VERSION ""

NS_ :

BS_:

BU_: FR C3B

BO_ 557 FR_22D: 64 FR
 SG_ FR_CRCCheck_22D : 503|16@0+ (1,0) [0|65535] ""  C3B
 SG_ FR_RollingCounter_22D : 491|4@0+ (1,0) [0|15] ""  C3B
 SG_ FR_FreespaceSectorKinestate204 : 477|2@0+ (1,0) [0|3] "-"  C3B
 SG_ FR_FreespaceSectorConRidence204 : 479|2@0+ (1,0) [0|3] "-"  C3B
 SG_ FR_FreespaceSectorDistance204 : 457|10@0+ (0.1,0) [0|100] "-"  C3B
 SG_ FR_FreespaceSectorKinestate203 : 459|2@0+ (1,0) [0|3] "-"  C3B
 SG_ FR_FreespaceSectorConRidence203 : 461|2@0+ (1,0) [0|3] "-"  C3B
 SG_ FR_FreespaceSectorDistance203 : 455|10@0+ (0.1,0) [0|100] "-"  C3B
 SG_ FR_FreespaceSectorKinestate202 : 441|2@0+ (1,0) [0|3] "-"  C3B
 SG_ FR_FreespaceSectorConRidence202 : 443|2@0+ (1,0) [0|3] "-"  C3B
 SG_ FR_FreespaceSectorDistance202 : 437|10@0+ (0.1,0) [0|100] "-"  C3B
 SG_ FR_FreespaceSectorKinestate201 : 439|2@0+ (1,0) [0|3] "-"  C3B
 SG_ FR_FreespaceSectorConRidence201 : 425|2@0+ (1,0) [0|3] "-"  C3B
 SG_ FR_FreespaceSectorDistance201 : 419|10@0+ (0.1,0) [0|100] "-"  C3B
 SG_ FR_FreespaceSectorKinestate200 : 421|2@0+ (1,0) [0|3] "-"  C3B
 SG_ FR_FreespaceSectorConRidence200 : 423|2@0+ (1,0) [0|3] "-"  C3B
 SG_ FR_FreespaceSectorDistance200 : 401|10@0+ (0.1,0) [0|100] "-"  C3B
 SG_ FR_FreespaceSectorKinestate199 : 403|2@0+ (1,0) [0|3] "-"  C3B
 SG_ FR_FreespaceSectorConRidence199 : 405|2@0+ (1,0) [0|3] "-"  C3B
 SG_ FR_FreespaceSectorDistance199 : 399|10@0+ (0.1,0) [0|100] "-"  C3B
 SG_ FR_FreespaceSectorKinestate198 : 385|2@0+ (1,0) [0|3] "-"  C3B
 SG_ FR_FreespaceSectorConRidence198 : 387|2@0+ (1,0) [0|3] "-"  C3B
 SG_ FR_FreespaceSectorDistance198 : 381|10@0+ (0.1,0) [0|100] "-"  C3B
 SG_ FR_FreespaceSectorKinestate197 : 383|2@0+ (1,0) [0|3] "-"  C3B
 SG_ FR_FreespaceSectorConRidence197 : 369|2@0+ (1,0) [0|3] "-"  C3B
 SG_ FR_FreespaceSectorDistance197 : 363|10@0+ (0.1,0) [0|100] "-"  C3B
 SG_ FR_FreespaceSectorKinestate196 : 365|2@0+ (1,0) [0|3] "-"  C3B
 SG_ FR_FreespaceSectorConRidence196 : 367|2@0+ (1,0) [0|3] "-"  C3B
 SG_ FR_FreespaceSectorDistance196 : 345|10@0+ (0.1,0) [0|100] "-"  C3B
 SG_ FR_FreespaceSectorKinestate195 : 347|2@0+ (1,0) [0|3] "-"  C3B
 SG_ FR_FreespaceSectorConRidence195 : 349|2@0+ (1,0) [0|3] "-"  C3B
 SG_ FR_FreespaceSectorDistance195 : 343|10@0+ (0.1,0) [0|100] "-"  C3B
 SG_ FR_FreespaceSectorKinestate194 : 329|2@0+ (1,0) [0|3] "-"  C3B
 SG_ FR_FreespaceSectorConRidence194 : 331|2@0+ (1,0) [0|3] "-"  C3B
 SG_ FR_FreespaceSectorDistance194 : 325|10@0+ (0.1,0) [0|100] "-"  C3B
 SG_ FR_FreespaceSectorKinestate193 : 327|2@0+ (1,0) [0|3] "-"  C3B
 SG_ FR_FreespaceSectorConRidence193 : 313|2@0+ (1,0) [0|3] "-"  C3B
 SG_ FR_FreespaceSectorDistance193 : 307|10@0+ (0.1,0) [0|100] "-"  C3B
 SG_ FR_FreespaceSectorKinestate192 : 309|2@0+ (1,0) [0|3] "-"  C3B
 SG_ FR_FreespaceSectorConRidence192 : 311|2@0+ (1,0) [0|3] "-"  C3B
 SG_ FR_FreespaceSectorDistance192 : 289|10@0+ (0.1,0) [0|100] "-"  C3B
 SG_ FR_FreespaceSectorKinestate191 : 291|2@0+ (1,0) [0|3] "-"  C3B
 SG_ FR_FreespaceSectorConRidence191 : 293|2@0+ (1,0) [0|3] "-"  C3B
 SG_ FR_FreespaceSectorDistance191 : 287|10@0+ (0.1,0) [0|100] "-"  C3B
 SG_ FR_FreespaceSectorKinestate190 : 273|2@0+ (1,0) [0|3] "-"  C3B
 SG_ FR_FreespaceSectorConRidence190 : 275|2@0+ (1,0) [0|3] "-"  C3B
 SG_ FR_FreespaceSectorDistance190 : 269|10@0+ (0.1,0) [0|100] "-"  C3B
 SG_ FR_FreespaceSectorKinestate189 : 271|2@0+ (1,0) [0|3] "-"  C3B
 SG_ FR_FreespaceSectorConRidence189 : 257|2@0+ (1,0) [0|3] "-"  C3B
 SG_ FR_FreespaceSectorDistance189 : 251|10@0+ (0.1,0) [0|100] "-"  C3B
 SG_ FR_FreespaceSectorKinestate188 : 253|2@0+ (1,0) [0|3] "-"  C3B
 SG_ FR_FreespaceSectorConRidence188 : 255|2@0+ (1,0) [0|3] "-"  C3B
 SG_ FR_FreespaceSectorDistance188 : 233|10@0+ (0.1,0) [0|100] "-"  C3B
 SG_ FR_FreespaceSectorKinestate187 : 235|2@0+ (1,0) [0|3] "-"  C3B
 SG_ FR_FreespaceSectorConRidence187 : 237|2@0+ (1,0) [0|3] "-"  C3B
 SG_ FR_FreespaceSectorDistance187 : 231|10@0+ (0.1,0) [0|100] "-"  C3B
 SG_ FR_FreespaceSectorKinestate186 : 217|2@0+ (1,0) [0|3] "-"  C3B
 SG_ FR_FreespaceSectorConRidence186 : 219|2@0+ (1,0) [0|3] "-"  C3B
 SG_ FR_FreespaceSectorDistance186 : 213|10@0+ (0.1,0) [0|100] "-"  C3B
 SG_ FR_FreespaceSectorKinestate185 : 215|2@0+ (1,0) [0|3] "-"  C3B
 SG_ FR_FreespaceSectorConRidence185 : 201|2@0+ (1,0) [0|3] "-"  C3B
 SG_ FR_FreespaceSectorDistance185 : 195|10@0+ (0.1,0) [0|100] "-"  C3B
 SG_ FR_FreespaceSectorKinestate184 : 197|2@0+ (1,0) [0|3] "-"  C3B
 SG_ FR_FreespaceSectorConRidence184 : 199|2@0+ (1,0) [0|3] "-"  C3B
 SG_ FR_FreespaceSectorDistance184 : 177|10@0+ (0.1,0) [0|100] "-"  C3B
 SG_ FR_FreespaceSectorKinestate183 : 179|2@0+ (1,0) [0|3] "-"  C3B
 SG_ FR_FreespaceSectorConRidence183 : 181|2@0+ (1,0) [0|3] "-"  C3B
 SG_ FR_FreespaceSectorDistance183 : 175|10@0+ (0.1,0) [0|100] "-"  C3B
 SG_ FR_FreespaceSectorKinestate182 : 161|2@0+ (1,0) [0|3] "-"  C3B
 SG_ FR_FreespaceSectorConRidence182 : 163|2@0+ (1,0) [0|3] "-"  C3B
 SG_ FR_FreespaceSectorDistance182 : 157|10@0+ (0.1,0) [0|100] "-"  C3B
 SG_ FR_FreespaceSectorKinestate181 : 159|2@0+ (1,0) [0|3] "-"  C3B
 SG_ FR_FreespaceSectorConRidence181 : 145|2@0+ (1,0) [0|3] "-"  C3B
 SG_ FR_FreespaceSectorDistance181 : 139|10@0+ (0.1,0) [0|100] "-"  C3B
 SG_ FR_FreespaceSectorKinestate180 : 141|2@0+ (1,0) [0|3] "-"  C3B
 SG_ FR_FreespaceSectorConRidence180 : 143|2@0+ (1,0) [0|3] "-"  C3B
 SG_ FR_FreespaceSectorDistance180 : 121|10@0+ (0.1,0) [0|100] "-"  C3B
 SG_ FR_FreespaceSectorKinestate179 : 123|2@0+ (1,0) [0|3] "-"  C3B
 SG_ FR_FreespaceSectorConRidence179 : 125|2@0+ (1,0) [0|3] "-"  C3B
 SG_ FR_FreespaceSectorDistance179 : 119|10@0+ (0.1,0) [0|100] "-"  C3B
 SG_ FR_FreespaceSectorKinestate178 : 105|2@0+ (1,0) [0|3] "-"  C3B
 SG_ FR_FreespaceSectorConRidence178 : 107|2@0+ (1,0) [0|3] "-"  C3B
 SG_ FR_FreespaceSectorDistance178 : 101|10@0+ (0.1,0) [0|100] "-"  C3B
 SG_ FR_FreespaceSectorKinestate177 : 103|2@0+ (1,0) [0|3] "-"  C3B
 SG_ FR_FreespaceSectorConRidence177 : 89|2@0+ (1,0) [0|3] "-"  C3B
 SG_ FR_FreespaceSectorDistance177 : 83|10@0+ (0.1,0) [0|100] "-"  C3B
 SG_ FR_FreespaceSectorKinestate176 : 85|2@0+ (1,0) [0|3] "-"  C3B
 SG_ FR_FreespaceSectorConRidence176 : 87|2@0+ (1,0) [0|3] "-"  C3B
 SG_ FR_FreespaceSectorDistance176 : 65|10@0+ (0.1,0) [0|100] "-"  C3B
 SG_ FR_FreespaceSectorKinestate175 : 67|2@0+ (1,0) [0|3] "-"  C3B
 SG_ FR_FreespaceSectorConRidence175 : 69|2@0+ (1,0) [0|3] "-"  C3B
 SG_ FR_FreespaceSectorDistance175 : 63|10@0+ (0.1,0) [0|100] "-"  C3B
 SG_ FR_FreespaceSectorKinestate174 : 49|2@0+ (1,0) [0|3] "-"  C3B
 SG_ FR_FreespaceSectorConRidence174 : 51|2@0+ (1,0) [0|3] "-"  C3B
 SG_ FR_FreespaceSectorDistance174 : 45|10@0+ (0.1,0) [0|100] "-"  C3B
 SG_ FR_FreespaceSectorKinestate173 : 47|2@0+ (1,0) [0|3] "-"  C3B
 SG_ FR_FreespaceSectorConRidence173 : 33|2@0+ (1,0) [0|3] "-"  C3B
 SG_ FR_FreespaceSectorDistance173 : 27|10@0+ (0.1,0) [0|100] "-"  C3B
 SG_ FR_FreespaceSectorKinestate172 : 29|2@0+ (1,0) [0|3] "-"  C3B
 SG_ FR_FreespaceSectorConRidence172 : 31|2@0+ (1,0) [0|3] "-"  C3B
 SG_ FR_FreespaceSectorDistance172 : 9|10@0+ (0.1,0) [0|100] "-"  C3B
 SG_ FR_FreespaceSectorKinestate171 : 11|2@0+ (1,0) [0|3] "-"  C3B
 SG_ FR_FreespaceSectorConRidence171 : 13|2@0+ (1,0) [0|3] "-"  C3B
 SG_ FR_FreespaceSectorDistance171 : 7|10@0+ (0.1,0) [0|100] "-"  C3B

BO_ 558 FR_22E: 64 FR
 SG_ FR_CRCCheck_22E : 503|16@0+ (1,0) [0|65535] ""  C3B
 SG_ FR_RollingCounter_22E : 491|4@0+ (1,0) [0|15] ""  C3B
 SG_ FR_FreespaceSectorKinestate238 : 477|2@0+ (1,0) [0|3] "-"  C3B
 SG_ FR_FreespaceSectorConRidence238 : 479|2@0+ (1,0) [0|3] "-"  C3B
 SG_ FR_FreespaceSectorDistance238 : 457|10@0+ (0.1,0) [0|100] "-"  C3B
 SG_ FR_FreespaceSectorKinestate237 : 459|2@0+ (1,0) [0|3] "-"  C3B
 SG_ FR_FreespaceSectorConRidence237 : 461|2@0+ (1,0) [0|3] "-"  C3B
 SG_ FR_FreespaceSectorDistance237 : 455|10@0+ (0.1,0) [0|100] "-"  C3B
 SG_ FR_FreespaceSectorKinestate236 : 441|2@0+ (1,0) [0|3] "-"  C3B
 SG_ FR_FreespaceSectorConRidence236 : 443|2@0+ (1,0) [0|3] "-"  C3B
 SG_ FR_FreespaceSectorDistance236 : 437|10@0+ (0.1,0) [0|100] "-"  C3B
 SG_ FR_FreespaceSectorKinestate235 : 439|2@0+ (1,0) [0|3] "-"  C3B
 SG_ FR_FreespaceSectorConRidence235 : 425|2@0+ (1,0) [0|3] "-"  C3B
 SG_ FR_FreespaceSectorDistance235 : 419|10@0+ (0.1,0) [0|100] "-"  C3B
 SG_ FR_FreespaceSectorKinestate234 : 421|2@0+ (1,0) [0|3] "-"  C3B
 SG_ FR_FreespaceSectorConRidence234 : 423|2@0+ (1,0) [0|3] "-"  C3B
 SG_ FR_FreespaceSectorDistance234 : 401|10@0+ (0.1,0) [0|100] "-"  C3B
 SG_ FR_FreespaceSectorKinestate233 : 403|2@0+ (1,0) [0|3] "-"  C3B
 SG_ FR_FreespaceSectorConRidence233 : 405|2@0+ (1,0) [0|3] "-"  C3B
 SG_ FR_FreespaceSectorDistance233 : 399|10@0+ (0.1,0) [0|100] "-"  C3B
 SG_ FR_FreespaceSectorKinestate232 : 385|2@0+ (1,0) [0|3] "-"  C3B
 SG_ FR_FreespaceSectorConRidence232 : 387|2@0+ (1,0) [0|3] "-"  C3B
 SG_ FR_FreespaceSectorDistance232 : 381|10@0+ (0.1,0) [0|100] "-"  C3B
 SG_ FR_FreespaceSectorKinestate231 : 383|2@0+ (1,0) [0|3] "-"  C3B
 SG_ FR_FreespaceSectorConRidence231 : 369|2@0+ (1,0) [0|3] "-"  C3B
 SG_ FR_FreespaceSectorDistance231 : 363|10@0+ (0.1,0) [0|100] "-"  C3B
 SG_ FR_FreespaceSectorKinestate230 : 365|2@0+ (1,0) [0|3] "-"  C3B
 SG_ FR_FreespaceSectorConRidence230 : 367|2@0+ (1,0) [0|3] "-"  C3B
 SG_ FR_FreespaceSectorDistance230 : 345|10@0+ (0.1,0) [0|100] "-"  C3B
 SG_ FR_FreespaceSectorKinestate229 : 347|2@0+ (1,0) [0|3] "-"  C3B
 SG_ FR_FreespaceSectorConRidence229 : 349|2@0+ (1,0) [0|3] "-"  C3B
 SG_ FR_FreespaceSectorDistance229 : 343|10@0+ (0.1,0) [0|100] "-"  C3B
 SG_ FR_FreespaceSectorKinestate228 : 329|2@0+ (1,0) [0|3] "-"  C3B
 SG_ FR_FreespaceSectorConRidence228 : 331|2@0+ (1,0) [0|3] "-"  C3B
 SG_ FR_FreespaceSectorDistance228 : 325|10@0+ (0.1,0) [0|100] "-"  C3B
 SG_ FR_FreespaceSectorKinestate227 : 327|2@0+ (1,0) [0|3] "-"  C3B
 SG_ FR_FreespaceSectorConRidence227 : 313|2@0+ (1,0) [0|3] "-"  C3B
 SG_ FR_FreespaceSectorDistance227 : 307|10@0+ (0.1,0) [0|100] "-"  C3B
 SG_ FR_FreespaceSectorKinestate226 : 309|2@0+ (1,0) [0|3] "-"  C3B
 SG_ FR_FreespaceSectorConRidence226 : 311|2@0+ (1,0) [0|3] "-"  C3B
 SG_ FR_FreespaceSectorDistance226 : 289|10@0+ (0.1,0) [0|100] "-"  C3B
 SG_ FR_FreespaceSectorKinestate225 : 291|2@0+ (1,0) [0|3] "-"  C3B
 SG_ FR_FreespaceSectorConRidence225 : 293|2@0+ (1,0) [0|3] "-"  C3B
 SG_ FR_FreespaceSectorDistance225 : 287|10@0+ (0.1,0) [0|100] "-"  C3B
 SG_ FR_FreespaceSectorKinestate224 : 273|2@0+ (1,0) [0|3] "-"  C3B
 SG_ FR_FreespaceSectorConRidence224 : 275|2@0+ (1,0) [0|3] "-"  C3B
 SG_ FR_FreespaceSectorDistance224 : 269|10@0+ (0.1,0) [0|100] "-"  C3B
 SG_ FR_FreespaceSectorKinestate223 : 271|2@0+ (1,0) [0|3] "-"  C3B
 SG_ FR_FreespaceSectorConRidence223 : 257|2@0+ (1,0) [0|3] "-"  C3B
 SG_ FR_FreespaceSectorDistance223 : 251|10@0+ (0.1,0) [0|100] "-"  C3B
 SG_ FR_FreespaceSectorKinestate222 : 253|2@0+ (1,0) [0|3] "-"  C3B
 SG_ FR_FreespaceSectorConRidence222 : 255|2@0+ (1,0) [0|3] "-"  C3B
 SG_ FR_FreespaceSectorDistance222 : 233|10@0+ (0.1,0) [0|100] "-"  C3B
 SG_ FR_FreespaceSectorKinestate221 : 235|2@0+ (1,0) [0|3] "-"  C3B
 SG_ FR_FreespaceSectorConRidence221 : 237|2@0+ (1,0) [0|3] "-"  C3B
 SG_ FR_FreespaceSectorDistance221 : 231|10@0+ (0.1,0) [0|100] "-"  C3B
 SG_ FR_FreespaceSectorKinestate220 : 217|2@0+ (1,0) [0|3] "-"  C3B
 SG_ FR_FreespaceSectorConRidence220 : 219|2@0+ (1,0) [0|3] "-"  C3B
 SG_ FR_FreespaceSectorDistance220 : 213|10@0+ (0.1,0) [0|100] "-"  C3B
 SG_ FR_FreespaceSectorKinestate219 : 215|2@0+ (1,0) [0|3] "-"  C3B
 SG_ FR_FreespaceSectorConRidence219 : 201|2@0+ (1,0) [0|3] "-"  C3B
 SG_ FR_FreespaceSectorDistance219 : 195|10@0+ (0.1,0) [0|100] "-"  C3B
 SG_ FR_FreespaceSectorKinestate218 : 197|2@0+ (1,0) [0|3] "-"  C3B
 SG_ FR_FreespaceSectorConRidence218 : 199|2@0+ (1,0) [0|3] "-"  C3B
 SG_ FR_FreespaceSectorDistance218 : 177|10@0+ (0.1,0) [0|100] "-"  C3B
 SG_ FR_FreespaceSectorKinestate217 : 179|2@0+ (1,0) [0|3] "-"  C3B
 SG_ FR_FreespaceSectorConRidence217 : 181|2@0+ (1,0) [0|3] "-"  C3B
 SG_ FR_FreespaceSectorDistance217 : 175|10@0+ (0.1,0) [0|100] "-"  C3B
 SG_ FR_FreespaceSectorKinestate216 : 161|2@0+ (1,0) [0|3] "-"  C3B
 SG_ FR_FreespaceSectorConRidence216 : 163|2@0+ (1,0) [0|3] "-"  C3B
 SG_ FR_FreespaceSectorDistance216 : 157|10@0+ (0.1,0) [0|100] "-"  C3B
 SG_ FR_FreespaceSectorKinestate215 : 159|2@0+ (1,0) [0|3] "-"  C3B
 SG_ FR_FreespaceSectorConRidence215 : 145|2@0+ (1,0) [0|3] "-"  C3B
 SG_ FR_FreespaceSectorDistance215 : 139|10@0+ (0.1,0) [0|100] "-"  C3B
 SG_ FR_FreespaceSectorKinestate214 : 141|2@0+ (1,0) [0|3] "-"  C3B
 SG_ FR_FreespaceSectorConRidence214 : 143|2@0+ (1,0) [0|3] "-"  C3B
 SG_ FR_FreespaceSectorDistance214 : 121|10@0+ (0.1,0) [0|100] "-"  C3B
 SG_ FR_FreespaceSectorKinestate213 : 123|2@0+ (1,0) [0|3] "-"  C3B
 SG_ FR_FreespaceSectorConRidence213 : 125|2@0+ (1,0) [0|3] "-"  C3B
 SG_ FR_FreespaceSectorDistance213 : 119|10@0+ (0.1,0) [0|100] "-"  C3B
 SG_ FR_FreespaceSectorKinestate212 : 105|2@0+ (1,0) [0|3] "-"  C3B
 SG_ FR_FreespaceSectorConRidence212 : 107|2@0+ (1,0) [0|3] "-"  C3B
 SG_ FR_FreespaceSectorDistance212 : 101|10@0+ (0.1,0) [0|100] "-"  C3B
 SG_ FR_FreespaceSectorKinestate211 : 103|2@0+ (1,0) [0|3] "-"  C3B
 SG_ FR_FreespaceSectorConRidence211 : 89|2@0+ (1,0) [0|3] "-"  C3B
 SG_ FR_FreespaceSectorDistance211 : 83|10@0+ (0.1,0) [0|100] "-"  C3B
 SG_ FR_FreespaceSectorKinestate210 : 85|2@0+ (1,0) [0|3] "-"  C3B
 SG_ FR_FreespaceSectorConRidence210 : 87|2@0+ (1,0) [0|3] "-"  C3B
 SG_ FR_FreespaceSectorDistance210 : 65|10@0+ (0.1,0) [0|100] "-"  C3B
 SG_ FR_FreespaceSectorKinestate209 : 67|2@0+ (1,0) [0|3] "-"  C3B
 SG_ FR_FreespaceSectorConRidence209 : 69|2@0+ (1,0) [0|3] "-"  C3B
 SG_ FR_FreespaceSectorDistance209 : 63|10@0+ (0.1,0) [0|100] "-"  C3B
 SG_ FR_FreespaceSectorKinestate208 : 49|2@0+ (1,0) [0|3] "-"  C3B
 SG_ FR_FreespaceSectorConRidence208 : 51|2@0+ (1,0) [0|3] "-"  C3B
 SG_ FR_FreespaceSectorDistance208 : 45|10@0+ (0.1,0) [0|100] "-"  C3B
 SG_ FR_FreespaceSectorKinestate207 : 47|2@0+ (1,0) [0|3] "-"  C3B
 SG_ FR_FreespaceSectorConRidence207 : 33|2@0+ (1,0) [0|3] "-"  C3B
 SG_ FR_FreespaceSectorDistance207 : 27|10@0+ (0.1,0) [0|100] "-"  C3B
 SG_ FR_FreespaceSectorKinestate206 : 29|2@0+ (1,0) [0|3] "-"  C3B
 SG_ FR_FreespaceSectorConRidence206 : 31|2@0+ (1,0) [0|3] "-"  C3B
 SG_ FR_FreespaceSectorDistance206 : 9|10@0+ (0.1,0) [0|100] "-"  C3B
 SG_ FR_FreespaceSectorKinestate205 : 11|2@0+ (1,0) [0|3] "-"  C3B
 SG_ FR_FreespaceSectorConRidence205 : 13|2@0+ (1,0) [0|3] "-"  C3B
 SG_ FR_FreespaceSectorDistance205 : 7|10@0+ (0.1,0) [0|100] "-"  C3B

BO_ 559 FR_22F: 64 FR
 SG_ FR_CRCCheck_22F : 503|16@0+ (1,0) [0|65535] ""  C3B
 SG_ FR_RollingCounter_22F : 491|4@0+ (1,0) [0|15] ""  C3B
 SG_ FR_FreespaceSectorKinestate272 : 477|2@0+ (1,0) [0|3] "-"  C3B
 SG_ FR_FreespaceSectorConRidence272 : 479|2@0+ (1,0) [0|3] "-"  C3B
 SG_ FR_FreespaceSectorDistance272 : 457|10@0+ (0.1,0) [0|100] "-"  C3B
 SG_ FR_FreespaceSectorKinestate271 : 459|2@0+ (1,0) [0|3] "-"  C3B
 SG_ FR_FreespaceSectorConRidence271 : 461|2@0+ (1,0) [0|3] "-"  C3B
 SG_ FR_FreespaceSectorDistance271 : 455|10@0+ (0.1,0) [0|100] "-"  C3B
 SG_ FR_FreespaceSectorKinestate270 : 441|2@0+ (1,0) [0|3] "-"  C3B
 SG_ FR_FreespaceSectorConRidence270 : 443|2@0+ (1,0) [0|3] "-"  C3B
 SG_ FR_FreespaceSectorDistance270 : 437|10@0+ (0.1,0) [0|100] "-"  C3B
 SG_ FR_FreespaceSectorKinestate269 : 439|2@0+ (1,0) [0|3] "-"  C3B
 SG_ FR_FreespaceSectorConRidence269 : 425|2@0+ (1,0) [0|3] "-"  C3B
 SG_ FR_FreespaceSectorDistance269 : 419|10@0+ (0.1,0) [0|100] "-"  C3B
 SG_ FR_FreespaceSectorKinestate268 : 421|2@0+ (1,0) [0|3] "-"  C3B
 SG_ FR_FreespaceSectorConRidence268 : 423|2@0+ (1,0) [0|3] "-"  C3B
 SG_ FR_FreespaceSectorDistance268 : 401|10@0+ (0.1,0) [0|100] "-"  C3B
 SG_ FR_FreespaceSectorKinestate267 : 403|2@0+ (1,0) [0|3] "-"  C3B
 SG_ FR_FreespaceSectorConRidence267 : 405|2@0+ (1,0) [0|3] "-"  C3B
 SG_ FR_FreespaceSectorDistance267 : 399|10@0+ (0.1,0) [0|100] "-"  C3B
 SG_ FR_FreespaceSectorKinestate266 : 385|2@0+ (1,0) [0|3] "-"  C3B
 SG_ FR_FreespaceSectorConRidence266 : 387|2@0+ (1,0) [0|3] "-"  C3B
 SG_ FR_FreespaceSectorDistance266 : 381|10@0+ (0.1,0) [0|100] "-"  C3B
 SG_ FR_FreespaceSectorKinestate265 : 383|2@0+ (1,0) [0|3] "-"  C3B
 SG_ FR_FreespaceSectorConRidence265 : 369|2@0+ (1,0) [0|3] "-"  C3B
 SG_ FR_FreespaceSectorDistance265 : 363|10@0+ (0.1,0) [0|100] "-"  C3B
 SG_ FR_FreespaceSectorKinestate264 : 365|2@0+ (1,0) [0|3] "-"  C3B
 SG_ FR_FreespaceSectorConRidence264 : 367|2@0+ (1,0) [0|3] "-"  C3B
 SG_ FR_FreespaceSectorDistance264 : 345|10@0+ (0.1,0) [0|100] "-"  C3B
 SG_ FR_FreespaceSectorKinestate263 : 347|2@0+ (1,0) [0|3] "-"  C3B
 SG_ FR_FreespaceSectorConRidence263 : 349|2@0+ (1,0) [0|3] "-"  C3B
 SG_ FR_FreespaceSectorDistance263 : 343|10@0+ (0.1,0) [0|100] "-"  C3B
 SG_ FR_FreespaceSectorKinestate262 : 329|2@0+ (1,0) [0|3] "-"  C3B
 SG_ FR_FreespaceSectorConRidence262 : 331|2@0+ (1,0) [0|3] "-"  C3B
 SG_ FR_FreespaceSectorDistance262 : 325|10@0+ (0.1,0) [0|100] "-"  C3B
 SG_ FR_FreespaceSectorKinestate261 : 327|2@0+ (1,0) [0|3] "-"  C3B
 SG_ FR_FreespaceSectorConRidence261 : 313|2@0+ (1,0) [0|3] "-"  C3B
 SG_ FR_FreespaceSectorDistance261 : 307|10@0+ (0.1,0) [0|100] "-"  C3B
 SG_ FR_FreespaceSectorKinestate260 : 309|2@0+ (1,0) [0|3] "-"  C3B
 SG_ FR_FreespaceSectorConRidence260 : 311|2@0+ (1,0) [0|3] "-"  C3B
 SG_ FR_FreespaceSectorDistance260 : 289|10@0+ (0.1,0) [0|100] "-"  C3B
 SG_ FR_FreespaceSectorKinestate259 : 291|2@0+ (1,0) [0|3] "-"  C3B
 SG_ FR_FreespaceSectorConRidence259 : 293|2@0+ (1,0) [0|3] "-"  C3B
 SG_ FR_FreespaceSectorDistance259 : 287|10@0+ (0.1,0) [0|100] "-"  C3B
 SG_ FR_FreespaceSectorKinestate258 : 273|2@0+ (1,0) [0|3] "-"  C3B
 SG_ FR_FreespaceSectorConRidence258 : 275|2@0+ (1,0) [0|3] "-"  C3B
 SG_ FR_FreespaceSectorDistance258 : 269|10@0+ (0.1,0) [0|100] "-"  C3B
 SG_ FR_FreespaceSectorKinestate257 : 271|2@0+ (1,0) [0|3] "-"  C3B
 SG_ FR_FreespaceSectorConRidence257 : 257|2@0+ (1,0) [0|3] "-"  C3B
 SG_ FR_FreespaceSectorDistance257 : 251|10@0+ (0.1,0) [0|100] "-"  C3B
 SG_ FR_FreespaceSectorKinestate256 : 253|2@0+ (1,0) [0|3] "-"  C3B
 SG_ FR_FreespaceSectorConRidence256 : 255|2@0+ (1,0) [0|3] "-"  C3B
 SG_ FR_FreespaceSectorDistance256 : 233|10@0+ (0.1,0) [0|100] "-"  C3B
 SG_ FR_FreespaceSectorKinestate255 : 235|2@0+ (1,0) [0|3] "-"  C3B
 SG_ FR_FreespaceSectorConRidence255 : 237|2@0+ (1,0) [0|3] "-"  C3B
 SG_ FR_FreespaceSectorDistance255 : 231|10@0+ (0.1,0) [0|100] "-"  C3B
 SG_ FR_FreespaceSectorKinestate254 : 217|2@0+ (1,0) [0|3] "-"  C3B
 SG_ FR_FreespaceSectorConRidence254 : 219|2@0+ (1,0) [0|3] "-"  C3B
 SG_ FR_FreespaceSectorDistance254 : 213|10@0+ (0.1,0) [0|100] "-"  C3B
 SG_ FR_FreespaceSectorKinestate253 : 215|2@0+ (1,0) [0|3] "-"  C3B
 SG_ FR_FreespaceSectorConRidence253 : 201|2@0+ (1,0) [0|3] "-"  C3B
 SG_ FR_FreespaceSectorDistance253 : 195|10@0+ (0.1,0) [0|100] "-"  C3B
 SG_ FR_FreespaceSectorKinestate252 : 197|2@0+ (1,0) [0|3] "-"  C3B
 SG_ FR_FreespaceSectorConRidence252 : 199|2@0+ (1,0) [0|3] "-"  C3B
 SG_ FR_FreespaceSectorDistance252 : 177|10@0+ (0.1,0) [0|100] "-"  C3B
 SG_ FR_FreespaceSectorKinestate251 : 179|2@0+ (1,0) [0|3] "-"  C3B
 SG_ FR_FreespaceSectorConRidence251 : 181|2@0+ (1,0) [0|3] "-"  C3B
 SG_ FR_FreespaceSectorDistance251 : 175|10@0+ (0.1,0) [0|100] "-"  C3B
 SG_ FR_FreespaceSectorKinestate250 : 161|2@0+ (1,0) [0|3] "-"  C3B
 SG_ FR_FreespaceSectorConRidence250 : 163|2@0+ (1,0) [0|3] "-"  C3B
 SG_ FR_FreespaceSectorDistance250 : 157|10@0+ (0.1,0) [0|100] "-"  C3B
 SG_ FR_FreespaceSectorKinestate249 : 159|2@0+ (1,0) [0|3] "-"  C3B
 SG_ FR_FreespaceSectorConRidence249 : 145|2@0+ (1,0) [0|3] "-"  C3B
 SG_ FR_FreespaceSectorDistance249 : 139|10@0+ (0.1,0) [0|100] "-"  C3B
 SG_ FR_FreespaceSectorKinestate248 : 141|2@0+ (1,0) [0|3] "-"  C3B
 SG_ FR_FreespaceSectorConRidence248 : 143|2@0+ (1,0) [0|3] "-"  C3B
 SG_ FR_FreespaceSectorDistance248 : 121|10@0+ (0.1,0) [0|100] "-"  C3B
 SG_ FR_FreespaceSectorKinestate247 : 123|2@0+ (1,0) [0|3] "-"  C3B
 SG_ FR_FreespaceSectorConRidence247 : 125|2@0+ (1,0) [0|3] "-"  C3B
 SG_ FR_FreespaceSectorDistance247 : 119|10@0+ (0.1,0) [0|100] "-"  C3B
 SG_ FR_FreespaceSectorKinestate246 : 105|2@0+ (1,0) [0|3] "-"  C3B
 SG_ FR_FreespaceSectorConRidence246 : 107|2@0+ (1,0) [0|3] "-"  C3B
 SG_ FR_FreespaceSectorDistance246 : 101|10@0+ (0.1,0) [0|100] "-"  C3B
 SG_ FR_FreespaceSectorKinestate245 : 103|2@0+ (1,0) [0|3] "-"  C3B
 SG_ FR_FreespaceSectorConRidence245 : 89|2@0+ (1,0) [0|3] "-"  C3B
 SG_ FR_FreespaceSectorDistance245 : 83|10@0+ (0.1,0) [0|100] "-"  C3B
 SG_ FR_FreespaceSectorKinestate244 : 85|2@0+ (1,0) [0|3] "-"  C3B
 SG_ FR_FreespaceSectorConRidence244 : 87|2@0+ (1,0) [0|3] "-"  C3B
 SG_ FR_FreespaceSectorDistance244 : 65|10@0+ (0.1,0) [0|100] "-"  C3B
 SG_ FR_FreespaceSectorKinestate243 : 67|2@0+ (1,0) [0|3] "-"  C3B
 SG_ FR_FreespaceSectorConRidence243 : 69|2@0+ (1,0) [0|3] "-"  C3B
 SG_ FR_FreespaceSectorDistance243 : 63|10@0+ (0.1,0) [0|100] "-"  C3B
 SG_ FR_FreespaceSectorKinestate242 : 49|2@0+ (1,0) [0|3] "-"  C3B
 SG_ FR_FreespaceSectorConRidence242 : 51|2@0+ (1,0) [0|3] "-"  C3B
 SG_ FR_FreespaceSectorDistance242 : 45|10@0+ (0.1,0) [0|100] "-"  C3B
 SG_ FR_FreespaceSectorKinestate241 : 47|2@0+ (1,0) [0|3] "-"  C3B
 SG_ FR_FreespaceSectorConRidence241 : 33|2@0+ (1,0) [0|3] "-"  C3B
 SG_ FR_FreespaceSectorDistance241 : 27|10@0+ (0.1,0) [0|100] "-"  C3B
 SG_ FR_FreespaceSectorKinestate240 : 29|2@0+ (1,0) [0|3] "-"  C3B
 SG_ FR_FreespaceSectorConRidence240 : 31|2@0+ (1,0) [0|3] "-"  C3B
 SG_ FR_FreespaceSectorDistance240 : 9|10@0+ (0.1,0) [0|100] "-"  C3B
 SG_ FR_FreespaceSectorKinestate239 : 11|2@0+ (1,0) [0|3] "-"  C3B
 SG_ FR_FreespaceSectorConRidence239 : 13|2@0+ (1,0) [0|3] "-"  C3B
 SG_ FR_FreespaceSectorDistance239 : 7|10@0+ (0.1,0) [0|100] "-"  C3B

BO_ 560 FR_230: 64 FR
 SG_ FR_CRCCheck_230 : 503|16@0+ (1,0) [0|65535] ""  C3B
 SG_ FR_RollingCounter_230 : 491|4@0+ (1,0) [0|15] ""  C3B
 SG_ FR_FreespaceSectorKinestate306 : 477|2@0+ (1,0) [0|3] "-"  C3B
 SG_ FR_FreespaceSectorConRidence306 : 479|2@0+ (1,0) [0|3] "-"  C3B
 SG_ FR_FreespaceSectorDistance306 : 457|10@0+ (0.1,0) [0|100] "-"  C3B
 SG_ FR_FreespaceSectorKinestate305 : 459|2@0+ (1,0) [0|3] "-"  C3B
 SG_ FR_FreespaceSectorConRidence305 : 461|2@0+ (1,0) [0|3] "-"  C3B
 SG_ FR_FreespaceSectorDistance305 : 455|10@0+ (0.1,0) [0|100] "-"  C3B
 SG_ FR_FreespaceSectorKinestate304 : 441|2@0+ (1,0) [0|3] "-"  C3B
 SG_ FR_FreespaceSectorConRidence304 : 443|2@0+ (1,0) [0|3] "-"  C3B
 SG_ FR_FreespaceSectorDistance304 : 437|10@0+ (0.1,0) [0|100] "-"  C3B
 SG_ FR_FreespaceSectorKinestate303 : 439|2@0+ (1,0) [0|3] "-"  C3B
 SG_ FR_FreespaceSectorConRidence303 : 425|2@0+ (1,0) [0|3] "-"  C3B
 SG_ FR_FreespaceSectorDistance303 : 419|10@0+ (0.1,0) [0|100] "-"  C3B
 SG_ FR_FreespaceSectorKinestate302 : 421|2@0+ (1,0) [0|3] "-"  C3B
 SG_ FR_FreespaceSectorConRidence302 : 423|2@0+ (1,0) [0|3] "-"  C3B
 SG_ FR_FreespaceSectorDistance302 : 401|10@0+ (0.1,0) [0|100] "-"  C3B
 SG_ FR_FreespaceSectorKinestate301 : 403|2@0+ (1,0) [0|3] "-"  C3B
 SG_ FR_FreespaceSectorConRidence301 : 405|2@0+ (1,0) [0|3] "-"  C3B
 SG_ FR_FreespaceSectorDistance301 : 399|10@0+ (0.1,0) [0|100] "-"  C3B
 SG_ FR_FreespaceSectorKinestate300 : 385|2@0+ (1,0) [0|3] "-"  C3B
 SG_ FR_FreespaceSectorConRidence300 : 387|2@0+ (1,0) [0|3] "-"  C3B
 SG_ FR_FreespaceSectorDistance300 : 381|10@0+ (0.1,0) [0|100] "-"  C3B
 SG_ FR_FreespaceSectorKinestate299 : 383|2@0+ (1,0) [0|3] "-"  C3B
 SG_ FR_FreespaceSectorConRidence299 : 369|2@0+ (1,0) [0|3] "-"  C3B
 SG_ FR_FreespaceSectorDistance299 : 363|10@0+ (0.1,0) [0|100] "-"  C3B
 SG_ FR_FreespaceSectorKinestate298 : 365|2@0+ (1,0) [0|3] "-"  C3B
 SG_ FR_FreespaceSectorConRidence298 : 367|2@0+ (1,0) [0|3] "-"  C3B
 SG_ FR_FreespaceSectorDistance298 : 345|10@0+ (0.1,0) [0|100] "-"  C3B
 SG_ FR_FreespaceSectorKinestate297 : 347|2@0+ (1,0) [0|3] "-"  C3B
 SG_ FR_FreespaceSectorConRidence297 : 349|2@0+ (1,0) [0|3] "-"  C3B
 SG_ FR_FreespaceSectorDistance297 : 343|10@0+ (0.1,0) [0|100] "-"  C3B
 SG_ FR_FreespaceSectorKinestate296 : 329|2@0+ (1,0) [0|3] "-"  C3B
 SG_ FR_FreespaceSectorConRidence296 : 331|2@0+ (1,0) [0|3] "-"  C3B
 SG_ FR_FreespaceSectorDistance296 : 325|10@0+ (0.1,0) [0|100] "-"  C3B
 SG_ FR_FreespaceSectorKinestate295 : 327|2@0+ (1,0) [0|3] "-"  C3B
 SG_ FR_FreespaceSectorConRidence295 : 313|2@0+ (1,0) [0|3] "-"  C3B
 SG_ FR_FreespaceSectorDistance295 : 307|10@0+ (0.1,0) [0|100] "-"  C3B
 SG_ FR_FreespaceSectorKinestate294 : 309|2@0+ (1,0) [0|3] "-"  C3B
 SG_ FR_FreespaceSectorConRidence294 : 311|2@0+ (1,0) [0|3] "-"  C3B
 SG_ FR_FreespaceSectorDistance294 : 289|10@0+ (0.1,0) [0|100] "-"  C3B
 SG_ FR_FreespaceSectorKinestate293 : 291|2@0+ (1,0) [0|3] "-"  C3B
 SG_ FR_FreespaceSectorConRidence293 : 293|2@0+ (1,0) [0|3] "-"  C3B
 SG_ FR_FreespaceSectorDistance293 : 287|10@0+ (0.1,0) [0|100] "-"  C3B
 SG_ FR_FreespaceSectorKinestate292 : 273|2@0+ (1,0) [0|3] "-"  C3B
 SG_ FR_FreespaceSectorConRidence292 : 275|2@0+ (1,0) [0|3] "-"  C3B
 SG_ FR_FreespaceSectorDistance292 : 269|10@0+ (0.1,0) [0|100] "-"  C3B
 SG_ FR_FreespaceSectorKinestate291 : 271|2@0+ (1,0) [0|3] "-"  C3B
 SG_ FR_FreespaceSectorConRidence291 : 257|2@0+ (1,0) [0|3] "-"  C3B
 SG_ FR_FreespaceSectorDistance291 : 251|10@0+ (0.1,0) [0|100] "-"  C3B
 SG_ FR_FreespaceSectorKinestate290 : 253|2@0+ (1,0) [0|3] "-"  C3B
 SG_ FR_FreespaceSectorConRidence290 : 255|2@0+ (1,0) [0|3] "-"  C3B
 SG_ FR_FreespaceSectorDistance290 : 233|10@0+ (0.1,0) [0|100] "-"  C3B
 SG_ FR_FreespaceSectorKinestate289 : 235|2@0+ (1,0) [0|3] "-"  C3B
 SG_ FR_FreespaceSectorConRidence289 : 237|2@0+ (1,0) [0|3] "-"  C3B
 SG_ FR_FreespaceSectorDistance289 : 231|10@0+ (0.1,0) [0|100] "-"  C3B
 SG_ FR_FreespaceSectorKinestate288 : 217|2@0+ (1,0) [0|3] "-"  C3B
 SG_ FR_FreespaceSectorConRidence288 : 219|2@0+ (1,0) [0|3] "-"  C3B
 SG_ FR_FreespaceSectorDistance288 : 213|10@0+ (0.1,0) [0|100] "-"  C3B
 SG_ FR_FreespaceSectorKinestate287 : 215|2@0+ (1,0) [0|3] "-"  C3B
 SG_ FR_FreespaceSectorConRidence287 : 201|2@0+ (1,0) [0|3] "-"  C3B
 SG_ FR_FreespaceSectorDistance287 : 195|10@0+ (0.1,0) [0|100] "-"  C3B
 SG_ FR_FreespaceSectorKinestate286 : 197|2@0+ (1,0) [0|3] "-"  C3B
 SG_ FR_FreespaceSectorConRidence286 : 199|2@0+ (1,0) [0|3] "-"  C3B
 SG_ FR_FreespaceSectorDistance286 : 177|10@0+ (0.1,0) [0|100] "-"  C3B
 SG_ FR_FreespaceSectorKinestate285 : 179|2@0+ (1,0) [0|3] "-"  C3B
 SG_ FR_FreespaceSectorConRidence285 : 181|2@0+ (1,0) [0|3] "-"  C3B
 SG_ FR_FreespaceSectorDistance285 : 175|10@0+ (0.1,0) [0|100] "-"  C3B
 SG_ FR_FreespaceSectorKinestate284 : 161|2@0+ (1,0) [0|3] "-"  C3B
 SG_ FR_FreespaceSectorConRidence284 : 163|2@0+ (1,0) [0|3] "-"  C3B
 SG_ FR_FreespaceSectorDistance284 : 157|10@0+ (0.1,0) [0|100] "-"  C3B
 SG_ FR_FreespaceSectorKinestate283 : 159|2@0+ (1,0) [0|3] "-"  C3B
 SG_ FR_FreespaceSectorConRidence283 : 145|2@0+ (1,0) [0|3] "-"  C3B
 SG_ FR_FreespaceSectorDistance283 : 139|10@0+ (0.1,0) [0|100] "-"  C3B
 SG_ FR_FreespaceSectorKinestate282 : 141|2@0+ (1,0) [0|3] "-"  C3B
 SG_ FR_FreespaceSectorConRidence282 : 143|2@0+ (1,0) [0|3] "-"  C3B
 SG_ FR_FreespaceSectorDistance282 : 121|10@0+ (0.1,0) [0|100] "-"  C3B
 SG_ FR_FreespaceSectorKinestate281 : 123|2@0+ (1,0) [0|3] "-"  C3B
 SG_ FR_FreespaceSectorConRidence281 : 125|2@0+ (1,0) [0|3] "-"  C3B
 SG_ FR_FreespaceSectorDistance281 : 119|10@0+ (0.1,0) [0|100] "-"  C3B
 SG_ FR_FreespaceSectorKinestate280 : 105|2@0+ (1,0) [0|3] "-"  C3B
 SG_ FR_FreespaceSectorConRidence280 : 107|2@0+ (1,0) [0|3] "-"  C3B
 SG_ FR_FreespaceSectorDistance280 : 101|10@0+ (0.1,0) [0|100] "-"  C3B
 SG_ FR_FreespaceSectorKinestate279 : 103|2@0+ (1,0) [0|3] "-"  C3B
 SG_ FR_FreespaceSectorConRidence279 : 89|2@0+ (1,0) [0|3] "-"  C3B
 SG_ FR_FreespaceSectorDistance279 : 83|10@0+ (0.1,0) [0|100] "-"  C3B
 SG_ FR_FreespaceSectorKinestate278 : 85|2@0+ (1,0) [0|3] "-"  C3B
 SG_ FR_FreespaceSectorConRidence278 : 87|2@0+ (1,0) [0|3] "-"  C3B
 SG_ FR_FreespaceSectorDistance278 : 65|10@0+ (0.1,0) [0|100] "-"  C3B
 SG_ FR_FreespaceSectorKinestate277 : 67|2@0+ (1,0) [0|3] "-"  C3B
 SG_ FR_FreespaceSectorConRidence277 : 69|2@0+ (1,0) [0|3] "-"  C3B
 SG_ FR_FreespaceSectorDistance277 : 63|10@0+ (0.1,0) [0|100] "-"  C3B
 SG_ FR_FreespaceSectorKinestate276 : 49|2@0+ (1,0) [0|3] "-"  C3B
 SG_ FR_FreespaceSectorConRidence276 : 51|2@0+ (1,0) [0|3] "-"  C3B
 SG_ FR_FreespaceSectorDistance276 : 45|10@0+ (0.1,0) [0|100] "-"  C3B
 SG_ FR_FreespaceSectorKinestate275 : 47|2@0+ (1,0) [0|3] "-"  C3B
 SG_ FR_FreespaceSectorConRidence275 : 33|2@0+ (1,0) [0|3] "-"  C3B
 SG_ FR_FreespaceSectorDistance275 : 27|10@0+ (0.1,0) [0|100] "-"  C3B
 SG_ FR_FreespaceSectorKinestate274 : 29|2@0+ (1,0) [0|3] "-"  C3B
 SG_ FR_FreespaceSectorConRidence274 : 31|2@0+ (1,0) [0|3] "-"  C3B
 SG_ FR_FreespaceSectorDistance274 : 9|10@0+ (0.1,0) [0|100] "-"  C3B
 SG_ FR_FreespaceSectorKinestate273 : 11|2@0+ (1,0) [0|3] "-"  C3B
 SG_ FR_FreespaceSectorConRidence273 : 13|2@0+ (1,0) [0|3] "-"  C3B
 SG_ FR_FreespaceSectorDistance273 : 7|10@0+ (0.1,0) [0|100] "-"  C3B

BO_ 561 FR_231: 64 FR
 SG_ FR_CRCCheck_231 : 503|16@0+ (1,0) [0|65535] ""  C3B
 SG_ FR_RollingCounter_231 : 491|4@0+ (1,0) [0|15] ""  C3B
 SG_ FR_FreespaceSectorKinestate340 : 477|2@0+ (1,0) [0|3] "-"  C3B
 SG_ FR_FreespaceSectorConRidence340 : 479|2@0+ (1,0) [0|3] "-"  C3B
 SG_ FR_FreespaceSectorDistance340 : 457|10@0+ (0.1,0) [0|100] "-"  C3B
 SG_ FR_FreespaceSectorKinestate339 : 459|2@0+ (1,0) [0|3] "-"  C3B
 SG_ FR_FreespaceSectorConRidence339 : 461|2@0+ (1,0) [0|3] "-"  C3B
 SG_ FR_FreespaceSectorDistance339 : 455|10@0+ (0.1,0) [0|100] "-"  C3B
 SG_ FR_FreespaceSectorKinestate338 : 441|2@0+ (1,0) [0|3] "-"  C3B
 SG_ FR_FreespaceSectorConRidence338 : 443|2@0+ (1,0) [0|3] "-"  C3B
 SG_ FR_FreespaceSectorDistance338 : 437|10@0+ (0.1,0) [0|100] "-"  C3B
 SG_ FR_FreespaceSectorKinestate337 : 439|2@0+ (1,0) [0|3] "-"  C3B
 SG_ FR_FreespaceSectorConRidence337 : 425|2@0+ (1,0) [0|3] "-"  C3B
 SG_ FR_FreespaceSectorDistance337 : 419|10@0+ (0.1,0) [0|100] "-"  C3B
 SG_ FR_FreespaceSectorKinestate336 : 421|2@0+ (1,0) [0|3] "-"  C3B
 SG_ FR_FreespaceSectorConRidence336 : 423|2@0+ (1,0) [0|3] "-"  C3B
 SG_ FR_FreespaceSectorDistance336 : 401|10@0+ (0.1,0) [0|100] "-"  C3B
 SG_ FR_FreespaceSectorKinestate335 : 403|2@0+ (1,0) [0|3] "-"  C3B
 SG_ FR_FreespaceSectorConRidence335 : 405|2@0+ (1,0) [0|3] "-"  C3B
 SG_ FR_FreespaceSectorDistance335 : 399|10@0+ (0.1,0) [0|100] "-"  C3B
 SG_ FR_FreespaceSectorKinestate334 : 385|2@0+ (1,0) [0|3] "-"  C3B
 SG_ FR_FreespaceSectorConRidence334 : 387|2@0+ (1,0) [0|3] "-"  C3B
 SG_ FR_FreespaceSectorDistance334 : 381|10@0+ (0.1,0) [0|100] "-"  C3B
 SG_ FR_FreespaceSectorKinestate333 : 383|2@0+ (1,0) [0|3] "-"  C3B
 SG_ FR_FreespaceSectorConRidence333 : 369|2@0+ (1,0) [0|3] "-"  C3B
 SG_ FR_FreespaceSectorDistance333 : 363|10@0+ (0.1,0) [0|100] "-"  C3B
 SG_ FR_FreespaceSectorKinestate332 : 365|2@0+ (1,0) [0|3] "-"  C3B
 SG_ FR_FreespaceSectorConRidence332 : 367|2@0+ (1,0) [0|3] "-"  C3B
 SG_ FR_FreespaceSectorDistance332 : 345|10@0+ (0.1,0) [0|100] "-"  C3B
 SG_ FR_FreespaceSectorKinestate331 : 347|2@0+ (1,0) [0|3] "-"  C3B
 SG_ FR_FreespaceSectorConRidence331 : 349|2@0+ (1,0) [0|3] "-"  C3B
 SG_ FR_FreespaceSectorDistance331 : 343|10@0+ (0.1,0) [0|100] "-"  C3B
 SG_ FR_FreespaceSectorKinestate330 : 329|2@0+ (1,0) [0|3] "-"  C3B
 SG_ FR_FreespaceSectorConRidence330 : 331|2@0+ (1,0) [0|3] "-"  C3B
 SG_ FR_FreespaceSectorDistance330 : 325|10@0+ (0.1,0) [0|100] "-"  C3B
 SG_ FR_FreespaceSectorKinestate329 : 327|2@0+ (1,0) [0|3] "-"  C3B
 SG_ FR_FreespaceSectorConRidence329 : 313|2@0+ (1,0) [0|3] "-"  C3B
 SG_ FR_FreespaceSectorDistance329 : 307|10@0+ (0.1,0) [0|100] "-"  C3B
 SG_ FR_FreespaceSectorKinestate328 : 309|2@0+ (1,0) [0|3] "-"  C3B
 SG_ FR_FreespaceSectorConRidence328 : 311|2@0+ (1,0) [0|3] "-"  C3B
 SG_ FR_FreespaceSectorDistance328 : 289|10@0+ (0.1,0) [0|100] "-"  C3B
 SG_ FR_FreespaceSectorKinestate327 : 291|2@0+ (1,0) [0|3] "-"  C3B
 SG_ FR_FreespaceSectorConRidence327 : 293|2@0+ (1,0) [0|3] "-"  C3B
 SG_ FR_FreespaceSectorDistance327 : 287|10@0+ (0.1,0) [0|100] "-"  C3B
 SG_ FR_FreespaceSectorKinestate326 : 273|2@0+ (1,0) [0|3] "-"  C3B
 SG_ FR_FreespaceSectorConRidence326 : 275|2@0+ (1,0) [0|3] "-"  C3B
 SG_ FR_FreespaceSectorDistance326 : 269|10@0+ (0.1,0) [0|100] "-"  C3B
 SG_ FR_FreespaceSectorKinestate325 : 271|2@0+ (1,0) [0|3] "-"  C3B
 SG_ FR_FreespaceSectorConRidence325 : 257|2@0+ (1,0) [0|3] "-"  C3B
 SG_ FR_FreespaceSectorDistance325 : 251|10@0+ (0.1,0) [0|100] "-"  C3B
 SG_ FR_FreespaceSectorKinestate324 : 253|2@0+ (1,0) [0|3] "-"  C3B
 SG_ FR_FreespaceSectorConRidence324 : 255|2@0+ (1,0) [0|3] "-"  C3B
 SG_ FR_FreespaceSectorDistance324 : 233|10@0+ (0.1,0) [0|100] "-"  C3B
 SG_ FR_FreespaceSectorKinestate323 : 235|2@0+ (1,0) [0|3] "-"  C3B
 SG_ FR_FreespaceSectorConRidence323 : 237|2@0+ (1,0) [0|3] "-"  C3B
 SG_ FR_FreespaceSectorDistance323 : 231|10@0+ (0.1,0) [0|100] "-"  C3B
 SG_ FR_FreespaceSectorKinestate322 : 217|2@0+ (1,0) [0|3] "-"  C3B
 SG_ FR_FreespaceSectorConRidence322 : 219|2@0+ (1,0) [0|3] "-"  C3B
 SG_ FR_FreespaceSectorDistance322 : 213|10@0+ (0.1,0) [0|100] "-"  C3B
 SG_ FR_FreespaceSectorKinestate321 : 215|2@0+ (1,0) [0|3] "-"  C3B
 SG_ FR_FreespaceSectorConRidence321 : 201|2@0+ (1,0) [0|3] "-"  C3B
 SG_ FR_FreespaceSectorDistance321 : 195|10@0+ (0.1,0) [0|100] "-"  C3B
 SG_ FR_FreespaceSectorKinestate320 : 197|2@0+ (1,0) [0|3] "-"  C3B
 SG_ FR_FreespaceSectorConRidence320 : 199|2@0+ (1,0) [0|3] "-"  C3B
 SG_ FR_FreespaceSectorDistance320 : 177|10@0+ (0.1,0) [0|100] "-"  C3B
 SG_ FR_FreespaceSectorKinestate319 : 179|2@0+ (1,0) [0|3] "-"  C3B
 SG_ FR_FreespaceSectorConRidence319 : 181|2@0+ (1,0) [0|3] "-"  C3B
 SG_ FR_FreespaceSectorDistance319 : 175|10@0+ (0.1,0) [0|100] "-"  C3B
 SG_ FR_FreespaceSectorKinestate318 : 161|2@0+ (1,0) [0|3] "-"  C3B
 SG_ FR_FreespaceSectorConRidence318 : 163|2@0+ (1,0) [0|3] "-"  C3B
 SG_ FR_FreespaceSectorDistance318 : 157|10@0+ (0.1,0) [0|100] "-"  C3B
 SG_ FR_FreespaceSectorKinestate317 : 159|2@0+ (1,0) [0|3] "-"  C3B
 SG_ FR_FreespaceSectorConRidence317 : 145|2@0+ (1,0) [0|3] "-"  C3B
 SG_ FR_FreespaceSectorDistance317 : 139|10@0+ (0.1,0) [0|100] "-"  C3B
 SG_ FR_FreespaceSectorKinestate316 : 141|2@0+ (1,0) [0|3] "-"  C3B
 SG_ FR_FreespaceSectorConRidence316 : 143|2@0+ (1,0) [0|3] "-"  C3B
 SG_ FR_FreespaceSectorDistance316 : 121|10@0+ (0.1,0) [0|100] "-"  C3B
 SG_ FR_FreespaceSectorKinestate315 : 123|2@0+ (1,0) [0|3] "-"  C3B
 SG_ FR_FreespaceSectorConRidence315 : 125|2@0+ (1,0) [0|3] "-"  C3B
 SG_ FR_FreespaceSectorDistance315 : 119|10@0+ (0.1,0) [0|100] "-"  C3B
 SG_ FR_FreespaceSectorKinestate314 : 105|2@0+ (1,0) [0|3] "-"  C3B
 SG_ FR_FreespaceSectorConRidence314 : 107|2@0+ (1,0) [0|3] "-"  C3B
 SG_ FR_FreespaceSectorDistance314 : 101|10@0+ (0.1,0) [0|100] "-"  C3B
 SG_ FR_FreespaceSectorKinestate313 : 103|2@0+ (1,0) [0|3] "-"  C3B
 SG_ FR_FreespaceSectorConRidence313 : 89|2@0+ (1,0) [0|3] "-"  C3B
 SG_ FR_FreespaceSectorDistance313 : 83|10@0+ (0.1,0) [0|100] "-"  C3B
 SG_ FR_FreespaceSectorKinestate312 : 85|2@0+ (1,0) [0|3] "-"  C3B
 SG_ FR_FreespaceSectorConRidence312 : 87|2@0+ (1,0) [0|3] "-"  C3B
 SG_ FR_FreespaceSectorDistance312 : 65|10@0+ (0.1,0) [0|100] "-"  C3B
 SG_ FR_FreespaceSectorKinestate311 : 67|2@0+ (1,0) [0|3] "-"  C3B
 SG_ FR_FreespaceSectorConRidence311 : 69|2@0+ (1,0) [0|3] "-"  C3B
 SG_ FR_FreespaceSectorDistance311 : 63|10@0+ (0.1,0) [0|100] "-"  C3B
 SG_ FR_FreespaceSectorKinestate310 : 49|2@0+ (1,0) [0|3] "-"  C3B
 SG_ FR_FreespaceSectorConRidence310 : 51|2@0+ (1,0) [0|3] "-"  C3B
 SG_ FR_FreespaceSectorDistance310 : 45|10@0+ (0.1,0) [0|100] "-"  C3B
 SG_ FR_FreespaceSectorKinestate309 : 47|2@0+ (1,0) [0|3] "-"  C3B
 SG_ FR_FreespaceSectorConRidence309 : 33|2@0+ (1,0) [0|3] "-"  C3B
 SG_ FR_FreespaceSectorDistance309 : 27|10@0+ (0.1,0) [0|100] "-"  C3B
 SG_ FR_FreespaceSectorKinestate308 : 29|2@0+ (1,0) [0|3] "-"  C3B
 SG_ FR_FreespaceSectorConRidence308 : 31|2@0+ (1,0) [0|3] "-"  C3B
 SG_ FR_FreespaceSectorDistance308 : 9|10@0+ (0.1,0) [0|100] "-"  C3B
 SG_ FR_FreespaceSectorKinestate307 : 11|2@0+ (1,0) [0|3] "-"  C3B
 SG_ FR_FreespaceSectorConRidence307 : 13|2@0+ (1,0) [0|3] "-"  C3B
 SG_ FR_FreespaceSectorDistance307 : 7|10@0+ (0.1,0) [0|100] "-"  C3B

BO_ 562 FR_232: 64 FR
 SG_ FR_CRCCheck_232 : 503|16@0+ (1,0) [0|65535] ""  C3B
 SG_ FR_RollingCounter_232 : 491|4@0+ (1,0) [0|15] ""  C3B
 SG_ FR_FreespaceSectorKinestate360 : 273|2@0+ (1,0) [0|3] "-"  C3B
 SG_ FR_FreespaceSectorConRidence360 : 275|2@0+ (1,0) [0|3] "-"  C3B
 SG_ FR_FreespaceSectorDistance360 : 269|10@0+ (0.1,0) [0|100] "-"  C3B
 SG_ FR_FreespaceSectorKinestate359 : 271|2@0+ (1,0) [0|3] "-"  C3B
 SG_ FR_FreespaceSectorConRidence359 : 257|2@0+ (1,0) [0|3] "-"  C3B
 SG_ FR_FreespaceSectorDistance359 : 251|10@0+ (0.1,0) [0|100] "-"  C3B
 SG_ FR_FreespaceSectorKinestate358 : 253|2@0+ (1,0) [0|3] "-"  C3B
 SG_ FR_FreespaceSectorConRidence358 : 255|2@0+ (1,0) [0|3] "-"  C3B
 SG_ FR_FreespaceSectorDistance358 : 233|10@0+ (0.1,0) [0|100] "-"  C3B
 SG_ FR_FreespaceSectorKinestate357 : 235|2@0+ (1,0) [0|3] "-"  C3B
 SG_ FR_FreespaceSectorConRidence357 : 237|2@0+ (1,0) [0|3] "-"  C3B
 SG_ FR_FreespaceSectorDistance357 : 231|10@0+ (0.1,0) [0|100] "-"  C3B
 SG_ FR_FreespaceSectorKinestate356 : 217|2@0+ (1,0) [0|3] "-"  C3B
 SG_ FR_FreespaceSectorConRidence356 : 219|2@0+ (1,0) [0|3] "-"  C3B
 SG_ FR_FreespaceSectorDistance356 : 213|10@0+ (0.1,0) [0|100] "-"  C3B
 SG_ FR_FreespaceSectorKinestate355 : 215|2@0+ (1,0) [0|3] "-"  C3B
 SG_ FR_FreespaceSectorConRidence355 : 201|2@0+ (1,0) [0|3] "-"  C3B
 SG_ FR_FreespaceSectorDistance355 : 195|10@0+ (0.1,0) [0|100] "-"  C3B
 SG_ FR_FreespaceSectorKinestate354 : 197|2@0+ (1,0) [0|3] "-"  C3B
 SG_ FR_FreespaceSectorConRidence354 : 199|2@0+ (1,0) [0|3] "-"  C3B
 SG_ FR_FreespaceSectorDistance354 : 177|10@0+ (0.1,0) [0|100] "-"  C3B
 SG_ FR_FreespaceSectorKinestate353 : 179|2@0+ (1,0) [0|3] "-"  C3B
 SG_ FR_FreespaceSectorConRidence353 : 181|2@0+ (1,0) [0|3] "-"  C3B
 SG_ FR_FreespaceSectorDistance353 : 175|10@0+ (0.1,0) [0|100] "-"  C3B
 SG_ FR_FreespaceSectorKinestate352 : 161|2@0+ (1,0) [0|3] "-"  C3B
 SG_ FR_FreespaceSectorConRidence352 : 163|2@0+ (1,0) [0|3] "-"  C3B
 SG_ FR_FreespaceSectorDistance352 : 157|10@0+ (0.1,0) [0|100] "-"  C3B
 SG_ FR_FreespaceSectorKinestate351 : 159|2@0+ (1,0) [0|3] "-"  C3B
 SG_ FR_FreespaceSectorConRidence351 : 145|2@0+ (1,0) [0|3] "-"  C3B
 SG_ FR_FreespaceSectorDistance351 : 139|10@0+ (0.1,0) [0|100] "-"  C3B
 SG_ FR_FreespaceSectorKinestate350 : 141|2@0+ (1,0) [0|3] "-"  C3B
 SG_ FR_FreespaceSectorConRidence350 : 143|2@0+ (1,0) [0|3] "-"  C3B
 SG_ FR_FreespaceSectorDistance350 : 121|10@0+ (0.1,0) [0|100] "-"  C3B
 SG_ FR_FreespaceSectorKinestate349 : 123|2@0+ (1,0) [0|3] "-"  C3B
 SG_ FR_FreespaceSectorConRidence349 : 125|2@0+ (1,0) [0|3] "-"  C3B
 SG_ FR_FreespaceSectorDistance349 : 119|10@0+ (0.1,0) [0|100] "-"  C3B
 SG_ FR_FreespaceSectorKinestate348 : 105|2@0+ (1,0) [0|3] "-"  C3B
 SG_ FR_FreespaceSectorConRidence348 : 107|2@0+ (1,0) [0|3] "-"  C3B
 SG_ FR_FreespaceSectorDistance348 : 101|10@0+ (0.1,0) [0|100] "-"  C3B
 SG_ FR_FreespaceSectorKinestate347 : 103|2@0+ (1,0) [0|3] "-"  C3B
 SG_ FR_FreespaceSectorConRidence347 : 89|2@0+ (1,0) [0|3] "-"  C3B
 SG_ FR_FreespaceSectorDistance347 : 83|10@0+ (0.1,0) [0|100] "-"  C3B
 SG_ FR_FreespaceSectorKinestate346 : 85|2@0+ (1,0) [0|3] "-"  C3B
 SG_ FR_FreespaceSectorConRidence346 : 87|2@0+ (1,0) [0|3] "-"  C3B
 SG_ FR_FreespaceSectorDistance346 : 65|10@0+ (0.1,0) [0|100] "-"  C3B
 SG_ FR_FreespaceSectorKinestate345 : 67|2@0+ (1,0) [0|3] "-"  C3B
 SG_ FR_FreespaceSectorConRidence345 : 69|2@0+ (1,0) [0|3] "-"  C3B
 SG_ FR_FreespaceSectorDistance345 : 63|10@0+ (0.1,0) [0|100] "-"  C3B
 SG_ FR_FreespaceSectorKinestate344 : 49|2@0+ (1,0) [0|3] "-"  C3B
 SG_ FR_FreespaceSectorConRidence344 : 51|2@0+ (1,0) [0|3] "-"  C3B
 SG_ FR_FreespaceSectorDistance344 : 45|10@0+ (0.1,0) [0|100] "-"  C3B
 SG_ FR_FreespaceSectorKinestate343 : 47|2@0+ (1,0) [0|3] "-"  C3B
 SG_ FR_FreespaceSectorConRidence343 : 33|2@0+ (1,0) [0|3] "-"  C3B
 SG_ FR_FreespaceSectorDistance343 : 27|10@0+ (0.1,0) [0|100] "-"  C3B
 SG_ FR_FreespaceSectorKinestate342 : 29|2@0+ (1,0) [0|3] "-"  C3B
 SG_ FR_FreespaceSectorConRidence342 : 31|2@0+ (1,0) [0|3] "-"  C3B
 SG_ FR_FreespaceSectorDistance342 : 9|10@0+ (0.1,0) [0|100] "-"  C3B
 SG_ FR_FreespaceSectorKinestate341 : 11|2@0+ (1,0) [0|3] "-"  C3B
 SG_ FR_FreespaceSectorConRidence341 : 13|2@0+ (1,0) [0|3] "-"  C3B
 SG_ FR_FreespaceSectorDistance341 : 7|10@0+ (0.1,0) [0|100] "-"  C3B

BO_ 570 FR_23A: 64 FR
 SG_ FR_CRCCheck_23A : 503|16@0+ (1,0) [0|65535] ""  C3B
 SG_ FR_RollingCounter_23A : 491|4@0+ (1,0) [0|15] ""  C3B
 SG_ FR__FronRightGuardrail_Dy : 156|7@0+ (0.05,-5) [-5|1] "m"  C3B
 SG_ FR_FrontRightGuardrailConfidenc : 158|2@0+ (1,0) [0|3] "-"  C3B
 SG_ FR__FronRightGuardrail_End : 138|12@0+ (0.025,-20) [-20|82.375] "m"  C3B
 SG_ FR__FronRightGuardrail_Start : 134|12@0+ (0.025,-20) [-20|82.375] "m"  C3B
 SG_ FR_FrontRightGuardrailC3 : 114|12@0+ (4.8E-007,-0.001) [-0.001|0.000976086] "-"  C3B
 SG_ FR_FrontRightGuardrailC2 : 110|12@0+ (1.5E-005,-0.0312) [-0.0312|0.031234741] "-"  C3B
 SG_ FR_FrontRightGuardrailC1 : 90|12@0+ (0.00049,-1) [-1|0.999023438] "-"  C3B
 SG_ FR_FrontRightGuardrailC0 : 86|12@0+ (0.01563,-32) [-32|31.984375] "m"  C3B
 SG_ FR_FrontLeftGuardrailConfidence : 72|2@0+ (1,0) [0|3] "-"  C3B
 SG_ FR__FrontLeftGuardrail_Dy : 79|7@0+ (0.05,-1) [-1|5] "m"  C3B
 SG_ FR__FrontLeftGuardrail_End : 59|12@0+ (0.025,-20) [-20|82.375] "m"  C3B
 SG_ FR__FrontLeftGuardrail_Start : 55|12@0+ (0.025,-20) [-20|82.375] "m"  C3B
 SG_ FR_FrontLeftGuardrailC3 : 35|12@0+ (4.8E-007,-0.001) [-0.001|0.000976086] "-"  C3B
 SG_ FR_FrontLeftGuardrailC2 : 31|12@0+ (1.5E-005,-0.0312) [-0.0312|0.031234741] "-"  C3B
 SG_ FR_FrontLeftGuardrailC1 : 11|12@0+ (0.00049,-1) [-1|0.999023438] "-"  C3B
 SG_ FR_FrontLeftGuardrailC0 : 7|12@0+ (0.01563,-32) [-32|31.984375] "m"  C3B

BO_ 571 FR_23B: 64 FR
 SG_ FR_H_FR_Hametime : 31|16@0+ (0.01,0) [0|655.35] "ms"  C3B
 SG_ FR_H_ObjCount : 23|8@0+ (1,0) [0|32] ""  C3B
 SG_ FR_H_FR_HameCount : 71|32@0+ (1,0) [0|4294967295] ""  C3B
 SG_ FR_WorkSenceMode : 11|2@0+ (1,0) [0|3] ""  C3B
 SG_ FR_CRCCheck_23B : 503|16@0+ (1,0) [0|65535] ""  C3B
 SG_ FR_RollingCounter_23B : 491|4@0+ (1,0) [0|15] ""  C3B
 SG_ FR_SenceMode : 13|2@0+ (1,0) [0|3] ""  C3B
 SG_ FR_MisAlignment : 0|3@0+ (1,0) [0|7] ""  C3B
 SG_ FR_WorkMode : 2|2@0+ (1,0) [0|3] ""  C3B
 SG_ FR_RadarFailureStatus : 5|3@0+ (1,0) [0|7] ""  C3B
 SG_ FR_FRadarCalibrationStatus : 7|2@0+ (1,0) [0|3] ""  C3B

BO_ 572 FR_23C: 64 FR
 SG_ FR_Offset_invalid_reason : 109|2@0+ (1,0) [0|3] ""  C3B
 SG_ FR_MCUTiStamp : 71|16@0+ (1,0) [0|65535] "um"  C3B
 SG_ FR_SyncTiStamp : 135|64@0+ (0.0001,0) [0|1.84467440737095E+015] "s"  C3B
 SG_ FR_H_CRCCheck_23C : 503|16@0+ (1,0) [0|65535] ""  C3B
 SG_ FR_H_RollingCounter_23C : 491|4@0+ (1,0) [0|15] ""  C3B
 SG_ FR_Obj_TFLTiOut : 101|1@0+ (1,0) [0|1] "-"  C3B
 SG_ FR_Obj_TFLTiLeap : 102|1@0+ (1,0) [0|1] "-"  C3B
 SG_ FR_Obj_TFLTiBas : 103|1@0+ (1,0) [0|1] "-"  C3B
 SG_ FR_Obj_TFLTiStamp : 7|64@0+ (0.0001,0) [0|1.84467440737095E+015] "s"  C3B

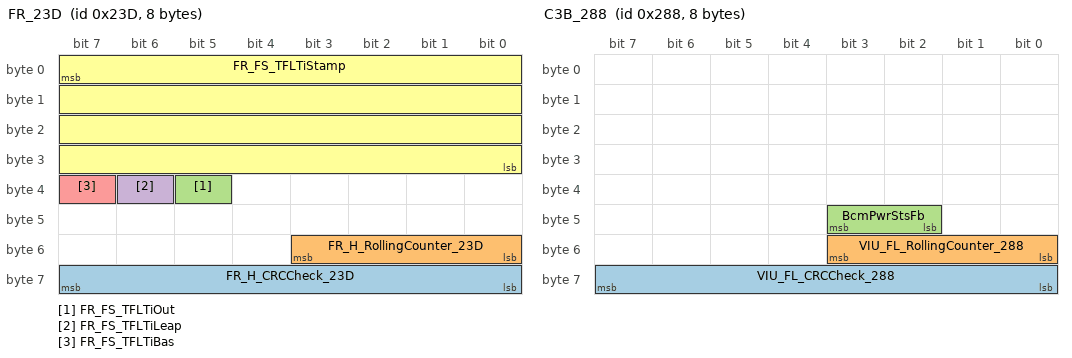
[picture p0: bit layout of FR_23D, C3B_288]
BO_ 573 FR_23D: 8 FR
 SG_ FR_H_CRCCheck_23D : 63|8@0+ (1,0) [0|255] ""  C3B
 SG_ FR_H_RollingCounter_23D : 51|4@0+ (1,0) [0|15] ""  C3B
 SG_ FR_FS_TFLTiOut : 37|1@0+ (1,0) [0|1] "-"  C3B
 SG_ FR_FS_TFLTiLeap : 38|1@0+ (1,0) [0|1] "-"  C3B
 SG_ FR_FS_TFLTiBas : 39|1@0+ (1,0) [0|1] "-"  C3B
 SG_ FR_FS_TFLTiStamp : 7|32@0+ (0.0001,0) [0|429496.7295] "s"  C3B

BO_ 574 FR_23E: 64 FR
 SG_ FR_TimeMonit_64 : 511|8@0+ (1,0) [0|255] "ms"  C3B
 SG_ FR_TimeMonit_63 : 503|8@0+ (1,0) [0|255] "ms"  C3B
 SG_ FR_TimeMonit_62 : 495|8@0+ (1,0) [0|255] "ms"  C3B
 SG_ FR_TimeMonit_61 : 487|8@0+ (1,0) [0|255] "ms"  C3B
 SG_ FR_TimeMonit_60 : 479|8@0+ (1,0) [0|255] "ms"  C3B
 SG_ FR_TimeMonit_59 : 471|8@0+ (1,0) [0|255] "ms"  C3B
 SG_ FR_TimeMonit_58 : 463|8@0+ (1,0) [0|255] "ms"  C3B
 SG_ FR_TimeMonit_57 : 455|8@0+ (1,0) [0|255] "ms"  C3B
 SG_ FR_TimeMonit_56 : 447|8@0+ (1,0) [0|255] "ms"  C3B
 SG_ FR_TimeMonit_55 : 439|8@0+ (1,0) [0|255] "ms"  C3B
 SG_ FR_TimeMonit_54 : 431|8@0+ (1,0) [0|255] "ms"  C3B
 SG_ FR_TimeMonit_53 : 423|8@0+ (1,0) [0|255] "ms"  C3B
 SG_ FR_TimeMonit_52 : 415|8@0+ (1,0) [0|255] "ms"  C3B
 SG_ FR_TimeMonit_51 : 407|8@0+ (1,0) [0|255] "ms"  C3B
 SG_ FR_TimeMonit_50 : 399|8@0+ (1,0) [0|255] "ms"  C3B
 SG_ FR_TimeMonit_49 : 391|8@0+ (1,0) [0|255] "ms"  C3B
 SG_ FR_TimeMonit_48 : 383|8@0+ (1,0) [0|255] "ms"  C3B
 SG_ FR_TimeMonit_47 : 375|8@0+ (1,0) [0|255] "ms"  C3B
 SG_ FR_TimeMonit_46 : 367|8@0+ (1,0) [0|255] "ms"  C3B
 SG_ FR_TimeMonit_45 : 359|8@0+ (1,0) [0|255] "ms"  C3B
 SG_ FR_TimeMonit_44 : 351|8@0+ (1,0) [0|255] "ms"  C3B
 SG_ FR_TimeMonit_43 : 343|8@0+ (1,0) [0|255] "ms"  C3B
 SG_ FR_TimeMonit_42 : 335|8@0+ (1,0) [0|255] "ms"  C3B
 SG_ FR_TimeMonit_41 : 327|8@0+ (1,0) [0|255] "ms"  C3B
 SG_ FR_TimeMonit_40 : 319|8@0+ (1,0) [0|255] "ms"  C3B
 SG_ FR_TimeMonit_39 : 311|8@0+ (1,0) [0|255] "ms"  C3B
 SG_ FR_TimeMonit_38 : 303|8@0+ (1,0) [0|255] "ms"  C3B
 SG_ FR_TimeMonit_37 : 295|8@0+ (1,0) [0|255] "ms"  C3B
 SG_ FR_TimeMonit_36 : 287|8@0+ (1,0) [0|255] "ms"  C3B
 SG_ FR_TimeMonit_35 : 279|8@0+ (1,0) [0|255] "ms"  C3B
 SG_ FR_TimeMonit_34 : 271|8@0+ (1,0) [0|255] "ms"  C3B
 SG_ FR_TimeMonit_33 : 263|8@0+ (1,0) [0|255] "ms"  C3B
 SG_ FR_TimeMonit_32 : 255|8@0+ (1,0) [0|255] "ms"  C3B
 SG_ FR_TimeMonit_31 : 247|8@0+ (1,0) [0|255] "ms"  C3B
 SG_ FR_TimeMonit_30 : 239|8@0+ (1,0) [0|255] "ms"  C3B
 SG_ FR_TimeMonit_29 : 231|8@0+ (1,0) [0|255] "ms"  C3B
 SG_ FR_TimeMonit_28 : 223|8@0+ (1,0) [0|255] "ms"  C3B
 SG_ FR_TimeMonit_27 : 215|8@0+ (1,0) [0|255] "ms"  C3B
 SG_ FR_TimeMonit_26 : 207|8@0+ (1,0) [0|255] "ms"  C3B
 SG_ FR_TimeMonit_25 : 199|8@0+ (1,0) [0|255] "ms"  C3B
 SG_ FR_TimeMonit_24 : 191|8@0+ (1,0) [0|255] "ms"  C3B
 SG_ FR_TimeMonit_23 : 183|8@0+ (1,0) [0|255] "ms"  C3B
 SG_ FR_TimeMonit_22 : 175|8@0+ (1,0) [0|255] "ms"  C3B
 SG_ FR_TimeMonit_21 : 167|8@0+ (1,0) [0|255] "ms"  C3B
 SG_ FR_TimeMonit_20 : 159|8@0+ (1,0) [0|255] "ms"  C3B
 SG_ FR_TimeMonit_19 : 151|8@0+ (1,0) [0|255] "ms"  C3B
 SG_ FR_TimeMonit_18 : 143|8@0+ (1,0) [0|255] "ms"  C3B
 SG_ FR_TimeMonit_17 : 135|8@0+ (1,0) [0|255] "ms"  C3B
 SG_ FR_TimeMonit_16 : 127|8@0+ (1,0) [0|255] "ms"  C3B
 SG_ FR_TimeMonit_15 : 119|8@0+ (1,0) [0|255] "ms"  C3B
 SG_ FR_TimeMonit_14 : 111|8@0+ (1,0) [0|255] "ms"  C3B
 SG_ FR_TimeMonit_13 : 103|8@0+ (1,0) [0|255] "ms"  C3B
 SG_ FR_TimeMonit_12 : 95|8@0+ (1,0) [0|255] "ms"  C3B
 SG_ FR_TimeMonit_11 : 87|8@0+ (1,0) [0|255] "ms"  C3B
 SG_ FR_TimeMonit_10 : 79|8@0+ (1,0) [0|255] "ms"  C3B
 SG_ FR_TimeMonit_9 : 71|8@0+ (1,0) [0|255] "ms"  C3B
 SG_ FR_TimeMonit_8 : 63|8@0+ (1,0) [0|255] "ms"  C3B
 SG_ FR_TimeMonit_7 : 55|8@0+ (1,0) [0|255] "ms"  C3B
 SG_ FR_TimeMonit_6 : 47|8@0+ (1,0) [0|255] "ms"  C3B
 SG_ FR_TimeMonit_5 : 39|8@0+ (1,0) [0|255] "ms"  C3B
 SG_ FR_TimeMonit_4 : 31|8@0+ (1,0) [0|255] "ms"  C3B
 SG_ FR_TimeMonit_3 : 23|8@0+ (1,0) [0|255] "ms"  C3B
 SG_ FR_TimeMonit_2 : 15|8@0+ (1,0) [0|255] "ms"  C3B
 SG_ FR_TimeMonit_1 : 7|8@0+ (1,0) [0|255] "ms"  C3B

BO_ 575 FR_23F: 64 FR
 SG_ FR_InterState : 303|8@0+ (1,0) [0|255] ""  C3B
 SG_ FR_Temperature4 : 295|8@0+ (1,0) [0|255] "℃"  C3B
 SG_ FR_Temperature3 : 287|8@0+ (1,0) [0|255] "℃"  C3B
 SG_ FR_Temperature2 : 279|8@0+ (1,0) [0|255] "℃"  C3B
 SG_ FR_Temperature1 : 271|8@0+ (1,0) [0|255] "℃"  C3B
 SG_ FR_targetNum3 : 261|6@0+ (1,0) [0|63] ""  C3B
 SG_ FR_targetNum2 : 253|6@0+ (1,0) [0|63] ""  C3B
 SG_ FR_targetNum1 : 233|10@0+ (1,0) [0|1023] ""  C3B
 SG_ FR_FR_voltage : 231|14@0+ (0.01,0) [0|163.83] "V"  C3B
 SG_ FR_PowerUpTime : 194|27@0+ (1,0) [0|134217727] ""  C3B
 SG_ FR_InterVersion : 327|64@0+ (1,0) [0|1.84467440737095E+019] ""  C3B
 SG_ FR_Block_Frame : 152|9@0+ (1,0) [0|511] ""  C3B
 SG_ FR_Block_State3 : 151|12@0+ (0.1,0) [0|409.5] ""  C3B
 SG_ FR_Block_State2 : 132|13@0+ (0.1,0) [0|819.1] ""  C3B
 SG_ FR_Block_State1 : 119|8@0+ (1,0) [0|255] ""  C3B
 SG_ FR_Azi_State : 23|2@0+ (1,0) [0|3] ""  C3B
 SG_ FR_Pitch_State : 21|2@0+ (1,0) [0|3] ""  C3B
 SG_ FR_Pitch_Angle_Comp2 : 99|12@0+ (0.01,-20.48) [-20.48|20.47] "deg"  C3B
 SG_ FR_Pitch_Angle_Comp1 : 95|12@0+ (0.01,-20.48) [-20.48|20.47] "deg"  C3B
 SG_ FR_Pitch_Angle_Accu : 47|8@0+ (1,0) [0|255] ""  C3B
 SG_ FR_Azi_Angle_Comp2 : 70|15@0+ (0.01,-163.84) [-163.84|-163.83] "deg"  C3B
 SG_ FR_Azi_Angle_Comp1 : 54|15@0+ (0.01,-163.84) [-163.84|-163.83] "deg"  C3B
 SG_ FR_Azi_Angle_Accu : 84|5@0+ (1,0) [0|31] ""  C3B
 SG_ FR_Calibration_State : 39|8@0+ (1,0) [0|255] ""  C3B
 SG_ FR_Pitch_Angle_Store : 19|12@0+ (0.01,-20.48) [-20.48|20.47] "deg"  C3B
 SG_ FR_Azi_Angle_Store : 6|15@0+ (0.01,-163.84) [-163.84|-163.83] "deg"  C3B

BO_ 648 C3B_288: 8 C3B
 SG_ VIU_FL_CRCCheck_288 : 63|8@0+ (1,0) [0|255] ""  FR
 SG_ VIU_FL_RollingCounter_288 : 51|4@0+ (1,0) [0|15] ""  FR
 SG_ BcmPwrStsFb : 43|2@0+ (1,0) [0|3] ""  FR

BO_ 722 C3B_2D2: 64 C3B
 SG_ CdcTotMilg : 399|24@0+ (0.1,0) [0|1677721.5] "Km"  FR

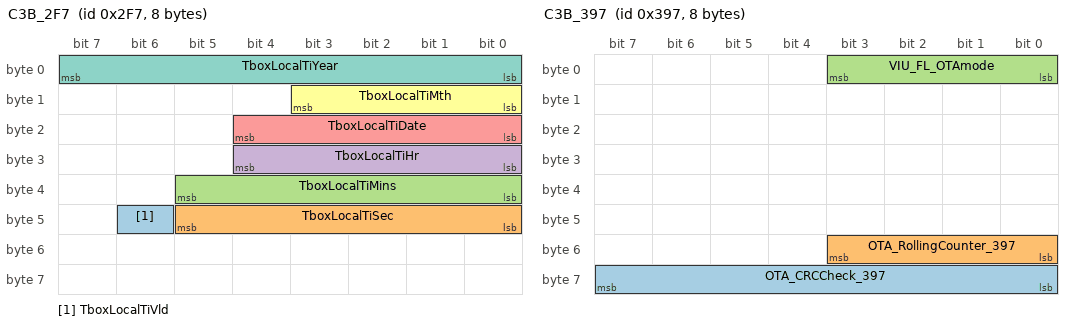
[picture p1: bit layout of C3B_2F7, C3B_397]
BO_ 759 C3B_2F7: 8 C3B
 SG_ TboxLocalTiVld : 46|1@0+ (1,0) [0|1] ""  FR
 SG_ TboxLocalTiSec : 45|6@0+ (1,0) [0|63] "second"  FR
 SG_ TboxLocalTiMins : 37|6@0+ (1,0) [0|63] "minute"  FR
 SG_ TboxLocalTiHr : 28|5@0+ (1,0) [0|31] "hour"  FR
 SG_ TboxLocalTiDate : 20|5@0+ (1,0) [0|31] "day"  FR
 SG_ TboxLocalTiMth : 11|4@0+ (1,0) [0|15] "month"  FR
 SG_ TboxLocalTiYear : 7|8@0+ (1,2000) [2000|2255] "year"  FR

BO_ 802 C3B_322: 64 C3B
 SG_ ECAStarLvl : 23|8@0+ (1,-128) [-128|127] "MM"  FR
 SG_ ECASActLvlRR : 31|16@0- (0.01,0) [-327.67|327.68] "MM"  FR
 SG_ ECASActLvlRL : 47|16@0- (0.01,0) [-327.67|327.68] "MM"  FR
 SG_ ECASActLvlFR : 87|16@0- (0.01,0) [-327.67|327.68] "MM"  FR
 SG_ ECASActLvlFL : 71|16@0- (0.01,0) [-327.67|327.68] "MM"  FR
 SG_ EcasModeFB : 7|5@0+ (1,0) [0|19] ""  FR
 SG_ EcasModeCHASts : 2|3@0+ (1,0) [0|7] ""  FR
 SG_ ECASAdjBySpd : 8|1@0+ (1,0) [0|1] ""  FR

BO_ 821 C3B_335: 64 C3B
 SG_ VCUGearShiftPositon : 315|4@0+ (1,0) [0|15] ""  FR
 SG_ VCU_CRCCheck_335 : 503|16@0+ (1,0) [0|65535] ""  FR
 SG_ VCU_RollingCounter_335 : 491|4@0+ (1,0) [0|15] ""  FR
 SG_ VCUShiftPostionValid : 311|1@0+ (1,0) [0|1] ""  FR

BO_ 919 C3B_397: 8 C3B
 SG_ OTA_CRCCheck_397 : 63|8@0+ (1,0) [0|255] ""  FR
 SG_ OTA_RollingCounter_397 : 51|4@0+ (1,0) [0|15] ""  FR
 SG_ VIU_FL_OTAmode : 3|4@0+ (1,0) [0|15] ""  FR

BO_ 1002 C3B_3EA: 32 C3B
 SG_ IR_Brightness : 23|8@0+ (400,0) [0|101200] "lux"  FR
 SG_ FW_Brightness : 31|10@0+ (6,0) [0|6126] "lux"  FR
 SG_ AMB_Brightness : 37|10@0+ (30,0) [0|30630] "lux"  FR
 SG_ BCM_RainfallLevel : 43|4@0+ (1,0) [0|15] ""  FR
 SG_ BCM_FrontWiperStatus : 7|4@0+ (1,0) [0|3] ""  FR

BO_ 1104 C3B_450: 8 C3B

BO_ 1107 FR_453: 8 FR

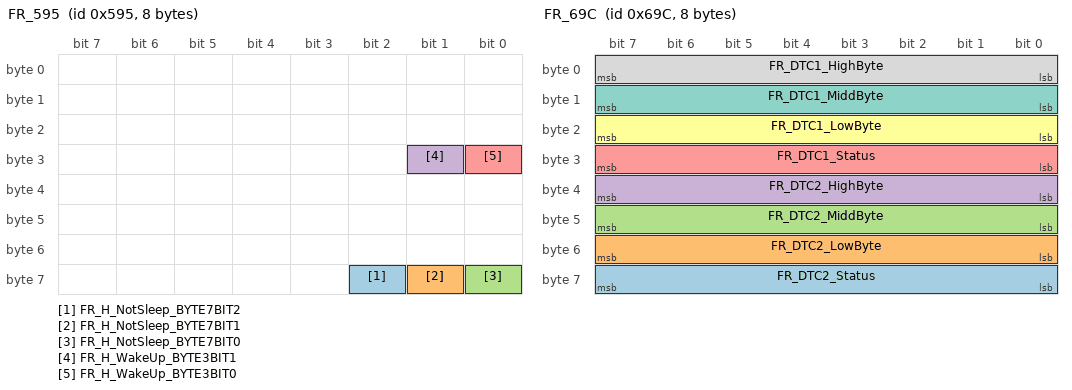
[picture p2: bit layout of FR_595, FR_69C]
BO_ 1429 FR_595: 8 FR
 SG_ FR_H_NotSleep_BYTE7BIT2 : 58|1@0+ (1,0) [0|1] ""  C3B
 SG_ FR_H_NotSleep_BYTE7BIT1 : 57|1@0+ (1,0) [0|1] ""  C3B
 SG_ FR_H_NotSleep_BYTE7BIT0 : 56|1@0+ (1,0) [0|1] ""  C3B
 SG_ FR_H_WakeUp_BYTE3BIT1 : 25|1@0+ (1,0) [0|1] ""  C3B
 SG_ FR_H_WakeUp_BYTE3BIT0 : 24|1@0+ (1,0) [0|1] ""  C3B

BO_ 1692 FR_69C: 8 FR
 SG_ FR_DTC2_Status : 63|8@0+ (1,0) [0|255] ""  C3B
 SG_ FR_DTC2_LowByte : 55|8@0+ (1,0) [0|255] ""  C3B
 SG_ FR_DTC2_MiddByte : 47|8@0+ (1,0) [0|255] ""  C3B
 SG_ FR_DTC2_HighByte : 39|8@0+ (1,0) [0|255] ""  C3B
 SG_ FR_DTC1_Status : 31|8@0+ (1,0) [0|255] ""  C3B
 SG_ FR_DTC1_LowByte : 23|8@0+ (1,0) [0|255] ""  C3B
 SG_ FR_DTC1_MiddByte : 15|8@0+ (1,0) [0|255] ""  C3B
 SG_ FR_DTC1_HighByte : 7|8@0+ (1,0) [0|255] ""  C3B

BO_ 1893 C3B_765: 64 C3B
 SG_ Diagnose_message_765 : 0|1@0+ (1,0) [0|1] ""  FR

BO_ 1901 FR_76D: 8 FR
 SG_ Diagnose_message_76D : 0|1@0+ (1,0) [0|1] ""  C3B

BO_ 2015 C3B_7DF: 64 C3B
 SG_ Diagnose_message_7DF : 0|1@0+ (1,0) [0|1] ""  FR

CM_ BO_ 557 " ";
CM_ SG_ 557 FR_CRCCheck_22D " ";
CM_ SG_ 557 FR_RollingCounter_22D " ";
CM_ SG_ 557 FR_FreespaceSectorKinestate204 " ";
CM_ SG_ 557 FR_FreespaceSectorConRidence204 " ";
CM_ SG_ 557 FR_FreespaceSectorDistance204 " ";
CM_ SG_ 557 FR_FreespaceSectorKinestate203 " ";
CM_ SG_ 557 FR_FreespaceSectorConRidence203 " ";
CM_ SG_ 557 FR_FreespaceSectorDistance203 " ";
CM_ SG_ 557 FR_FreespaceSectorKinestate202 " ";
CM_ SG_ 557 FR_FreespaceSectorConRidence202 " ";
CM_ SG_ 557 FR_FreespaceSectorDistance202 " ";
CM_ SG_ 557 FR_FreespaceSectorKinestate201 " ";
CM_ SG_ 557 FR_FreespaceSectorConRidence201 " ";
CM_ SG_ 557 FR_FreespaceSectorDistance201 " ";
CM_ SG_ 557 FR_FreespaceSectorKinestate200 " ";
CM_ SG_ 557 FR_FreespaceSectorConRidence200 " ";
CM_ SG_ 557 FR_FreespaceSectorDistance200 " ";
CM_ SG_ 557 FR_FreespaceSectorKinestate199 " ";
CM_ SG_ 557 FR_FreespaceSectorConRidence199 " ";
CM_ SG_ 557 FR_FreespaceSectorDistance199 " ";
CM_ SG_ 557 FR_FreespaceSectorKinestate198 " ";
CM_ SG_ 557 FR_FreespaceSectorConRidence198 " ";
CM_ SG_ 557 FR_FreespaceSectorDistance198 " ";
CM_ SG_ 557 FR_FreespaceSectorKinestate197 " ";
CM_ SG_ 557 FR_FreespaceSectorConRidence197 " ";
CM_ SG_ 557 FR_FreespaceSectorDistance197 " ";
CM_ SG_ 557 FR_FreespaceSectorKinestate196 " ";
CM_ SG_ 557 FR_FreespaceSectorConRidence196 " ";
CM_ SG_ 557 FR_FreespaceSectorDistance196 " ";
CM_ SG_ 557 FR_FreespaceSectorKinestate195 " ";
CM_ SG_ 557 FR_FreespaceSectorConRidence195 " ";
CM_ SG_ 557 FR_FreespaceSectorDistance195 " ";
CM_ SG_ 557 FR_FreespaceSectorKinestate194 " ";
CM_ SG_ 557 FR_FreespaceSectorConRidence194 " ";
CM_ SG_ 557 FR_FreespaceSectorDistance194 " ";
CM_ SG_ 557 FR_FreespaceSectorKinestate193 " ";
CM_ SG_ 557 FR_FreespaceSectorConRidence193 " ";
CM_ SG_ 557 FR_FreespaceSectorDistance193 " ";
CM_ SG_ 557 FR_FreespaceSectorKinestate192 " ";
CM_ SG_ 557 FR_FreespaceSectorConRidence192 " ";
CM_ SG_ 557 FR_FreespaceSectorDistance192 " ";
CM_ SG_ 557 FR_FreespaceSectorKinestate191 " ";
CM_ SG_ 557 FR_FreespaceSectorConRidence191 " ";
CM_ SG_ 557 FR_FreespaceSectorDistance191 " ";
CM_ SG_ 557 FR_FreespaceSectorKinestate190 " ";
CM_ SG_ 557 FR_FreespaceSectorConRidence190 " ";
CM_ SG_ 557 FR_FreespaceSectorDistance190 " ";
CM_ SG_ 557 FR_FreespaceSectorKinestate189 " ";
CM_ SG_ 557 FR_FreespaceSectorConRidence189 " ";
CM_ SG_ 557 FR_FreespaceSectorDistance189 " ";
CM_ SG_ 557 FR_FreespaceSectorKinestate188 " ";
CM_ SG_ 557 FR_FreespaceSectorConRidence188 " ";
CM_ SG_ 557 FR_FreespaceSectorDistance188 " ";
CM_ SG_ 557 FR_FreespaceSectorKinestate187 " ";
CM_ SG_ 557 FR_FreespaceSectorConRidence187 " ";
CM_ SG_ 557 FR_FreespaceSectorDistance187 " ";
CM_ SG_ 557 FR_FreespaceSectorKinestate186 " ";
CM_ SG_ 557 FR_FreespaceSectorConRidence186 " ";
CM_ SG_ 557 FR_FreespaceSectorDistance186 " ";
CM_ SG_ 557 FR_FreespaceSectorKinestate185 " ";
CM_ SG_ 557 FR_FreespaceSectorConRidence185 " ";
CM_ SG_ 557 FR_FreespaceSectorDistance185 " ";
CM_ SG_ 557 FR_FreespaceSectorKinestate184 " ";
CM_ SG_ 557 FR_FreespaceSectorConRidence184 " ";
CM_ SG_ 557 FR_FreespaceSectorDistance184 " ";
CM_ SG_ 557 FR_FreespaceSectorKinestate183 " ";
CM_ SG_ 557 FR_FreespaceSectorConRidence183 " ";
CM_ SG_ 557 FR_FreespaceSectorDistance183 " ";
CM_ SG_ 557 FR_FreespaceSectorKinestate182 " ";
CM_ SG_ 557 FR_FreespaceSectorConRidence182 " ";
CM_ SG_ 557 FR_FreespaceSectorDistance182 " ";
CM_ SG_ 557 FR_FreespaceSectorKinestate181 " ";
CM_ SG_ 557 FR_FreespaceSectorConRidence181 " ";
CM_ SG_ 557 FR_FreespaceSectorDistance181 " ";
CM_ SG_ 557 FR_FreespaceSectorKinestate180 " ";
CM_ SG_ 557 FR_FreespaceSectorConRidence180 " ";
CM_ SG_ 557 FR_FreespaceSectorDistance180 " ";
CM_ SG_ 557 FR_FreespaceSectorKinestate179 " ";
CM_ SG_ 557 FR_FreespaceSectorConRidence179 " ";
CM_ SG_ 557 FR_FreespaceSectorDistance179 " ";
CM_ SG_ 557 FR_FreespaceSectorKinestate178 " ";
CM_ SG_ 557 FR_FreespaceSectorConRidence178 " ";
CM_ SG_ 557 FR_FreespaceSectorDistance178 " ";
CM_ SG_ 557 FR_FreespaceSectorKinestate177 " ";
CM_ SG_ 557 FR_FreespaceSectorConRidence177 " ";
CM_ SG_ 557 FR_FreespaceSectorDistance177 " ";
CM_ SG_ 557 FR_FreespaceSectorKinestate176 " ";
CM_ SG_ 557 FR_FreespaceSectorConRidence176 " ";
CM_ SG_ 557 FR_FreespaceSectorDistance176 " ";
CM_ SG_ 557 FR_FreespaceSectorKinestate175 " ";
CM_ SG_ 557 FR_FreespaceSectorConRidence175 " ";
CM_ SG_ 557 FR_FreespaceSectorDistance175 " ";
CM_ SG_ 557 FR_FreespaceSectorKinestate174 " ";
CM_ SG_ 557 FR_FreespaceSectorConRidence174 " ";
CM_ SG_ 557 FR_FreespaceSectorDistance174 " ";
CM_ SG_ 557 FR_FreespaceSectorKinestate173 " ";
CM_ SG_ 557 FR_FreespaceSectorConRidence173 " ";
CM_ SG_ 557 FR_FreespaceSectorDistance173 " ";
CM_ SG_ 557 FR_FreespaceSectorKinestate172 " ";
CM_ SG_ 557 FR_FreespaceSectorConRidence172 " ";
CM_ SG_ 557 FR_FreespaceSectorDistance172 " ";
CM_ SG_ 557 FR_FreespaceSectorKinestate171 " ";
CM_ SG_ 557 FR_FreespaceSectorConRidence171 " ";
CM_ SG_ 557 FR_FreespaceSectorDistance171 " ";
CM_ BO_ 558 " ";
CM_ SG_ 558 FR_CRCCheck_22E " ";
CM_ SG_ 558 FR_RollingCounter_22E " ";
CM_ SG_ 558 FR_FreespaceSectorKinestate238 " ";
CM_ SG_ 558 FR_FreespaceSectorConRidence238 " ";
CM_ SG_ 558 FR_FreespaceSectorDistance238 " ";
CM_ SG_ 558 FR_FreespaceSectorKinestate237 " ";
CM_ SG_ 558 FR_FreespaceSectorConRidence237 " ";
CM_ SG_ 558 FR_FreespaceSectorDistance237 " ";
CM_ SG_ 558 FR_FreespaceSectorKinestate236 " ";
CM_ SG_ 558 FR_FreespaceSectorConRidence236 " ";
CM_ SG_ 558 FR_FreespaceSectorDistance236 " ";
CM_ SG_ 558 FR_FreespaceSectorKinestate235 " ";
CM_ SG_ 558 FR_FreespaceSectorConRidence235 " ";
CM_ SG_ 558 FR_FreespaceSectorDistance235 " ";
CM_ SG_ 558 FR_FreespaceSectorKinestate234 " ";
CM_ SG_ 558 FR_FreespaceSectorConRidence234 " ";
CM_ SG_ 558 FR_FreespaceSectorDistance234 " ";
CM_ SG_ 558 FR_FreespaceSectorKinestate233 " ";
CM_ SG_ 558 FR_FreespaceSectorConRidence233 " ";
CM_ SG_ 558 FR_FreespaceSectorDistance233 " ";
CM_ SG_ 558 FR_FreespaceSectorKinestate232 " ";
CM_ SG_ 558 FR_FreespaceSectorConRidence232 " ";
CM_ SG_ 558 FR_FreespaceSectorDistance232 " ";
CM_ SG_ 558 FR_FreespaceSectorKinestate231 " ";
CM_ SG_ 558 FR_FreespaceSectorConRidence231 " ";
CM_ SG_ 558 FR_FreespaceSectorDistance231 " ";
CM_ SG_ 558 FR_FreespaceSectorKinestate230 " ";
CM_ SG_ 558 FR_FreespaceSectorConRidence230 " ";
CM_ SG_ 558 FR_FreespaceSectorDistance230 " ";
CM_ SG_ 558 FR_FreespaceSectorKinestate229 " ";
CM_ SG_ 558 FR_FreespaceSectorConRidence229 " ";
CM_ SG_ 558 FR_FreespaceSectorDistance229 " ";
CM_ SG_ 558 FR_FreespaceSectorKinestate228 " ";
CM_ SG_ 558 FR_FreespaceSectorConRidence228 " ";
CM_ SG_ 558 FR_FreespaceSectorDistance228 " ";
CM_ SG_ 558 FR_FreespaceSectorKinestate227 " ";
CM_ SG_ 558 FR_FreespaceSectorConRidence227 " ";
CM_ SG_ 558 FR_FreespaceSectorDistance227 " ";
CM_ SG_ 558 FR_FreespaceSectorKinestate226 " ";
CM_ SG_ 558 FR_FreespaceSectorConRidence226 " ";
CM_ SG_ 558 FR_FreespaceSectorDistance226 " ";
CM_ SG_ 558 FR_FreespaceSectorKinestate225 " ";
CM_ SG_ 558 FR_FreespaceSectorConRidence225 " ";
CM_ SG_ 558 FR_FreespaceSectorDistance225 " ";
CM_ SG_ 558 FR_FreespaceSectorKinestate224 " ";
CM_ SG_ 558 FR_FreespaceSectorConRidence224 " ";
CM_ SG_ 558 FR_FreespaceSectorDistance224 " ";
CM_ SG_ 558 FR_FreespaceSectorKinestate223 " ";
CM_ SG_ 558 FR_FreespaceSectorConRidence223 " ";
CM_ SG_ 558 FR_FreespaceSectorDistance223 " ";
CM_ SG_ 558 FR_FreespaceSectorKinestate222 " ";
CM_ SG_ 558 FR_FreespaceSectorConRidence222 " ";
CM_ SG_ 558 FR_FreespaceSectorDistance222 " ";
CM_ SG_ 558 FR_FreespaceSectorKinestate221 " ";
CM_ SG_ 558 FR_FreespaceSectorConRidence221 " ";
CM_ SG_ 558 FR_FreespaceSectorDistance221 " ";
CM_ SG_ 558 FR_FreespaceSectorKinestate220 " ";
CM_ SG_ 558 FR_FreespaceSectorConRidence220 " ";
CM_ SG_ 558 FR_FreespaceSectorDistance220 " ";
CM_ SG_ 558 FR_FreespaceSectorKinestate219 " ";
CM_ SG_ 558 FR_FreespaceSectorConRidence219 " ";
CM_ SG_ 558 FR_FreespaceSectorDistance219 " ";
CM_ SG_ 558 FR_FreespaceSectorKinestate218 " ";
CM_ SG_ 558 FR_FreespaceSectorConRidence218 " ";
CM_ SG_ 558 FR_FreespaceSectorDistance218 " ";
CM_ SG_ 558 FR_FreespaceSectorKinestate217 " ";
CM_ SG_ 558 FR_FreespaceSectorConRidence217 " ";
CM_ SG_ 558 FR_FreespaceSectorDistance217 " ";
CM_ SG_ 558 FR_FreespaceSectorKinestate216 " ";
CM_ SG_ 558 FR_FreespaceSectorConRidence216 " ";
CM_ SG_ 558 FR_FreespaceSectorDistance216 " ";
CM_ SG_ 558 FR_FreespaceSectorKinestate215 " ";
CM_ SG_ 558 FR_FreespaceSectorConRidence215 " ";
CM_ SG_ 558 FR_FreespaceSectorDistance215 " ";
CM_ SG_ 558 FR_FreespaceSectorKinestate214 " ";
CM_ SG_ 558 FR_FreespaceSectorConRidence214 " ";
CM_ SG_ 558 FR_FreespaceSectorDistance214 " ";
CM_ SG_ 558 FR_FreespaceSectorKinestate213 " ";
CM_ SG_ 558 FR_FreespaceSectorConRidence213 " ";
CM_ SG_ 558 FR_FreespaceSectorDistance213 " ";
CM_ SG_ 558 FR_FreespaceSectorKinestate212 " ";
CM_ SG_ 558 FR_FreespaceSectorConRidence212 " ";
CM_ SG_ 558 FR_FreespaceSectorDistance212 " ";
CM_ SG_ 558 FR_FreespaceSectorKinestate211 " ";
CM_ SG_ 558 FR_FreespaceSectorConRidence211 " ";
CM_ SG_ 558 FR_FreespaceSectorDistance211 " ";
CM_ SG_ 558 FR_FreespaceSectorKinestate210 " ";
CM_ SG_ 558 FR_FreespaceSectorConRidence210 " ";
CM_ SG_ 558 FR_FreespaceSectorDistance210 " ";
CM_ SG_ 558 FR_FreespaceSectorKinestate209 " ";
CM_ SG_ 558 FR_FreespaceSectorConRidence209 " ";
CM_ SG_ 558 FR_FreespaceSectorDistance209 " ";
CM_ SG_ 558 FR_FreespaceSectorKinestate208 " ";
CM_ SG_ 558 FR_FreespaceSectorConRidence208 " ";
CM_ SG_ 558 FR_FreespaceSectorDistance208 " ";
CM_ SG_ 558 FR_FreespaceSectorKinestate207 " ";
CM_ SG_ 558 FR_FreespaceSectorConRidence207 " ";
CM_ SG_ 558 FR_FreespaceSectorDistance207 " ";
CM_ SG_ 558 FR_FreespaceSectorKinestate206 " ";
CM_ SG_ 558 FR_FreespaceSectorConRidence206 " ";
CM_ SG_ 558 FR_FreespaceSectorDistance206 " ";
CM_ SG_ 558 FR_FreespaceSectorKinestate205 " ";
CM_ SG_ 558 FR_FreespaceSectorConRidence205 " ";
CM_ SG_ 558 FR_FreespaceSectorDistance205 " ";
CM_ BO_ 559 " ";
CM_ SG_ 559 FR_CRCCheck_22F " ";
CM_ SG_ 559 FR_RollingCounter_22F " ";
CM_ SG_ 559 FR_FreespaceSectorKinestate272 " ";
CM_ SG_ 559 FR_FreespaceSectorConRidence272 " ";
CM_ SG_ 559 FR_FreespaceSectorDistance272 " ";
CM_ SG_ 559 FR_FreespaceSectorKinestate271 " ";
CM_ SG_ 559 FR_FreespaceSectorConRidence271 " ";
CM_ SG_ 559 FR_FreespaceSectorDistance271 " ";
CM_ SG_ 559 FR_FreespaceSectorKinestate270 " ";
CM_ SG_ 559 FR_FreespaceSectorConRidence270 " ";
CM_ SG_ 559 FR_FreespaceSectorDistance270 " ";
CM_ SG_ 559 FR_FreespaceSectorKinestate269 " ";
CM_ SG_ 559 FR_FreespaceSectorConRidence269 " ";
CM_ SG_ 559 FR_FreespaceSectorDistance269 " ";
CM_ SG_ 559 FR_FreespaceSectorKinestate268 " ";
CM_ SG_ 559 FR_FreespaceSectorConRidence268 " ";
CM_ SG_ 559 FR_FreespaceSectorDistance268 " ";
CM_ SG_ 559 FR_FreespaceSectorKinestate267 " ";
CM_ SG_ 559 FR_FreespaceSectorConRidence267 " ";
CM_ SG_ 559 FR_FreespaceSectorDistance267 " ";
CM_ SG_ 559 FR_FreespaceSectorKinestate266 " ";
CM_ SG_ 559 FR_FreespaceSectorConRidence266 " ";
CM_ SG_ 559 FR_FreespaceSectorDistance266 " ";
CM_ SG_ 559 FR_FreespaceSectorKinestate265 " ";
CM_ SG_ 559 FR_FreespaceSectorConRidence265 " ";
CM_ SG_ 559 FR_FreespaceSectorDistance265 " ";
CM_ SG_ 559 FR_FreespaceSectorKinestate264 " ";
CM_ SG_ 559 FR_FreespaceSectorConRidence264 " ";
CM_ SG_ 559 FR_FreespaceSectorDistance264 " ";
CM_ SG_ 559 FR_FreespaceSectorKinestate263 " ";
CM_ SG_ 559 FR_FreespaceSectorConRidence263 " ";
CM_ SG_ 559 FR_FreespaceSectorDistance263 " ";
CM_ SG_ 559 FR_FreespaceSectorKinestate262 " ";
CM_ SG_ 559 FR_FreespaceSectorConRidence262 " ";
CM_ SG_ 559 FR_FreespaceSectorDistance262 " ";
CM_ SG_ 559 FR_FreespaceSectorKinestate261 " ";
CM_ SG_ 559 FR_FreespaceSectorConRidence261 " ";
CM_ SG_ 559 FR_FreespaceSectorDistance261 " ";
CM_ SG_ 559 FR_FreespaceSectorKinestate260 " ";
CM_ SG_ 559 FR_FreespaceSectorConRidence260 " ";
CM_ SG_ 559 FR_FreespaceSectorDistance260 " ";
CM_ SG_ 559 FR_FreespaceSectorKinestate259 " ";
CM_ SG_ 559 FR_FreespaceSectorConRidence259 " ";
CM_ SG_ 559 FR_FreespaceSectorDistance259 " ";
CM_ SG_ 559 FR_FreespaceSectorKinestate258 " ";
CM_ SG_ 559 FR_FreespaceSectorConRidence258 " ";
CM_ SG_ 559 FR_FreespaceSectorDistance258 " ";
CM_ SG_ 559 FR_FreespaceSectorKinestate257 " ";
CM_ SG_ 559 FR_FreespaceSectorConRidence257 " ";
CM_ SG_ 559 FR_FreespaceSectorDistance257 " ";
CM_ SG_ 559 FR_FreespaceSectorKinestate256 " ";
CM_ SG_ 559 FR_FreespaceSectorConRidence256 " ";
CM_ SG_ 559 FR_FreespaceSectorDistance256 " ";
CM_ SG_ 559 FR_FreespaceSectorKinestate255 " ";
CM_ SG_ 559 FR_FreespaceSectorConRidence255 " ";
CM_ SG_ 559 FR_FreespaceSectorDistance255 " ";
CM_ SG_ 559 FR_FreespaceSectorKinestate254 " ";
CM_ SG_ 559 FR_FreespaceSectorConRidence254 " ";
CM_ SG_ 559 FR_FreespaceSectorDistance254 " ";
CM_ SG_ 559 FR_FreespaceSectorKinestate253 " ";
CM_ SG_ 559 FR_FreespaceSectorConRidence253 " ";
CM_ SG_ 559 FR_FreespaceSectorDistance253 " ";
CM_ SG_ 559 FR_FreespaceSectorKinestate252 " ";
CM_ SG_ 559 FR_FreespaceSectorConRidence252 " ";
CM_ SG_ 559 FR_FreespaceSectorDistance252 " ";
CM_ SG_ 559 FR_FreespaceSectorKinestate251 " ";
CM_ SG_ 559 FR_FreespaceSectorConRidence251 " ";
CM_ SG_ 559 FR_FreespaceSectorDistance251 " ";
CM_ SG_ 559 FR_FreespaceSectorKinestate250 " ";
CM_ SG_ 559 FR_FreespaceSectorConRidence250 " ";
CM_ SG_ 559 FR_FreespaceSectorDistance250 " ";
CM_ SG_ 559 FR_FreespaceSectorKinestate249 " ";
CM_ SG_ 559 FR_FreespaceSectorConRidence249 " ";
CM_ SG_ 559 FR_FreespaceSectorDistance249 " ";
CM_ SG_ 559 FR_FreespaceSectorKinestate248 " ";
CM_ SG_ 559 FR_FreespaceSectorConRidence248 " ";
CM_ SG_ 559 FR_FreespaceSectorDistance248 " ";
CM_ SG_ 559 FR_FreespaceSectorKinestate247 " ";
CM_ SG_ 559 FR_FreespaceSectorConRidence247 " ";
CM_ SG_ 559 FR_FreespaceSectorDistance247 " ";
CM_ SG_ 559 FR_FreespaceSectorKinestate246 " ";
CM_ SG_ 559 FR_FreespaceSectorConRidence246 " ";
CM_ SG_ 559 FR_FreespaceSectorDistance246 " ";
CM_ SG_ 559 FR_FreespaceSectorKinestate245 " ";
CM_ SG_ 559 FR_FreespaceSectorConRidence245 " ";
CM_ SG_ 559 FR_FreespaceSectorDistance245 " ";
CM_ SG_ 559 FR_FreespaceSectorKinestate244 " ";
CM_ SG_ 559 FR_FreespaceSectorConRidence244 " ";
CM_ SG_ 559 FR_FreespaceSectorDistance244 " ";
CM_ SG_ 559 FR_FreespaceSectorKinestate243 " ";
CM_ SG_ 559 FR_FreespaceSectorConRidence243 " ";
CM_ SG_ 559 FR_FreespaceSectorDistance243 " ";
CM_ SG_ 559 FR_FreespaceSectorKinestate242 " ";
CM_ SG_ 559 FR_FreespaceSectorConRidence242 " ";
CM_ SG_ 559 FR_FreespaceSectorDistance242 " ";
CM_ SG_ 559 FR_FreespaceSectorKinestate241 " ";
CM_ SG_ 559 FR_FreespaceSectorConRidence241 " ";
CM_ SG_ 559 FR_FreespaceSectorDistance241 " ";
CM_ SG_ 559 FR_FreespaceSectorKinestate240 " ";
CM_ SG_ 559 FR_FreespaceSectorConRidence240 " ";
CM_ SG_ 559 FR_FreespaceSectorDistance240 " ";
CM_ SG_ 559 FR_FreespaceSectorKinestate239 " ";
CM_ SG_ 559 FR_FreespaceSectorConRidence239 " ";
CM_ SG_ 559 FR_FreespaceSectorDistance239 " ";
CM_ BO_ 560 " ";
CM_ SG_ 560 FR_CRCCheck_230 " ";
CM_ SG_ 560 FR_RollingCounter_230 " ";
CM_ SG_ 560 FR_FreespaceSectorKinestate306 " ";
CM_ SG_ 560 FR_FreespaceSectorConRidence306 " ";
CM_ SG_ 560 FR_FreespaceSectorDistance306 " ";
CM_ SG_ 560 FR_FreespaceSectorKinestate305 " ";
CM_ SG_ 560 FR_FreespaceSectorConRidence305 " ";
CM_ SG_ 560 FR_FreespaceSectorDistance305 " ";
CM_ SG_ 560 FR_FreespaceSectorKinestate304 " ";
CM_ SG_ 560 FR_FreespaceSectorConRidence304 " ";
CM_ SG_ 560 FR_FreespaceSectorDistance304 " ";
CM_ SG_ 560 FR_FreespaceSectorKinestate303 " ";
CM_ SG_ 560 FR_FreespaceSectorConRidence303 " ";
CM_ SG_ 560 FR_FreespaceSectorDistance303 " ";
CM_ SG_ 560 FR_FreespaceSectorKinestate302 " ";
CM_ SG_ 560 FR_FreespaceSectorConRidence302 " ";
CM_ SG_ 560 FR_FreespaceSectorDistance302 " ";
CM_ SG_ 560 FR_FreespaceSectorKinestate301 " ";
CM_ SG_ 560 FR_FreespaceSectorConRidence301 " ";
CM_ SG_ 560 FR_FreespaceSectorDistance301 " ";
CM_ SG_ 560 FR_FreespaceSectorKinestate300 " ";
CM_ SG_ 560 FR_FreespaceSectorConRidence300 " ";
CM_ SG_ 560 FR_FreespaceSectorDistance300 " ";
CM_ SG_ 560 FR_FreespaceSectorKinestate299 " ";
CM_ SG_ 560 FR_FreespaceSectorConRidence299 " ";
CM_ SG_ 560 FR_FreespaceSectorDistance299 " ";
CM_ SG_ 560 FR_FreespaceSectorKinestate298 " ";
CM_ SG_ 560 FR_FreespaceSectorConRidence298 " ";
CM_ SG_ 560 FR_FreespaceSectorDistance298 " ";
CM_ SG_ 560 FR_FreespaceSectorKinestate297 " ";
CM_ SG_ 560 FR_FreespaceSectorConRidence297 " ";
CM_ SG_ 560 FR_FreespaceSectorDistance297 " ";
CM_ SG_ 560 FR_FreespaceSectorKinestate296 " ";
CM_ SG_ 560 FR_FreespaceSectorConRidence296 " ";
CM_ SG_ 560 FR_FreespaceSectorDistance296 " ";
CM_ SG_ 560 FR_FreespaceSectorKinestate295 " ";
CM_ SG_ 560 FR_FreespaceSectorConRidence295 " ";
CM_ SG_ 560 FR_FreespaceSectorDistance295 " ";
CM_ SG_ 560 FR_FreespaceSectorKinestate294 " ";
CM_ SG_ 560 FR_FreespaceSectorConRidence294 " ";
CM_ SG_ 560 FR_FreespaceSectorDistance294 " ";
CM_ SG_ 560 FR_FreespaceSectorKinestate293 " ";
CM_ SG_ 560 FR_FreespaceSectorConRidence293 " ";
CM_ SG_ 560 FR_FreespaceSectorDistance293 " ";
CM_ SG_ 560 FR_FreespaceSectorKinestate292 " ";
CM_ SG_ 560 FR_FreespaceSectorConRidence292 " ";
CM_ SG_ 560 FR_FreespaceSectorDistance292 " ";
CM_ SG_ 560 FR_FreespaceSectorKinestate291 " ";
CM_ SG_ 560 FR_FreespaceSectorConRidence291 " ";
CM_ SG_ 560 FR_FreespaceSectorDistance291 " ";
CM_ SG_ 560 FR_FreespaceSectorKinestate290 " ";
CM_ SG_ 560 FR_FreespaceSectorConRidence290 " ";
CM_ SG_ 560 FR_FreespaceSectorDistance290 " ";
CM_ SG_ 560 FR_FreespaceSectorKinestate289 " ";
CM_ SG_ 560 FR_FreespaceSectorConRidence289 " ";
CM_ SG_ 560 FR_FreespaceSectorDistance289 " ";
CM_ SG_ 560 FR_FreespaceSectorKinestate288 " ";
CM_ SG_ 560 FR_FreespaceSectorConRidence288 " ";
CM_ SG_ 560 FR_FreespaceSectorDistance288 " ";
CM_ SG_ 560 FR_FreespaceSectorKinestate287 " ";
CM_ SG_ 560 FR_FreespaceSectorConRidence287 " ";
CM_ SG_ 560 FR_FreespaceSectorDistance287 " ";
CM_ SG_ 560 FR_FreespaceSectorKinestate286 " ";
CM_ SG_ 560 FR_FreespaceSectorConRidence286 " ";
CM_ SG_ 560 FR_FreespaceSectorDistance286 " ";
CM_ SG_ 560 FR_FreespaceSectorKinestate285 " ";
CM_ SG_ 560 FR_FreespaceSectorConRidence285 " ";
CM_ SG_ 560 FR_FreespaceSectorDistance285 " ";
CM_ SG_ 560 FR_FreespaceSectorKinestate284 " ";
CM_ SG_ 560 FR_FreespaceSectorConRidence284 " ";
CM_ SG_ 560 FR_FreespaceSectorDistance284 " ";
CM_ SG_ 560 FR_FreespaceSectorKinestate283 " ";
CM_ SG_ 560 FR_FreespaceSectorConRidence283 " ";
CM_ SG_ 560 FR_FreespaceSectorDistance283 " ";
CM_ SG_ 560 FR_FreespaceSectorKinestate282 " ";
CM_ SG_ 560 FR_FreespaceSectorConRidence282 " ";
CM_ SG_ 560 FR_FreespaceSectorDistance282 " ";
CM_ SG_ 560 FR_FreespaceSectorKinestate281 " ";
CM_ SG_ 560 FR_FreespaceSectorConRidence281 " ";
CM_ SG_ 560 FR_FreespaceSectorDistance281 " ";
CM_ SG_ 560 FR_FreespaceSectorKinestate280 " ";
CM_ SG_ 560 FR_FreespaceSectorConRidence280 " ";
CM_ SG_ 560 FR_FreespaceSectorDistance280 " ";
CM_ SG_ 560 FR_FreespaceSectorKinestate279 " ";
CM_ SG_ 560 FR_FreespaceSectorConRidence279 " ";
CM_ SG_ 560 FR_FreespaceSectorDistance279 " ";
CM_ SG_ 560 FR_FreespaceSectorKinestate278 " ";
CM_ SG_ 560 FR_FreespaceSectorConRidence278 " ";
CM_ SG_ 560 FR_FreespaceSectorDistance278 " ";
CM_ SG_ 560 FR_FreespaceSectorKinestate277 " ";
CM_ SG_ 560 FR_FreespaceSectorConRidence277 " ";
CM_ SG_ 560 FR_FreespaceSectorDistance277 " ";
CM_ SG_ 560 FR_FreespaceSectorKinestate276 " ";
CM_ SG_ 560 FR_FreespaceSectorConRidence276 " ";
CM_ SG_ 560 FR_FreespaceSectorDistance276 " ";
CM_ SG_ 560 FR_FreespaceSectorKinestate275 " ";
CM_ SG_ 560 FR_FreespaceSectorConRidence275 " ";
CM_ SG_ 560 FR_FreespaceSectorDistance275 " ";
CM_ SG_ 560 FR_FreespaceSectorKinestate274 " ";
CM_ SG_ 560 FR_FreespaceSectorConRidence274 " ";
CM_ SG_ 560 FR_FreespaceSectorDistance274 " ";
CM_ SG_ 560 FR_FreespaceSectorKinestate273 " ";
CM_ SG_ 560 FR_FreespaceSectorConRidence273 " ";
CM_ SG_ 560 FR_FreespaceSectorDistance273 " ";
CM_ BO_ 561 " ";
CM_ SG_ 561 FR_CRCCheck_231 " ";
CM_ SG_ 561 FR_RollingCounter_231 " ";
CM_ SG_ 561 FR_FreespaceSectorKinestate340 " ";
CM_ SG_ 561 FR_FreespaceSectorConRidence340 " ";
CM_ SG_ 561 FR_FreespaceSectorDistance340 " ";
CM_ SG_ 561 FR_FreespaceSectorKinestate339 " ";
CM_ SG_ 561 FR_FreespaceSectorConRidence339 " ";
CM_ SG_ 561 FR_FreespaceSectorDistance339 " ";
CM_ SG_ 561 FR_FreespaceSectorKinestate338 " ";
CM_ SG_ 561 FR_FreespaceSectorConRidence338 " ";
CM_ SG_ 561 FR_FreespaceSectorDistance338 " ";
CM_ SG_ 561 FR_FreespaceSectorKinestate337 " ";
CM_ SG_ 561 FR_FreespaceSectorConRidence337 " ";
CM_ SG_ 561 FR_FreespaceSectorDistance337 " ";
CM_ SG_ 561 FR_FreespaceSectorKinestate336 " ";
CM_ SG_ 561 FR_FreespaceSectorConRidence336 " ";
CM_ SG_ 561 FR_FreespaceSectorDistance336 " ";
CM_ SG_ 561 FR_FreespaceSectorKinestate335 " ";
CM_ SG_ 561 FR_FreespaceSectorConRidence335 " ";
CM_ SG_ 561 FR_FreespaceSectorDistance335 " ";
CM_ SG_ 561 FR_FreespaceSectorKinestate334 " ";
CM_ SG_ 561 FR_FreespaceSectorConRidence334 " ";
CM_ SG_ 561 FR_FreespaceSectorDistance334 " ";
CM_ SG_ 561 FR_FreespaceSectorKinestate333 " ";
CM_ SG_ 561 FR_FreespaceSectorConRidence333 " ";
CM_ SG_ 561 FR_FreespaceSectorDistance333 " ";
CM_ SG_ 561 FR_FreespaceSectorKinestate332 " ";
CM_ SG_ 561 FR_FreespaceSectorConRidence332 " ";
CM_ SG_ 561 FR_FreespaceSectorDistance332 " ";
CM_ SG_ 561 FR_FreespaceSectorKinestate331 " ";
CM_ SG_ 561 FR_FreespaceSectorConRidence331 " ";
CM_ SG_ 561 FR_FreespaceSectorDistance331 " ";
CM_ SG_ 561 FR_FreespaceSectorKinestate330 " ";
CM_ SG_ 561 FR_FreespaceSectorConRidence330 " ";
CM_ SG_ 561 FR_FreespaceSectorDistance330 " ";
CM_ SG_ 561 FR_FreespaceSectorKinestate329 " ";
CM_ SG_ 561 FR_FreespaceSectorConRidence329 " ";
CM_ SG_ 561 FR_FreespaceSectorDistance329 " ";
CM_ SG_ 561 FR_FreespaceSectorKinestate328 " ";
CM_ SG_ 561 FR_FreespaceSectorConRidence328 " ";
CM_ SG_ 561 FR_FreespaceSectorDistance328 " ";
CM_ SG_ 561 FR_FreespaceSectorKinestate327 " ";
CM_ SG_ 561 FR_FreespaceSectorConRidence327 " ";
CM_ SG_ 561 FR_FreespaceSectorDistance327 " ";
CM_ SG_ 561 FR_FreespaceSectorKinestate326 " ";
CM_ SG_ 561 FR_FreespaceSectorConRidence326 " ";
CM_ SG_ 561 FR_FreespaceSectorDistance326 " ";
CM_ SG_ 561 FR_FreespaceSectorKinestate325 " ";
CM_ SG_ 561 FR_FreespaceSectorConRidence325 " ";
CM_ SG_ 561 FR_FreespaceSectorDistance325 " ";
CM_ SG_ 561 FR_FreespaceSectorKinestate324 " ";
CM_ SG_ 561 FR_FreespaceSectorConRidence324 " ";
CM_ SG_ 561 FR_FreespaceSectorDistance324 " ";
CM_ SG_ 561 FR_FreespaceSectorKinestate323 " ";
CM_ SG_ 561 FR_FreespaceSectorConRidence323 " ";
CM_ SG_ 561 FR_FreespaceSectorDistance323 " ";
CM_ SG_ 561 FR_FreespaceSectorKinestate322 " ";
CM_ SG_ 561 FR_FreespaceSectorConRidence322 " ";
CM_ SG_ 561 FR_FreespaceSectorDistance322 " ";
CM_ SG_ 561 FR_FreespaceSectorKinestate321 " ";
CM_ SG_ 561 FR_FreespaceSectorConRidence321 " ";
CM_ SG_ 561 FR_FreespaceSectorDistance321 " ";
CM_ SG_ 561 FR_FreespaceSectorKinestate320 " ";
CM_ SG_ 561 FR_FreespaceSectorConRidence320 " ";
CM_ SG_ 561 FR_FreespaceSectorDistance320 " ";
CM_ SG_ 561 FR_FreespaceSectorKinestate319 " ";
CM_ SG_ 561 FR_FreespaceSectorConRidence319 " ";
CM_ SG_ 561 FR_FreespaceSectorDistance319 " ";
CM_ SG_ 561 FR_FreespaceSectorKinestate318 " ";
CM_ SG_ 561 FR_FreespaceSectorConRidence318 " ";
CM_ SG_ 561 FR_FreespaceSectorDistance318 " ";
CM_ SG_ 561 FR_FreespaceSectorKinestate317 " ";
CM_ SG_ 561 FR_FreespaceSectorConRidence317 " ";
CM_ SG_ 561 FR_FreespaceSectorDistance317 " ";
CM_ SG_ 561 FR_FreespaceSectorKinestate316 " ";
CM_ SG_ 561 FR_FreespaceSectorConRidence316 " ";
CM_ SG_ 561 FR_FreespaceSectorDistance316 " ";
CM_ SG_ 561 FR_FreespaceSectorKinestate315 " ";
CM_ SG_ 561 FR_FreespaceSectorConRidence315 " ";
CM_ SG_ 561 FR_FreespaceSectorDistance315 " ";
CM_ SG_ 561 FR_FreespaceSectorKinestate314 " ";
CM_ SG_ 561 FR_FreespaceSectorConRidence314 " ";
CM_ SG_ 561 FR_FreespaceSectorDistance314 " ";
CM_ SG_ 561 FR_FreespaceSectorKinestate313 " ";
CM_ SG_ 561 FR_FreespaceSectorConRidence313 " ";
CM_ SG_ 561 FR_FreespaceSectorDistance313 " ";
CM_ SG_ 561 FR_FreespaceSectorKinestate312 " ";
CM_ SG_ 561 FR_FreespaceSectorConRidence312 " ";
CM_ SG_ 561 FR_FreespaceSectorDistance312 " ";
CM_ SG_ 561 FR_FreespaceSectorKinestate311 " ";
CM_ SG_ 561 FR_FreespaceSectorConRidence311 " ";
CM_ SG_ 561 FR_FreespaceSectorDistance311 " ";
CM_ SG_ 561 FR_FreespaceSectorKinestate310 " ";
CM_ SG_ 561 FR_FreespaceSectorConRidence310 " ";
CM_ SG_ 561 FR_FreespaceSectorDistance310 " ";
CM_ SG_ 561 FR_FreespaceSectorKinestate309 " ";
CM_ SG_ 561 FR_FreespaceSectorConRidence309 " ";
CM_ SG_ 561 FR_FreespaceSectorDistance309 " ";
CM_ SG_ 561 FR_FreespaceSectorKinestate308 " ";
CM_ SG_ 561 FR_FreespaceSectorConRidence308 " ";
CM_ SG_ 561 FR_FreespaceSectorDistance308 " ";
CM_ SG_ 561 FR_FreespaceSectorKinestate307 " ";
CM_ SG_ 561 FR_FreespaceSectorConRidence307 " ";
CM_ SG_ 561 FR_FreespaceSectorDistance307 " ";
CM_ BO_ 562 " ";
CM_ SG_ 562 FR_CRCCheck_232 " ";
CM_ SG_ 562 FR_RollingCounter_232 " ";
CM_ SG_ 562 FR_FreespaceSectorKinestate360 " ";
CM_ SG_ 562 FR_FreespaceSectorConRidence360 " ";
CM_ SG_ 562 FR_FreespaceSectorDistance360 " ";
CM_ SG_ 562 FR_FreespaceSectorKinestate359 " ";
CM_ SG_ 562 FR_FreespaceSectorConRidence359 " ";
CM_ SG_ 562 FR_FreespaceSectorDistance359 " ";
CM_ SG_ 562 FR_FreespaceSectorKinestate358 " ";
CM_ SG_ 562 FR_FreespaceSectorConRidence358 " ";
CM_ SG_ 562 FR_FreespaceSectorDistance358 " ";
CM_ SG_ 562 FR_FreespaceSectorKinestate357 " ";
CM_ SG_ 562 FR_FreespaceSectorConRidence357 " ";
CM_ SG_ 562 FR_FreespaceSectorDistance357 " ";
CM_ SG_ 562 FR_FreespaceSectorKinestate356 " ";
CM_ SG_ 562 FR_FreespaceSectorConRidence356 " ";
CM_ SG_ 562 FR_FreespaceSectorDistance356 " ";
CM_ SG_ 562 FR_FreespaceSectorKinestate355 " ";
CM_ SG_ 562 FR_FreespaceSectorConRidence355 " ";
CM_ SG_ 562 FR_FreespaceSectorDistance355 " ";
CM_ SG_ 562 FR_FreespaceSectorKinestate354 " ";
CM_ SG_ 562 FR_FreespaceSectorConRidence354 " ";
CM_ SG_ 562 FR_FreespaceSectorDistance354 " ";
CM_ SG_ 562 FR_FreespaceSectorKinestate353 " ";
CM_ SG_ 562 FR_FreespaceSectorConRidence353 " ";
CM_ SG_ 562 FR_FreespaceSectorDistance353 " ";
CM_ SG_ 562 FR_FreespaceSectorKinestate352 " ";
CM_ SG_ 562 FR_FreespaceSectorConRidence352 " ";
CM_ SG_ 562 FR_FreespaceSectorDistance352 " ";
CM_ SG_ 562 FR_FreespaceSectorKinestate351 " ";
CM_ SG_ 562 FR_FreespaceSectorConRidence351 " ";
CM_ SG_ 562 FR_FreespaceSectorDistance351 " ";
CM_ SG_ 562 FR_FreespaceSectorKinestate350 " ";
CM_ SG_ 562 FR_FreespaceSectorConRidence350 " ";
CM_ SG_ 562 FR_FreespaceSectorDistance350 " ";
CM_ SG_ 562 FR_FreespaceSectorKinestate349 " ";
CM_ SG_ 562 FR_FreespaceSectorConRidence349 " ";
CM_ SG_ 562 FR_FreespaceSectorDistance349 " ";
CM_ SG_ 562 FR_FreespaceSectorKinestate348 " ";
CM_ SG_ 562 FR_FreespaceSectorConRidence348 " ";
CM_ SG_ 562 FR_FreespaceSectorDistance348 " ";
CM_ SG_ 562 FR_FreespaceSectorKinestate347 " ";
CM_ SG_ 562 FR_FreespaceSectorConRidence347 " ";
CM_ SG_ 562 FR_FreespaceSectorDistance347 " ";
CM_ SG_ 562 FR_FreespaceSectorKinestate346 " ";
CM_ SG_ 562 FR_FreespaceSectorConRidence346 " ";
CM_ SG_ 562 FR_FreespaceSectorDistance346 " ";
CM_ SG_ 562 FR_FreespaceSectorKinestate345 " ";
CM_ SG_ 562 FR_FreespaceSectorConRidence345 " ";
CM_ SG_ 562 FR_FreespaceSectorDistance345 " ";
CM_ SG_ 562 FR_FreespaceSectorKinestate344 " ";
CM_ SG_ 562 FR_FreespaceSectorConRidence344 " ";
CM_ SG_ 562 FR_FreespaceSectorDistance344 " ";
CM_ SG_ 562 FR_FreespaceSectorKinestate343 " ";
CM_ SG_ 562 FR_FreespaceSectorConRidence343 " ";
CM_ SG_ 562 FR_FreespaceSectorDistance343 " ";
CM_ SG_ 562 FR_FreespaceSectorKinestate342 " ";
CM_ SG_ 562 FR_FreespaceSectorConRidence342 " ";
CM_ SG_ 562 FR_FreespaceSectorDistance342 " ";
CM_ SG_ 562 FR_FreespaceSectorKinestate341 " ";
CM_ SG_ 562 FR_FreespaceSectorConRidence341 " ";
CM_ SG_ 562 FR_FreespaceSectorDistance341 " ";
CM_ BO_ 570 " ";
CM_ SG_ 570 FR_CRCCheck_23A " ";
CM_ SG_ 570 FR_RollingCounter_23A " ";
CM_ SG_ 570 FR__FronRightGuardrail_Dy " ";
CM_ SG_ 570 FR_FrontRightGuardrailConfidenc " ";
CM_ SG_ 570 FR__FronRightGuardrail_End " ";
CM_ SG_ 570 FR__FronRightGuardrail_Start " ";
CM_ SG_ 570 FR_FrontRightGuardrailC3 " ";
CM_ SG_ 570 FR_FrontRightGuardrailC2 " ";
CM_ SG_ 570 FR_FrontRightGuardrailC1 " ";
CM_ SG_ 570 FR_FrontRightGuardrailC0 " ";
CM_ SG_ 570 FR_FrontLeftGuardrailConfidence " ";
CM_ SG_ 570 FR__FrontLeftGuardrail_Dy " ";
CM_ SG_ 570 FR__FrontLeftGuardrail_End " ";
CM_ SG_ 570 FR__FrontLeftGuardrail_Start " ";
CM_ SG_ 570 FR_FrontLeftGuardrailC3 " ";
CM_ SG_ 570 FR_FrontLeftGuardrailC2 " ";
CM_ SG_ 570 FR_FrontLeftGuardrailC1 " ";
CM_ SG_ 570 FR_FrontLeftGuardrailC0 " ";
CM_ BO_ 571 " ";
CM_ SG_ 571 FR_H_FR_Hametime " ";
CM_ SG_ 571 FR_H_ObjCount " ";
CM_ SG_ 571 FR_H_FR_HameCount " ";
CM_ SG_ 571 FR_WorkSenceMode " ";
CM_ SG_ 571 FR_CRCCheck_23B " ";
CM_ SG_ 571 FR_RollingCounter_23B " ";
CM_ SG_ 571 FR_SenceMode " ";
CM_ SG_ 571 FR_MisAlignment " ";
CM_ SG_ 571 FR_WorkMode " ";
CM_ SG_ 571 FR_RadarFailureStatus " ";
CM_ SG_ 571 FR_FRadarCalibrationStatus " ";
CM_ BO_ 572 " ";
CM_ SG_ 572 FR_Offset_invalid_reason " ";
CM_ SG_ 572 FR_MCUTiStamp " ";
CM_ SG_ 572 FR_SyncTiStamp " ";
CM_ SG_ 572 FR_H_CRCCheck_23C " ";
CM_ SG_ 572 FR_H_RollingCounter_23C " ";
CM_ SG_ 572 FR_Obj_TFLTiOut " ";
CM_ SG_ 572 FR_Obj_TFLTiLeap " ";
CM_ SG_ 572 FR_Obj_TFLTiBas " ";
CM_ SG_ 572 FR_Obj_TFLTiStamp " ";
CM_ BO_ 573 " ";
CM_ SG_ 573 FR_H_CRCCheck_23D " ";
CM_ SG_ 573 FR_H_RollingCounter_23D " ";
CM_ SG_ 573 FR_FS_TFLTiOut " ";
CM_ SG_ 573 FR_FS_TFLTiLeap " ";
CM_ SG_ 573 FR_FS_TFLTiBas " ";
CM_ SG_ 573 FR_FS_TFLTiStamp " ";
CM_ BO_ 574 " ";
CM_ SG_ 574 FR_TimeMonit_64 " ";
CM_ SG_ 574 FR_TimeMonit_63 " ";
CM_ SG_ 574 FR_TimeMonit_62 " ";
CM_ SG_ 574 FR_TimeMonit_61 " ";
CM_ SG_ 574 FR_TimeMonit_60 " ";
CM_ SG_ 574 FR_TimeMonit_59 " ";
CM_ SG_ 574 FR_TimeMonit_58 " ";
CM_ SG_ 574 FR_TimeMonit_57 " ";
CM_ SG_ 574 FR_TimeMonit_56 " ";
CM_ SG_ 574 FR_TimeMonit_55 " ";
CM_ SG_ 574 FR_TimeMonit_54 " ";
CM_ SG_ 574 FR_TimeMonit_53 " ";
CM_ SG_ 574 FR_TimeMonit_52 " ";
CM_ SG_ 574 FR_TimeMonit_51 " ";
CM_ SG_ 574 FR_TimeMonit_50 " ";
CM_ SG_ 574 FR_TimeMonit_49 " ";
CM_ SG_ 574 FR_TimeMonit_48 " ";
CM_ SG_ 574 FR_TimeMonit_47 " ";
CM_ SG_ 574 FR_TimeMonit_46 " ";
CM_ SG_ 574 FR_TimeMonit_45 " ";
CM_ SG_ 574 FR_TimeMonit_44 " ";
CM_ SG_ 574 FR_TimeMonit_43 " ";
CM_ SG_ 574 FR_TimeMonit_42 " ";
CM_ SG_ 574 FR_TimeMonit_41 " ";
CM_ SG_ 574 FR_TimeMonit_40 " ";
CM_ SG_ 574 FR_TimeMonit_39 " ";
CM_ SG_ 574 FR_TimeMonit_38 " ";
CM_ SG_ 574 FR_TimeMonit_37 " ";
CM_ SG_ 574 FR_TimeMonit_36 " ";
CM_ SG_ 574 FR_TimeMonit_35 " ";
CM_ SG_ 574 FR_TimeMonit_34 " ";
CM_ SG_ 574 FR_TimeMonit_33 " ";
CM_ SG_ 574 FR_TimeMonit_32 " ";
CM_ SG_ 574 FR_TimeMonit_31 " ";
CM_ SG_ 574 FR_TimeMonit_30 " ";
CM_ SG_ 574 FR_TimeMonit_29 " ";
CM_ SG_ 574 FR_TimeMonit_28 " ";
CM_ SG_ 574 FR_TimeMonit_27 " ";
CM_ SG_ 574 FR_TimeMonit_26 " ";
CM_ SG_ 574 FR_TimeMonit_25 " ";
CM_ SG_ 574 FR_TimeMonit_24 " ";
CM_ SG_ 574 FR_TimeMonit_23 " ";
CM_ SG_ 574 FR_TimeMonit_22 " ";
CM_ SG_ 574 FR_TimeMonit_21 " ";
CM_ SG_ 574 FR_TimeMonit_20 " ";
CM_ SG_ 574 FR_TimeMonit_19 " ";
CM_ SG_ 574 FR_TimeMonit_18 " ";
CM_ SG_ 574 FR_TimeMonit_17 " ";
CM_ SG_ 574 FR_TimeMonit_16 " ";
CM_ SG_ 574 FR_TimeMonit_15 " ";
CM_ SG_ 574 FR_TimeMonit_14 " ";
CM_ SG_ 574 FR_TimeMonit_13 " ";
CM_ SG_ 574 FR_TimeMonit_12 " ";
CM_ SG_ 574 FR_TimeMonit_11 " ";
CM_ SG_ 574 FR_TimeMonit_10 " ";
CM_ SG_ 574 FR_TimeMonit_9 " ";
CM_ SG_ 574 FR_TimeMonit_8 " ";
CM_ SG_ 574 FR_TimeMonit_7 " ";
CM_ SG_ 574 FR_TimeMonit_6 " ";
CM_ SG_ 574 FR_TimeMonit_5 " ";
CM_ SG_ 574 FR_TimeMonit_4 " ";
CM_ SG_ 574 FR_TimeMonit_3 " ";
CM_ SG_ 574 FR_TimeMonit_2 " ";
CM_ SG_ 574 FR_TimeMonit_1 " ";
CM_ BO_ 575 " ";
CM_ SG_ 575 FR_InterState " ";
CM_ SG_ 575 FR_Temperature4 " ";
CM_ SG_ 575 FR_Temperature3 " ";
CM_ SG_ 575 FR_Temperature2 " ";
CM_ SG_ 575 FR_Temperature1 " ";
CM_ SG_ 575 FR_targetNum3 " ";
CM_ SG_ 575 FR_targetNum2 " ";
CM_ SG_ 575 FR_targetNum1 " ";
CM_ SG_ 575 FR_FR_voltage " ";
CM_ SG_ 575 FR_PowerUpTime " ";
CM_ SG_ 575 FR_InterVersion " ";
CM_ SG_ 575 FR_Block_Frame " ";
CM_ SG_ 575 FR_Block_State3 " ";
CM_ SG_ 575 FR_Block_State2 " ";
CM_ SG_ 575 FR_Block_State1 " ";
CM_ SG_ 575 FR_Azi_State " ";
CM_ SG_ 575 FR_Pitch_State " ";
CM_ SG_ 575 FR_Pitch_Angle_Comp2 " ";
CM_ SG_ 575 FR_Pitch_Angle_Comp1 " ";
CM_ SG_ 575 FR_Pitch_Angle_Accu " ";
CM_ SG_ 575 FR_Azi_Angle_Comp2 " ";
CM_ SG_ 575 FR_Azi_Angle_Comp1 " ";
CM_ SG_ 575 FR_Azi_Angle_Accu " ";
CM_ SG_ 575 FR_Calibration_State " ";
CM_ SG_ 575 FR_Pitch_Angle_Store " ";
CM_ SG_ 575 FR_Azi_Angle_Store " ";
CM_ BO_ 648 " ";
CM_ SG_ 648 VIU_FL_CRCCheck_288 " ";
CM_ SG_ 648 VIU_FL_RollingCounter_288 " ";
CM_ SG_ 648 BcmPwrStsFb " ";
CM_ BO_ 722 " ";
CM_ SG_ 722 CdcTotMilg " ";
CM_ BO_ 759 " ";
CM_ SG_ 759 TboxLocalTiVld "mADC转发 ";
CM_ SG_ 759 TboxLocalTiSec "mADC转发 ";
CM_ SG_ 759 TboxLocalTiMins "mADC转发 ";
CM_ SG_ 759 TboxLocalTiHr "mADC转发 ";
CM_ SG_ 759 TboxLocalTiDate "mADC转发 ";
CM_ SG_ 759 TboxLocalTiMth "mADC转发 ";
CM_ SG_ 759 TboxLocalTiYear "mADC转发 ";
CM_ BO_ 802 " ";
CM_ SG_ 802 ECAStarLvl "目标高度为-50、-30、-25、-23、-16、、15、-9、-2、0、5、12、、19、20、26、33、40 ";
CM_ SG_ 802 ECASActLvlRR " ";
CM_ SG_ 802 ECASActLvlRL " ";
CM_ SG_ 802 ECASActLvlFR " ";
CM_ SG_ 802 ECASActLvlFL " ";
CM_ SG_ 802 EcasModeFB " ";
CM_ SG_ 802 EcasModeCHASts " ";
CM_ SG_ 802 ECASAdjBySpd " ";
CM_ BO_ 821 " ";
CM_ SG_ 821 VCUGearShiftPositon " ";
CM_ SG_ 821 VCU_CRCCheck_335 " ";
CM_ SG_ 821 VCU_RollingCounter_335 " ";
CM_ SG_ 821 VCUShiftPostionValid " ";
CM_ BO_ 919 " ";
CM_ SG_ 919 OTA_CRCCheck_397 " ";
CM_ SG_ 919 OTA_RollingCounter_397 " ";
CM_ SG_ 919 VIU_FL_OTAmode " ";
CM_ BO_ 1002 " ";
CM_ SG_ 1002 IR_Brightness " ";
CM_ SG_ 1002 FW_Brightness " ";
CM_ SG_ 1002 AMB_Brightness " ";
CM_ SG_ 1002 BCM_RainfallLevel "mADC转发 ";
CM_ SG_ 1002 BCM_FrontWiperStatus "mADC转发 ";
CM_ BO_ 1104 " ";
CM_ BO_ 1107 " ";
CM_ BO_ 1429 " ";
CM_ SG_ 1429 FR_H_NotSleep_BYTE7BIT2 " ";
CM_ SG_ 1429 FR_H_NotSleep_BYTE7BIT1 " ";
CM_ SG_ 1429 FR_H_NotSleep_BYTE7BIT0 " ";
CM_ SG_ 1429 FR_H_WakeUp_BYTE3BIT1 " ";
CM_ SG_ 1429 FR_H_WakeUp_BYTE3BIT0 " ";
CM_ BO_ 1692 " ";
CM_ SG_ 1692 FR_DTC2_Status "DTC上传 ";
CM_ SG_ 1692 FR_DTC2_LowByte "DTC上传 ";
CM_ SG_ 1692 FR_DTC2_MiddByte "DTC上传 ";
CM_ SG_ 1692 FR_DTC2_HighByte "DTC上传 ";
CM_ SG_ 1692 FR_DTC1_Status "DTC上传 ";
CM_ SG_ 1692 FR_DTC1_LowByte "DTC上传 ";
CM_ SG_ 1692 FR_DTC1_MiddByte "DTC上传 ";
CM_ SG_ 1692 FR_DTC1_HighByte "DTC上传 ";
CM_ BO_ 1893 "ADASA_CAN,C2,0x765,FR ";
CM_ SG_ 1893 Diagnose_message_765 " ";
CM_ BO_ 1901 "ADASA_CAN,FR,0x76D,FR ";
CM_ SG_ 1901 Diagnose_message_76D " ";
CM_ BO_ 2015 "ADASA_CAN,C2,0x7DF,功能寻址 ";
CM_ SG_ 2015 Diagnose_message_7DF " ";
BA_DEF_ SG_  "GenSigStartValue" INT 0 0;
BA_DEF_ SG_  "GenSigInvalidValue" STRING ;
BA_DEF_ SG_  "GenSigCycleTime" INT 0 0;
BA_DEF_ SG_  "GenSigSendType" ENUM  "Cyclic","OnWrite","OnWriteWithRepetition","OnChange","OnChangeWithRepetition","IfActive","IfActiveWithRepetition","NoSigSendType","NotUsed","NotUsed","NotUsed","NotUsed","NotUsed";
BA_DEF_ BO_  "GenMsgSendType" ENUM  "Cyclic","Event","Direct","NotUsed","NotUsed","Cyclic","NotUsed","IfActive","NoMsgSendType","NotUsed";
BA_DEF_ BO_  "GenMsgILSupport" ENUM  "No","Yes";
BA_DEF_ BO_  "GenMsgCycleTime" INT 0 65535;
BA_DEF_ BO_  "CANFD_BRS" ENUM  "0","1";
BA_DEF_ BO_  "VFrameFormat" ENUM  "StandardCAN","ExtendedCAN","reserved","reserved","reserved","reserved","reserved","reserved","reserved","reserved","reserved","reserved","reserved","reserved","StandardCAN_FD","ExtendedCAN_FD";
BA_DEF_DEF_  "GenSigStartValue" 0;
BA_DEF_DEF_  "GenSigInvalidValue" "/";
BA_DEF_DEF_  "GenSigCycleTime" 0;
BA_DEF_DEF_  "GenSigSendType" "Cyclic";
BA_DEF_DEF_  "GenMsgSendType" "NoMsgSendType";
BA_DEF_DEF_  "GenMsgILSupport" "Yes";
BA_DEF_DEF_  "GenMsgCycleTime" 0;
BA_DEF_DEF_  "CANFD_BRS" "1";
BA_DEF_DEF_  "VFrameFormat" "StandardCAN";
BA_ "GenMsgSendType" BO_ 557 0;
BA_ "GenMsgCycleTime" BO_ 557 60;
BA_ "VFrameFormat" BO_ 557 14;
BA_ "GenMsgSendType" BO_ 558 0;
BA_ "GenMsgCycleTime" BO_ 558 60;
BA_ "VFrameFormat" BO_ 558 14;
BA_ "GenMsgSendType" BO_ 559 0;
BA_ "GenMsgCycleTime" BO_ 559 60;
BA_ "VFrameFormat" BO_ 559 14;
BA_ "GenMsgSendType" BO_ 560 0;
BA_ "GenMsgCycleTime" BO_ 560 60;
BA_ "VFrameFormat" BO_ 560 14;
BA_ "GenMsgSendType" BO_ 561 0;
BA_ "GenMsgCycleTime" BO_ 561 60;
BA_ "VFrameFormat" BO_ 561 14;
BA_ "GenMsgSendType" BO_ 562 0;
BA_ "GenMsgCycleTime" BO_ 562 60;
BA_ "VFrameFormat" BO_ 562 14;
BA_ "GenMsgSendType" BO_ 570 0;
BA_ "GenMsgCycleTime" BO_ 570 60;
BA_ "VFrameFormat" BO_ 570 14;
BA_ "GenMsgSendType" BO_ 571 0;
BA_ "GenMsgCycleTime" BO_ 571 60;
BA_ "VFrameFormat" BO_ 571 14;
BA_ "GenMsgSendType" BO_ 572 0;
BA_ "GenMsgCycleTime" BO_ 572 60;
BA_ "VFrameFormat" BO_ 572 14;
BA_ "GenMsgSendType" BO_ 573 0;
BA_ "GenMsgCycleTime" BO_ 573 60;
BA_ "VFrameFormat" BO_ 573 14;
BA_ "GenMsgSendType" BO_ 574 0;
BA_ "GenMsgCycleTime" BO_ 574 60;
BA_ "VFrameFormat" BO_ 574 14;
BA_ "GenMsgSendType" BO_ 575 0;
BA_ "GenMsgCycleTime" BO_ 575 60;
BA_ "VFrameFormat" BO_ 575 14;
BA_ "GenMsgSendType" BO_ 648 0;
BA_ "GenMsgCycleTime" BO_ 648 40;
BA_ "VFrameFormat" BO_ 648 14;
BA_ "GenMsgSendType" BO_ 722 0;
BA_ "GenMsgCycleTime" BO_ 722 100;
BA_ "VFrameFormat" BO_ 722 14;
BA_ "GenMsgSendType" BO_ 759 0;
BA_ "GenMsgCycleTime" BO_ 759 1000;
BA_ "VFrameFormat" BO_ 759 14;
BA_ "GenMsgSendType" BO_ 802 0;
BA_ "GenMsgCycleTime" BO_ 802 100;
BA_ "VFrameFormat" BO_ 802 14;
BA_ "GenMsgSendType" BO_ 821 0;
BA_ "GenMsgCycleTime" BO_ 821 100;
BA_ "VFrameFormat" BO_ 821 14;
BA_ "GenMsgSendType" BO_ 919 0;
BA_ "GenMsgCycleTime" BO_ 919 500;
BA_ "VFrameFormat" BO_ 919 14;
BA_ "GenMsgSendType" BO_ 1002 0;
BA_ "GenMsgCycleTime" BO_ 1002 100;
BA_ "VFrameFormat" BO_ 1002 14;
BA_ "GenMsgSendType" BO_ 1104 1;
BA_ "GenMsgSendType" BO_ 1107 1;
BA_ "GenMsgSendType" BO_ 1429 0;
BA_ "GenMsgCycleTime" BO_ 1429 1000;
BA_ "VFrameFormat" BO_ 1429 14;
BA_ "GenMsgSendType" BO_ 1692 0;
BA_ "GenMsgCycleTime" BO_ 1692 500;
BA_ "VFrameFormat" BO_ 1692 14;
BA_ "GenMsgSendType" BO_ 1893 1;
BA_ "VFrameFormat" BO_ 1893 14;
BA_ "GenMsgSendType" BO_ 1901 1;
BA_ "VFrameFormat" BO_ 1901 14;
BA_ "GenMsgSendType" BO_ 2015 1;
BA_ "VFrameFormat" BO_ 2015 14;
BA_ "GenSigCycleTime" SG_ 557 FR_CRCCheck_22D 60;
BA_ "GenSigCycleTime" SG_ 557 FR_RollingCounter_22D 60;
BA_ "GenSigCycleTime" SG_ 557 FR_FreespaceSectorKinestate204 60;
BA_ "GenSigCycleTime" SG_ 557 FR_FreespaceSectorConRidence204 60;
BA_ "GenSigCycleTime" SG_ 557 FR_FreespaceSectorDistance204 60;
BA_ "GenSigCycleTime" SG_ 557 FR_FreespaceSectorKinestate203 60;
BA_ "GenSigCycleTime" SG_ 557 FR_FreespaceSectorConRidence203 60;
BA_ "GenSigCycleTime" SG_ 557 FR_FreespaceSectorDistance203 60;
BA_ "GenSigCycleTime" SG_ 557 FR_FreespaceSectorKinestate202 60;
BA_ "GenSigCycleTime" SG_ 557 FR_FreespaceSectorConRidence202 60;
BA_ "GenSigCycleTime" SG_ 557 FR_FreespaceSectorDistance202 60;
BA_ "GenSigCycleTime" SG_ 557 FR_FreespaceSectorKinestate201 60;
BA_ "GenSigCycleTime" SG_ 557 FR_FreespaceSectorConRidence201 60;
BA_ "GenSigCycleTime" SG_ 557 FR_FreespaceSectorDistance201 60;
BA_ "GenSigCycleTime" SG_ 557 FR_FreespaceSectorKinestate200 60;
BA_ "GenSigCycleTime" SG_ 557 FR_FreespaceSectorConRidence200 60;
BA_ "GenSigCycleTime" SG_ 557 FR_FreespaceSectorDistance200 60;
BA_ "GenSigCycleTime" SG_ 557 FR_FreespaceSectorKinestate199 60;
BA_ "GenSigCycleTime" SG_ 557 FR_FreespaceSectorConRidence199 60;
BA_ "GenSigCycleTime" SG_ 557 FR_FreespaceSectorDistance199 60;
BA_ "GenSigCycleTime" SG_ 557 FR_FreespaceSectorKinestate198 60;
BA_ "GenSigCycleTime" SG_ 557 FR_FreespaceSectorConRidence198 60;
BA_ "GenSigCycleTime" SG_ 557 FR_FreespaceSectorDistance198 60;
BA_ "GenSigCycleTime" SG_ 557 FR_FreespaceSectorKinestate197 60;
BA_ "GenSigCycleTime" SG_ 557 FR_FreespaceSectorConRidence197 60;
BA_ "GenSigCycleTime" SG_ 557 FR_FreespaceSectorDistance197 60;
BA_ "GenSigCycleTime" SG_ 557 FR_FreespaceSectorKinestate196 60;
BA_ "GenSigCycleTime" SG_ 557 FR_FreespaceSectorConRidence196 60;
BA_ "GenSigCycleTime" SG_ 557 FR_FreespaceSectorDistance196 60;
BA_ "GenSigCycleTime" SG_ 557 FR_FreespaceSectorKinestate195 60;
BA_ "GenSigCycleTime" SG_ 557 FR_FreespaceSectorConRidence195 60;
BA_ "GenSigCycleTime" SG_ 557 FR_FreespaceSectorDistance195 60;
BA_ "GenSigCycleTime" SG_ 557 FR_FreespaceSectorKinestate194 60;
BA_ "GenSigCycleTime" SG_ 557 FR_FreespaceSectorConRidence194 60;
BA_ "GenSigCycleTime" SG_ 557 FR_FreespaceSectorDistance194 60;
BA_ "GenSigCycleTime" SG_ 557 FR_FreespaceSectorKinestate193 60;
BA_ "GenSigCycleTime" SG_ 557 FR_FreespaceSectorConRidence193 60;
BA_ "GenSigCycleTime" SG_ 557 FR_FreespaceSectorDistance193 60;
BA_ "GenSigCycleTime" SG_ 557 FR_FreespaceSectorKinestate192 60;
BA_ "GenSigCycleTime" SG_ 557 FR_FreespaceSectorConRidence192 60;
BA_ "GenSigCycleTime" SG_ 557 FR_FreespaceSectorDistance192 60;
BA_ "GenSigCycleTime" SG_ 557 FR_FreespaceSectorKinestate191 60;
BA_ "GenSigCycleTime" SG_ 557 FR_FreespaceSectorConRidence191 60;
BA_ "GenSigCycleTime" SG_ 557 FR_FreespaceSectorDistance191 60;
BA_ "GenSigCycleTime" SG_ 557 FR_FreespaceSectorKinestate190 60;
BA_ "GenSigCycleTime" SG_ 557 FR_FreespaceSectorConRidence190 60;
BA_ "GenSigCycleTime" SG_ 557 FR_FreespaceSectorDistance190 60;
BA_ "GenSigCycleTime" SG_ 557 FR_FreespaceSectorKinestate189 60;
BA_ "GenSigCycleTime" SG_ 557 FR_FreespaceSectorConRidence189 60;
BA_ "GenSigCycleTime" SG_ 557 FR_FreespaceSectorDistance189 60;
BA_ "GenSigCycleTime" SG_ 557 FR_FreespaceSectorKinestate188 60;
BA_ "GenSigCycleTime" SG_ 557 FR_FreespaceSectorConRidence188 60;
BA_ "GenSigCycleTime" SG_ 557 FR_FreespaceSectorDistance188 60;
BA_ "GenSigCycleTime" SG_ 557 FR_FreespaceSectorKinestate187 60;
BA_ "GenSigCycleTime" SG_ 557 FR_FreespaceSectorConRidence187 60;
BA_ "GenSigCycleTime" SG_ 557 FR_FreespaceSectorDistance187 60;
BA_ "GenSigCycleTime" SG_ 557 FR_FreespaceSectorKinestate186 60;
BA_ "GenSigCycleTime" SG_ 557 FR_FreespaceSectorConRidence186 60;
BA_ "GenSigCycleTime" SG_ 557 FR_FreespaceSectorDistance186 60;
BA_ "GenSigCycleTime" SG_ 557 FR_FreespaceSectorKinestate185 60;
BA_ "GenSigCycleTime" SG_ 557 FR_FreespaceSectorConRidence185 60;
BA_ "GenSigCycleTime" SG_ 557 FR_FreespaceSectorDistance185 60;
BA_ "GenSigCycleTime" SG_ 557 FR_FreespaceSectorKinestate184 60;
BA_ "GenSigCycleTime" SG_ 557 FR_FreespaceSectorConRidence184 60;
BA_ "GenSigCycleTime" SG_ 557 FR_FreespaceSectorDistance184 60;
BA_ "GenSigCycleTime" SG_ 557 FR_FreespaceSectorKinestate183 60;
BA_ "GenSigCycleTime" SG_ 557 FR_FreespaceSectorConRidence183 60;
BA_ "GenSigCycleTime" SG_ 557 FR_FreespaceSectorDistance183 60;
BA_ "GenSigCycleTime" SG_ 557 FR_FreespaceSectorKinestate182 60;
BA_ "GenSigCycleTime" SG_ 557 FR_FreespaceSectorConRidence182 60;
BA_ "GenSigCycleTime" SG_ 557 FR_FreespaceSectorDistance182 60;
BA_ "GenSigCycleTime" SG_ 557 FR_FreespaceSectorKinestate181 60;
BA_ "GenSigCycleTime" SG_ 557 FR_FreespaceSectorConRidence181 60;
BA_ "GenSigCycleTime" SG_ 557 FR_FreespaceSectorDistance181 60;
BA_ "GenSigCycleTime" SG_ 557 FR_FreespaceSectorKinestate180 60;
BA_ "GenSigCycleTime" SG_ 557 FR_FreespaceSectorConRidence180 60;
BA_ "GenSigCycleTime" SG_ 557 FR_FreespaceSectorDistance180 60;
BA_ "GenSigCycleTime" SG_ 557 FR_FreespaceSectorKinestate179 60;
BA_ "GenSigCycleTime" SG_ 557 FR_FreespaceSectorConRidence179 60;
BA_ "GenSigCycleTime" SG_ 557 FR_FreespaceSectorDistance179 60;
BA_ "GenSigCycleTime" SG_ 557 FR_FreespaceSectorKinestate178 60;
BA_ "GenSigCycleTime" SG_ 557 FR_FreespaceSectorConRidence178 60;
BA_ "GenSigCycleTime" SG_ 557 FR_FreespaceSectorDistance178 60;
BA_ "GenSigCycleTime" SG_ 557 FR_FreespaceSectorKinestate177 60;
BA_ "GenSigCycleTime" SG_ 557 FR_FreespaceSectorConRidence177 60;
BA_ "GenSigCycleTime" SG_ 557 FR_FreespaceSectorDistance177 60;
BA_ "GenSigCycleTime" SG_ 557 FR_FreespaceSectorKinestate176 60;
BA_ "GenSigCycleTime" SG_ 557 FR_FreespaceSectorConRidence176 60;
BA_ "GenSigCycleTime" SG_ 557 FR_FreespaceSectorDistance176 60;
BA_ "GenSigCycleTime" SG_ 557 FR_FreespaceSectorKinestate175 60;
BA_ "GenSigCycleTime" SG_ 557 FR_FreespaceSectorConRidence175 60;
BA_ "GenSigCycleTime" SG_ 557 FR_FreespaceSectorDistance175 60;
BA_ "GenSigCycleTime" SG_ 557 FR_FreespaceSectorKinestate174 60;
BA_ "GenSigCycleTime" SG_ 557 FR_FreespaceSectorConRidence174 60;
BA_ "GenSigCycleTime" SG_ 557 FR_FreespaceSectorDistance174 60;
BA_ "GenSigCycleTime" SG_ 557 FR_FreespaceSectorKinestate173 60;
BA_ "GenSigCycleTime" SG_ 557 FR_FreespaceSectorConRidence173 60;
BA_ "GenSigCycleTime" SG_ 557 FR_FreespaceSectorDistance173 60;
BA_ "GenSigCycleTime" SG_ 557 FR_FreespaceSectorKinestate172 60;
BA_ "GenSigCycleTime" SG_ 557 FR_FreespaceSectorConRidence172 60;
BA_ "GenSigCycleTime" SG_ 557 FR_FreespaceSectorDistance172 60;
BA_ "GenSigCycleTime" SG_ 557 FR_FreespaceSectorKinestate171 60;
BA_ "GenSigCycleTime" SG_ 557 FR_FreespaceSectorConRidence171 60;
BA_ "GenSigCycleTime" SG_ 557 FR_FreespaceSectorDistance171 60;
BA_ "GenSigCycleTime" SG_ 558 FR_CRCCheck_22E 60;
BA_ "GenSigCycleTime" SG_ 558 FR_RollingCounter_22E 60;
BA_ "GenSigCycleTime" SG_ 558 FR_FreespaceSectorKinestate238 60;
BA_ "GenSigCycleTime" SG_ 558 FR_FreespaceSectorConRidence238 60;
BA_ "GenSigCycleTime" SG_ 558 FR_FreespaceSectorDistance238 60;
BA_ "GenSigCycleTime" SG_ 558 FR_FreespaceSectorKinestate237 60;
BA_ "GenSigCycleTime" SG_ 558 FR_FreespaceSectorConRidence237 60;
BA_ "GenSigCycleTime" SG_ 558 FR_FreespaceSectorDistance237 60;
BA_ "GenSigCycleTime" SG_ 558 FR_FreespaceSectorKinestate236 60;
BA_ "GenSigCycleTime" SG_ 558 FR_FreespaceSectorConRidence236 60;
BA_ "GenSigCycleTime" SG_ 558 FR_FreespaceSectorDistance236 60;
BA_ "GenSigCycleTime" SG_ 558 FR_FreespaceSectorKinestate235 60;
BA_ "GenSigCycleTime" SG_ 558 FR_FreespaceSectorConRidence235 60;
BA_ "GenSigCycleTime" SG_ 558 FR_FreespaceSectorDistance235 60;
BA_ "GenSigCycleTime" SG_ 558 FR_FreespaceSectorKinestate234 60;
BA_ "GenSigCycleTime" SG_ 558 FR_FreespaceSectorConRidence234 60;
BA_ "GenSigCycleTime" SG_ 558 FR_FreespaceSectorDistance234 60;
BA_ "GenSigCycleTime" SG_ 558 FR_FreespaceSectorKinestate233 60;
BA_ "GenSigCycleTime" SG_ 558 FR_FreespaceSectorConRidence233 60;
BA_ "GenSigCycleTime" SG_ 558 FR_FreespaceSectorDistance233 60;
BA_ "GenSigCycleTime" SG_ 558 FR_FreespaceSectorKinestate232 60;
BA_ "GenSigCycleTime" SG_ 558 FR_FreespaceSectorConRidence232 60;
BA_ "GenSigCycleTime" SG_ 558 FR_FreespaceSectorDistance232 60;
BA_ "GenSigCycleTime" SG_ 558 FR_FreespaceSectorKinestate231 60;
BA_ "GenSigCycleTime" SG_ 558 FR_FreespaceSectorConRidence231 60;
BA_ "GenSigCycleTime" SG_ 558 FR_FreespaceSectorDistance231 60;
BA_ "GenSigCycleTime" SG_ 558 FR_FreespaceSectorKinestate230 60;
BA_ "GenSigCycleTime" SG_ 558 FR_FreespaceSectorConRidence230 60;
BA_ "GenSigCycleTime" SG_ 558 FR_FreespaceSectorDistance230 60;
BA_ "GenSigCycleTime" SG_ 558 FR_FreespaceSectorKinestate229 60;
BA_ "GenSigCycleTime" SG_ 558 FR_FreespaceSectorConRidence229 60;
BA_ "GenSigCycleTime" SG_ 558 FR_FreespaceSectorDistance229 60;
BA_ "GenSigCycleTime" SG_ 558 FR_FreespaceSectorKinestate228 60;
BA_ "GenSigCycleTime" SG_ 558 FR_FreespaceSectorConRidence228 60;
BA_ "GenSigCycleTime" SG_ 558 FR_FreespaceSectorDistance228 60;
BA_ "GenSigCycleTime" SG_ 558 FR_FreespaceSectorKinestate227 60;
BA_ "GenSigCycleTime" SG_ 558 FR_FreespaceSectorConRidence227 60;
BA_ "GenSigCycleTime" SG_ 558 FR_FreespaceSectorDistance227 60;
BA_ "GenSigCycleTime" SG_ 558 FR_FreespaceSectorKinestate226 60;
BA_ "GenSigCycleTime" SG_ 558 FR_FreespaceSectorConRidence226 60;
BA_ "GenSigCycleTime" SG_ 558 FR_FreespaceSectorDistance226 60;
BA_ "GenSigCycleTime" SG_ 558 FR_FreespaceSectorKinestate225 60;
BA_ "GenSigCycleTime" SG_ 558 FR_FreespaceSectorConRidence225 60;
BA_ "GenSigCycleTime" SG_ 558 FR_FreespaceSectorDistance225 60;
BA_ "GenSigCycleTime" SG_ 558 FR_FreespaceSectorKinestate224 60;
BA_ "GenSigCycleTime" SG_ 558 FR_FreespaceSectorConRidence224 60;
BA_ "GenSigCycleTime" SG_ 558 FR_FreespaceSectorDistance224 60;
BA_ "GenSigCycleTime" SG_ 558 FR_FreespaceSectorKinestate223 60;
BA_ "GenSigCycleTime" SG_ 558 FR_FreespaceSectorConRidence223 60;
BA_ "GenSigCycleTime" SG_ 558 FR_FreespaceSectorDistance223 60;
BA_ "GenSigCycleTime" SG_ 558 FR_FreespaceSectorKinestate222 60;
BA_ "GenSigCycleTime" SG_ 558 FR_FreespaceSectorConRidence222 60;
BA_ "GenSigCycleTime" SG_ 558 FR_FreespaceSectorDistance222 60;
BA_ "GenSigCycleTime" SG_ 558 FR_FreespaceSectorKinestate221 60;
BA_ "GenSigCycleTime" SG_ 558 FR_FreespaceSectorConRidence221 60;
BA_ "GenSigCycleTime" SG_ 558 FR_FreespaceSectorDistance221 60;
BA_ "GenSigCycleTime" SG_ 558 FR_FreespaceSectorKinestate220 60;
BA_ "GenSigCycleTime" SG_ 558 FR_FreespaceSectorConRidence220 60;
BA_ "GenSigCycleTime" SG_ 558 FR_FreespaceSectorDistance220 60;
BA_ "GenSigCycleTime" SG_ 558 FR_FreespaceSectorKinestate219 60;
BA_ "GenSigCycleTime" SG_ 558 FR_FreespaceSectorConRidence219 60;
BA_ "GenSigCycleTime" SG_ 558 FR_FreespaceSectorDistance219 60;
BA_ "GenSigCycleTime" SG_ 558 FR_FreespaceSectorKinestate218 60;
BA_ "GenSigCycleTime" SG_ 558 FR_FreespaceSectorConRidence218 60;
BA_ "GenSigCycleTime" SG_ 558 FR_FreespaceSectorDistance218 60;
BA_ "GenSigCycleTime" SG_ 558 FR_FreespaceSectorKinestate217 60;
BA_ "GenSigCycleTime" SG_ 558 FR_FreespaceSectorConRidence217 60;
BA_ "GenSigCycleTime" SG_ 558 FR_FreespaceSectorDistance217 60;
BA_ "GenSigCycleTime" SG_ 558 FR_FreespaceSectorKinestate216 60;
BA_ "GenSigCycleTime" SG_ 558 FR_FreespaceSectorConRidence216 60;
BA_ "GenSigCycleTime" SG_ 558 FR_FreespaceSectorDistance216 60;
BA_ "GenSigCycleTime" SG_ 558 FR_FreespaceSectorKinestate215 60;
BA_ "GenSigCycleTime" SG_ 558 FR_FreespaceSectorConRidence215 60;
BA_ "GenSigCycleTime" SG_ 558 FR_FreespaceSectorDistance215 60;
BA_ "GenSigCycleTime" SG_ 558 FR_FreespaceSectorKinestate214 60;
BA_ "GenSigCycleTime" SG_ 558 FR_FreespaceSectorConRidence214 60;
BA_ "GenSigCycleTime" SG_ 558 FR_FreespaceSectorDistance214 60;
BA_ "GenSigCycleTime" SG_ 558 FR_FreespaceSectorKinestate213 60;
BA_ "GenSigCycleTime" SG_ 558 FR_FreespaceSectorConRidence213 60;
BA_ "GenSigCycleTime" SG_ 558 FR_FreespaceSectorDistance213 60;
BA_ "GenSigCycleTime" SG_ 558 FR_FreespaceSectorKinestate212 60;
BA_ "GenSigCycleTime" SG_ 558 FR_FreespaceSectorConRidence212 60;
BA_ "GenSigCycleTime" SG_ 558 FR_FreespaceSectorDistance212 60;
BA_ "GenSigCycleTime" SG_ 558 FR_FreespaceSectorKinestate211 60;
BA_ "GenSigCycleTime" SG_ 558 FR_FreespaceSectorConRidence211 60;
BA_ "GenSigCycleTime" SG_ 558 FR_FreespaceSectorDistance211 60;
BA_ "GenSigCycleTime" SG_ 558 FR_FreespaceSectorKinestate210 60;
BA_ "GenSigCycleTime" SG_ 558 FR_FreespaceSectorConRidence210 60;
BA_ "GenSigCycleTime" SG_ 558 FR_FreespaceSectorDistance210 60;
BA_ "GenSigCycleTime" SG_ 558 FR_FreespaceSectorKinestate209 60;
BA_ "GenSigCycleTime" SG_ 558 FR_FreespaceSectorConRidence209 60;
BA_ "GenSigCycleTime" SG_ 558 FR_FreespaceSectorDistance209 60;
BA_ "GenSigCycleTime" SG_ 558 FR_FreespaceSectorKinestate208 60;
BA_ "GenSigCycleTime" SG_ 558 FR_FreespaceSectorConRidence208 60;
BA_ "GenSigCycleTime" SG_ 558 FR_FreespaceSectorDistance208 60;
BA_ "GenSigCycleTime" SG_ 558 FR_FreespaceSectorKinestate207 60;
BA_ "GenSigCycleTime" SG_ 558 FR_FreespaceSectorConRidence207 60;
BA_ "GenSigCycleTime" SG_ 558 FR_FreespaceSectorDistance207 60;
BA_ "GenSigCycleTime" SG_ 558 FR_FreespaceSectorKinestate206 60;
BA_ "GenSigCycleTime" SG_ 558 FR_FreespaceSectorConRidence206 60;
BA_ "GenSigCycleTime" SG_ 558 FR_FreespaceSectorDistance206 60;
BA_ "GenSigCycleTime" SG_ 558 FR_FreespaceSectorKinestate205 60;
BA_ "GenSigCycleTime" SG_ 558 FR_FreespaceSectorConRidence205 60;
BA_ "GenSigCycleTime" SG_ 558 FR_FreespaceSectorDistance205 60;
BA_ "GenSigCycleTime" SG_ 559 FR_CRCCheck_22F 60;
BA_ "GenSigCycleTime" SG_ 559 FR_RollingCounter_22F 60;
BA_ "GenSigCycleTime" SG_ 559 FR_FreespaceSectorKinestate272 60;
BA_ "GenSigCycleTime" SG_ 559 FR_FreespaceSectorConRidence272 60;
BA_ "GenSigCycleTime" SG_ 559 FR_FreespaceSectorDistance272 60;
BA_ "GenSigCycleTime" SG_ 559 FR_FreespaceSectorKinestate271 60;
BA_ "GenSigCycleTime" SG_ 559 FR_FreespaceSectorConRidence271 60;
BA_ "GenSigCycleTime" SG_ 559 FR_FreespaceSectorDistance271 60;
BA_ "GenSigCycleTime" SG_ 559 FR_FreespaceSectorKinestate270 60;
BA_ "GenSigCycleTime" SG_ 559 FR_FreespaceSectorConRidence270 60;
BA_ "GenSigCycleTime" SG_ 559 FR_FreespaceSectorDistance270 60;
BA_ "GenSigCycleTime" SG_ 559 FR_FreespaceSectorKinestate269 60;
BA_ "GenSigCycleTime" SG_ 559 FR_FreespaceSectorConRidence269 60;
BA_ "GenSigCycleTime" SG_ 559 FR_FreespaceSectorDistance269 60;
BA_ "GenSigCycleTime" SG_ 559 FR_FreespaceSectorKinestate268 60;
BA_ "GenSigCycleTime" SG_ 559 FR_FreespaceSectorConRidence268 60;
BA_ "GenSigCycleTime" SG_ 559 FR_FreespaceSectorDistance268 60;
BA_ "GenSigCycleTime" SG_ 559 FR_FreespaceSectorKinestate267 60;
BA_ "GenSigCycleTime" SG_ 559 FR_FreespaceSectorConRidence267 60;
BA_ "GenSigCycleTime" SG_ 559 FR_FreespaceSectorDistance267 60;
BA_ "GenSigCycleTime" SG_ 559 FR_FreespaceSectorKinestate266 60;
BA_ "GenSigCycleTime" SG_ 559 FR_FreespaceSectorConRidence266 60;
BA_ "GenSigCycleTime" SG_ 559 FR_FreespaceSectorDistance266 60;
BA_ "GenSigCycleTime" SG_ 559 FR_FreespaceSectorKinestate265 60;
BA_ "GenSigCycleTime" SG_ 559 FR_FreespaceSectorConRidence265 60;
BA_ "GenSigCycleTime" SG_ 559 FR_FreespaceSectorDistance265 60;
BA_ "GenSigCycleTime" SG_ 559 FR_FreespaceSectorKinestate264 60;
BA_ "GenSigCycleTime" SG_ 559 FR_FreespaceSectorConRidence264 60;
BA_ "GenSigCycleTime" SG_ 559 FR_FreespaceSectorDistance264 60;
BA_ "GenSigCycleTime" SG_ 559 FR_FreespaceSectorKinestate263 60;
BA_ "GenSigCycleTime" SG_ 559 FR_FreespaceSectorConRidence263 60;
BA_ "GenSigCycleTime" SG_ 559 FR_FreespaceSectorDistance263 60;
BA_ "GenSigCycleTime" SG_ 559 FR_FreespaceSectorKinestate262 60;
BA_ "GenSigCycleTime" SG_ 559 FR_FreespaceSectorConRidence262 60;
BA_ "GenSigCycleTime" SG_ 559 FR_FreespaceSectorDistance262 60;
BA_ "GenSigCycleTime" SG_ 559 FR_FreespaceSectorKinestate261 60;
BA_ "GenSigCycleTime" SG_ 559 FR_FreespaceSectorConRidence261 60;
BA_ "GenSigCycleTime" SG_ 559 FR_FreespaceSectorDistance261 60;
BA_ "GenSigCycleTime" SG_ 559 FR_FreespaceSectorKinestate260 60;
BA_ "GenSigCycleTime" SG_ 559 FR_FreespaceSectorConRidence260 60;
BA_ "GenSigCycleTime" SG_ 559 FR_FreespaceSectorDistance260 60;
BA_ "GenSigCycleTime" SG_ 559 FR_FreespaceSectorKinestate259 60;
BA_ "GenSigCycleTime" SG_ 559 FR_FreespaceSectorConRidence259 60;
BA_ "GenSigCycleTime" SG_ 559 FR_FreespaceSectorDistance259 60;
BA_ "GenSigCycleTime" SG_ 559 FR_FreespaceSectorKinestate258 60;
BA_ "GenSigCycleTime" SG_ 559 FR_FreespaceSectorConRidence258 60;
BA_ "GenSigCycleTime" SG_ 559 FR_FreespaceSectorDistance258 60;
BA_ "GenSigCycleTime" SG_ 559 FR_FreespaceSectorKinestate257 60;
BA_ "GenSigCycleTime" SG_ 559 FR_FreespaceSectorConRidence257 60;
BA_ "GenSigCycleTime" SG_ 559 FR_FreespaceSectorDistance257 60;
BA_ "GenSigCycleTime" SG_ 559 FR_FreespaceSectorKinestate256 60;
BA_ "GenSigCycleTime" SG_ 559 FR_FreespaceSectorConRidence256 60;
BA_ "GenSigCycleTime" SG_ 559 FR_FreespaceSectorDistance256 60;
BA_ "GenSigCycleTime" SG_ 559 FR_FreespaceSectorKinestate255 60;
BA_ "GenSigCycleTime" SG_ 559 FR_FreespaceSectorConRidence255 60;
BA_ "GenSigCycleTime" SG_ 559 FR_FreespaceSectorDistance255 60;
BA_ "GenSigCycleTime" SG_ 559 FR_FreespaceSectorKinestate254 60;
BA_ "GenSigCycleTime" SG_ 559 FR_FreespaceSectorConRidence254 60;
BA_ "GenSigCycleTime" SG_ 559 FR_FreespaceSectorDistance254 60;
BA_ "GenSigCycleTime" SG_ 559 FR_FreespaceSectorKinestate253 60;
BA_ "GenSigCycleTime" SG_ 559 FR_FreespaceSectorConRidence253 60;
BA_ "GenSigCycleTime" SG_ 559 FR_FreespaceSectorDistance253 60;
BA_ "GenSigCycleTime" SG_ 559 FR_FreespaceSectorKinestate252 60;
BA_ "GenSigCycleTime" SG_ 559 FR_FreespaceSectorConRidence252 60;
BA_ "GenSigCycleTime" SG_ 559 FR_FreespaceSectorDistance252 60;
BA_ "GenSigCycleTime" SG_ 559 FR_FreespaceSectorKinestate251 60;
BA_ "GenSigCycleTime" SG_ 559 FR_FreespaceSectorConRidence251 60;
BA_ "GenSigCycleTime" SG_ 559 FR_FreespaceSectorDistance251 60;
BA_ "GenSigCycleTime" SG_ 559 FR_FreespaceSectorKinestate250 60;
BA_ "GenSigCycleTime" SG_ 559 FR_FreespaceSectorConRidence250 60;
BA_ "GenSigCycleTime" SG_ 559 FR_FreespaceSectorDistance250 60;
BA_ "GenSigCycleTime" SG_ 559 FR_FreespaceSectorKinestate249 60;
BA_ "GenSigCycleTime" SG_ 559 FR_FreespaceSectorConRidence249 60;
BA_ "GenSigCycleTime" SG_ 559 FR_FreespaceSectorDistance249 60;
BA_ "GenSigCycleTime" SG_ 559 FR_FreespaceSectorKinestate248 60;
BA_ "GenSigCycleTime" SG_ 559 FR_FreespaceSectorConRidence248 60;
BA_ "GenSigCycleTime" SG_ 559 FR_FreespaceSectorDistance248 60;
BA_ "GenSigCycleTime" SG_ 559 FR_FreespaceSectorKinestate247 60;
BA_ "GenSigCycleTime" SG_ 559 FR_FreespaceSectorConRidence247 60;
BA_ "GenSigCycleTime" SG_ 559 FR_FreespaceSectorDistance247 60;
BA_ "GenSigCycleTime" SG_ 559 FR_FreespaceSectorKinestate246 60;
BA_ "GenSigCycleTime" SG_ 559 FR_FreespaceSectorConRidence246 60;
BA_ "GenSigCycleTime" SG_ 559 FR_FreespaceSectorDistance246 60;
BA_ "GenSigCycleTime" SG_ 559 FR_FreespaceSectorKinestate245 60;
BA_ "GenSigCycleTime" SG_ 559 FR_FreespaceSectorConRidence245 60;
BA_ "GenSigCycleTime" SG_ 559 FR_FreespaceSectorDistance245 60;
BA_ "GenSigCycleTime" SG_ 559 FR_FreespaceSectorKinestate244 60;
BA_ "GenSigCycleTime" SG_ 559 FR_FreespaceSectorConRidence244 60;
BA_ "GenSigCycleTime" SG_ 559 FR_FreespaceSectorDistance244 60;
BA_ "GenSigCycleTime" SG_ 559 FR_FreespaceSectorKinestate243 60;
BA_ "GenSigCycleTime" SG_ 559 FR_FreespaceSectorConRidence243 60;
BA_ "GenSigCycleTime" SG_ 559 FR_FreespaceSectorDistance243 60;
BA_ "GenSigCycleTime" SG_ 559 FR_FreespaceSectorKinestate242 60;
BA_ "GenSigCycleTime" SG_ 559 FR_FreespaceSectorConRidence242 60;
BA_ "GenSigCycleTime" SG_ 559 FR_FreespaceSectorDistance242 60;
BA_ "GenSigCycleTime" SG_ 559 FR_FreespaceSectorKinestate241 60;
BA_ "GenSigCycleTime" SG_ 559 FR_FreespaceSectorConRidence241 60;
BA_ "GenSigCycleTime" SG_ 559 FR_FreespaceSectorDistance241 60;
BA_ "GenSigCycleTime" SG_ 559 FR_FreespaceSectorKinestate240 60;
BA_ "GenSigCycleTime" SG_ 559 FR_FreespaceSectorConRidence240 60;
BA_ "GenSigCycleTime" SG_ 559 FR_FreespaceSectorDistance240 60;
BA_ "GenSigCycleTime" SG_ 559 FR_FreespaceSectorKinestate239 60;
BA_ "GenSigCycleTime" SG_ 559 FR_FreespaceSectorConRidence239 60;
BA_ "GenSigCycleTime" SG_ 559 FR_FreespaceSectorDistance239 60;
BA_ "GenSigCycleTime" SG_ 560 FR_CRCCheck_230 60;
BA_ "GenSigCycleTime" SG_ 560 FR_RollingCounter_230 60;
BA_ "GenSigCycleTime" SG_ 560 FR_FreespaceSectorKinestate306 60;
BA_ "GenSigCycleTime" SG_ 560 FR_FreespaceSectorConRidence306 60;
BA_ "GenSigCycleTime" SG_ 560 FR_FreespaceSectorDistance306 60;
BA_ "GenSigCycleTime" SG_ 560 FR_FreespaceSectorKinestate305 60;
BA_ "GenSigCycleTime" SG_ 560 FR_FreespaceSectorConRidence305 60;
BA_ "GenSigCycleTime" SG_ 560 FR_FreespaceSectorDistance305 60;
BA_ "GenSigCycleTime" SG_ 560 FR_FreespaceSectorKinestate304 60;
BA_ "GenSigCycleTime" SG_ 560 FR_FreespaceSectorConRidence304 60;
BA_ "GenSigCycleTime" SG_ 560 FR_FreespaceSectorDistance304 60;
BA_ "GenSigCycleTime" SG_ 560 FR_FreespaceSectorKinestate303 60;
BA_ "GenSigCycleTime" SG_ 560 FR_FreespaceSectorConRidence303 60;
BA_ "GenSigCycleTime" SG_ 560 FR_FreespaceSectorDistance303 60;
BA_ "GenSigCycleTime" SG_ 560 FR_FreespaceSectorKinestate302 60;
BA_ "GenSigCycleTime" SG_ 560 FR_FreespaceSectorConRidence302 60;
BA_ "GenSigCycleTime" SG_ 560 FR_FreespaceSectorDistance302 60;
BA_ "GenSigCycleTime" SG_ 560 FR_FreespaceSectorKinestate301 60;
BA_ "GenSigCycleTime" SG_ 560 FR_FreespaceSectorConRidence301 60;
BA_ "GenSigCycleTime" SG_ 560 FR_FreespaceSectorDistance301 60;
BA_ "GenSigCycleTime" SG_ 560 FR_FreespaceSectorKinestate300 60;
BA_ "GenSigCycleTime" SG_ 560 FR_FreespaceSectorConRidence300 60;
BA_ "GenSigCycleTime" SG_ 560 FR_FreespaceSectorDistance300 60;
BA_ "GenSigCycleTime" SG_ 560 FR_FreespaceSectorKinestate299 60;
BA_ "GenSigCycleTime" SG_ 560 FR_FreespaceSectorConRidence299 60;
BA_ "GenSigCycleTime" SG_ 560 FR_FreespaceSectorDistance299 60;
BA_ "GenSigCycleTime" SG_ 560 FR_FreespaceSectorKinestate298 60;
BA_ "GenSigCycleTime" SG_ 560 FR_FreespaceSectorConRidence298 60;
BA_ "GenSigCycleTime" SG_ 560 FR_FreespaceSectorDistance298 60;
BA_ "GenSigCycleTime" SG_ 560 FR_FreespaceSectorKinestate297 60;
BA_ "GenSigCycleTime" SG_ 560 FR_FreespaceSectorConRidence297 60;
BA_ "GenSigCycleTime" SG_ 560 FR_FreespaceSectorDistance297 60;
BA_ "GenSigCycleTime" SG_ 560 FR_FreespaceSectorKinestate296 60;
BA_ "GenSigCycleTime" SG_ 560 FR_FreespaceSectorConRidence296 60;
BA_ "GenSigCycleTime" SG_ 560 FR_FreespaceSectorDistance296 60;
BA_ "GenSigCycleTime" SG_ 560 FR_FreespaceSectorKinestate295 60;
BA_ "GenSigCycleTime" SG_ 560 FR_FreespaceSectorConRidence295 60;
BA_ "GenSigCycleTime" SG_ 560 FR_FreespaceSectorDistance295 60;
BA_ "GenSigCycleTime" SG_ 560 FR_FreespaceSectorKinestate294 60;
BA_ "GenSigCycleTime" SG_ 560 FR_FreespaceSectorConRidence294 60;
BA_ "GenSigCycleTime" SG_ 560 FR_FreespaceSectorDistance294 60;
BA_ "GenSigCycleTime" SG_ 560 FR_FreespaceSectorKinestate293 60;
BA_ "GenSigCycleTime" SG_ 560 FR_FreespaceSectorConRidence293 60;
BA_ "GenSigCycleTime" SG_ 560 FR_FreespaceSectorDistance293 60;
BA_ "GenSigCycleTime" SG_ 560 FR_FreespaceSectorKinestate292 60;
BA_ "GenSigCycleTime" SG_ 560 FR_FreespaceSectorConRidence292 60;
BA_ "GenSigCycleTime" SG_ 560 FR_FreespaceSectorDistance292 60;
BA_ "GenSigCycleTime" SG_ 560 FR_FreespaceSectorKinestate291 60;
BA_ "GenSigCycleTime" SG_ 560 FR_FreespaceSectorConRidence291 60;
BA_ "GenSigCycleTime" SG_ 560 FR_FreespaceSectorDistance291 60;
BA_ "GenSigCycleTime" SG_ 560 FR_FreespaceSectorKinestate290 60;
BA_ "GenSigCycleTime" SG_ 560 FR_FreespaceSectorConRidence290 60;
BA_ "GenSigCycleTime" SG_ 560 FR_FreespaceSectorDistance290 60;
BA_ "GenSigCycleTime" SG_ 560 FR_FreespaceSectorKinestate289 60;
BA_ "GenSigCycleTime" SG_ 560 FR_FreespaceSectorConRidence289 60;
BA_ "GenSigCycleTime" SG_ 560 FR_FreespaceSectorDistance289 60;
BA_ "GenSigCycleTime" SG_ 560 FR_FreespaceSectorKinestate288 60;
BA_ "GenSigCycleTime" SG_ 560 FR_FreespaceSectorConRidence288 60;
BA_ "GenSigCycleTime" SG_ 560 FR_FreespaceSectorDistance288 60;
BA_ "GenSigCycleTime" SG_ 560 FR_FreespaceSectorKinestate287 60;
BA_ "GenSigCycleTime" SG_ 560 FR_FreespaceSectorConRidence287 60;
BA_ "GenSigCycleTime" SG_ 560 FR_FreespaceSectorDistance287 60;
BA_ "GenSigCycleTime" SG_ 560 FR_FreespaceSectorKinestate286 60;
BA_ "GenSigCycleTime" SG_ 560 FR_FreespaceSectorConRidence286 60;
BA_ "GenSigCycleTime" SG_ 560 FR_FreespaceSectorDistance286 60;
BA_ "GenSigCycleTime" SG_ 560 FR_FreespaceSectorKinestate285 60;
BA_ "GenSigCycleTime" SG_ 560 FR_FreespaceSectorConRidence285 60;
BA_ "GenSigCycleTime" SG_ 560 FR_FreespaceSectorDistance285 60;
BA_ "GenSigCycleTime" SG_ 560 FR_FreespaceSectorKinestate284 60;
BA_ "GenSigCycleTime" SG_ 560 FR_FreespaceSectorConRidence284 60;
BA_ "GenSigCycleTime" SG_ 560 FR_FreespaceSectorDistance284 60;
BA_ "GenSigCycleTime" SG_ 560 FR_FreespaceSectorKinestate283 60;
BA_ "GenSigCycleTime" SG_ 560 FR_FreespaceSectorConRidence283 60;
BA_ "GenSigCycleTime" SG_ 560 FR_FreespaceSectorDistance283 60;
BA_ "GenSigCycleTime" SG_ 560 FR_FreespaceSectorKinestate282 60;
BA_ "GenSigCycleTime" SG_ 560 FR_FreespaceSectorConRidence282 60;
BA_ "GenSigCycleTime" SG_ 560 FR_FreespaceSectorDistance282 60;
BA_ "GenSigCycleTime" SG_ 560 FR_FreespaceSectorKinestate281 60;
BA_ "GenSigCycleTime" SG_ 560 FR_FreespaceSectorConRidence281 60;
BA_ "GenSigCycleTime" SG_ 560 FR_FreespaceSectorDistance281 60;
BA_ "GenSigCycleTime" SG_ 560 FR_FreespaceSectorKinestate280 60;
BA_ "GenSigCycleTime" SG_ 560 FR_FreespaceSectorConRidence280 60;
BA_ "GenSigCycleTime" SG_ 560 FR_FreespaceSectorDistance280 60;
BA_ "GenSigCycleTime" SG_ 560 FR_FreespaceSectorKinestate279 60;
BA_ "GenSigCycleTime" SG_ 560 FR_FreespaceSectorConRidence279 60;
BA_ "GenSigCycleTime" SG_ 560 FR_FreespaceSectorDistance279 60;
BA_ "GenSigCycleTime" SG_ 560 FR_FreespaceSectorKinestate278 60;
BA_ "GenSigCycleTime" SG_ 560 FR_FreespaceSectorConRidence278 60;
BA_ "GenSigCycleTime" SG_ 560 FR_FreespaceSectorDistance278 60;
BA_ "GenSigCycleTime" SG_ 560 FR_FreespaceSectorKinestate277 60;
BA_ "GenSigCycleTime" SG_ 560 FR_FreespaceSectorConRidence277 60;
BA_ "GenSigCycleTime" SG_ 560 FR_FreespaceSectorDistance277 60;
BA_ "GenSigCycleTime" SG_ 560 FR_FreespaceSectorKinestate276 60;
BA_ "GenSigCycleTime" SG_ 560 FR_FreespaceSectorConRidence276 60;
BA_ "GenSigCycleTime" SG_ 560 FR_FreespaceSectorDistance276 60;
BA_ "GenSigCycleTime" SG_ 560 FR_FreespaceSectorKinestate275 60;
BA_ "GenSigCycleTime" SG_ 560 FR_FreespaceSectorConRidence275 60;
BA_ "GenSigCycleTime" SG_ 560 FR_FreespaceSectorDistance275 60;
BA_ "GenSigCycleTime" SG_ 560 FR_FreespaceSectorKinestate274 60;
BA_ "GenSigCycleTime" SG_ 560 FR_FreespaceSectorConRidence274 60;
BA_ "GenSigCycleTime" SG_ 560 FR_FreespaceSectorDistance274 60;
BA_ "GenSigCycleTime" SG_ 560 FR_FreespaceSectorKinestate273 60;
BA_ "GenSigCycleTime" SG_ 560 FR_FreespaceSectorConRidence273 60;
BA_ "GenSigCycleTime" SG_ 560 FR_FreespaceSectorDistance273 60;
BA_ "GenSigCycleTime" SG_ 561 FR_CRCCheck_231 60;
BA_ "GenSigCycleTime" SG_ 561 FR_RollingCounter_231 60;
BA_ "GenSigCycleTime" SG_ 561 FR_FreespaceSectorKinestate340 60;
BA_ "GenSigCycleTime" SG_ 561 FR_FreespaceSectorConRidence340 60;
BA_ "GenSigCycleTime" SG_ 561 FR_FreespaceSectorDistance340 60;
BA_ "GenSigCycleTime" SG_ 561 FR_FreespaceSectorKinestate339 60;
BA_ "GenSigCycleTime" SG_ 561 FR_FreespaceSectorConRidence339 60;
BA_ "GenSigCycleTime" SG_ 561 FR_FreespaceSectorDistance339 60;
BA_ "GenSigCycleTime" SG_ 561 FR_FreespaceSectorKinestate338 60;
BA_ "GenSigCycleTime" SG_ 561 FR_FreespaceSectorConRidence338 60;
BA_ "GenSigCycleTime" SG_ 561 FR_FreespaceSectorDistance338 60;
BA_ "GenSigCycleTime" SG_ 561 FR_FreespaceSectorKinestate337 60;
BA_ "GenSigCycleTime" SG_ 561 FR_FreespaceSectorConRidence337 60;
BA_ "GenSigCycleTime" SG_ 561 FR_FreespaceSectorDistance337 60;
BA_ "GenSigCycleTime" SG_ 561 FR_FreespaceSectorKinestate336 60;
BA_ "GenSigCycleTime" SG_ 561 FR_FreespaceSectorConRidence336 60;
BA_ "GenSigCycleTime" SG_ 561 FR_FreespaceSectorDistance336 60;
BA_ "GenSigCycleTime" SG_ 561 FR_FreespaceSectorKinestate335 60;
BA_ "GenSigCycleTime" SG_ 561 FR_FreespaceSectorConRidence335 60;
BA_ "GenSigCycleTime" SG_ 561 FR_FreespaceSectorDistance335 60;
BA_ "GenSigCycleTime" SG_ 561 FR_FreespaceSectorKinestate334 60;
BA_ "GenSigCycleTime" SG_ 561 FR_FreespaceSectorConRidence334 60;
BA_ "GenSigCycleTime" SG_ 561 FR_FreespaceSectorDistance334 60;
BA_ "GenSigCycleTime" SG_ 561 FR_FreespaceSectorKinestate333 60;
BA_ "GenSigCycleTime" SG_ 561 FR_FreespaceSectorConRidence333 60;
BA_ "GenSigCycleTime" SG_ 561 FR_FreespaceSectorDistance333 60;
BA_ "GenSigCycleTime" SG_ 561 FR_FreespaceSectorKinestate332 60;
BA_ "GenSigCycleTime" SG_ 561 FR_FreespaceSectorConRidence332 60;
BA_ "GenSigCycleTime" SG_ 561 FR_FreespaceSectorDistance332 60;
BA_ "GenSigCycleTime" SG_ 561 FR_FreespaceSectorKinestate331 60;
BA_ "GenSigCycleTime" SG_ 561 FR_FreespaceSectorConRidence331 60;
BA_ "GenSigCycleTime" SG_ 561 FR_FreespaceSectorDistance331 60;
BA_ "GenSigCycleTime" SG_ 561 FR_FreespaceSectorKinestate330 60;
BA_ "GenSigCycleTime" SG_ 561 FR_FreespaceSectorConRidence330 60;
BA_ "GenSigCycleTime" SG_ 561 FR_FreespaceSectorDistance330 60;
BA_ "GenSigCycleTime" SG_ 561 FR_FreespaceSectorKinestate329 60;
BA_ "GenSigCycleTime" SG_ 561 FR_FreespaceSectorConRidence329 60;
BA_ "GenSigCycleTime" SG_ 561 FR_FreespaceSectorDistance329 60;
BA_ "GenSigCycleTime" SG_ 561 FR_FreespaceSectorKinestate328 60;
BA_ "GenSigCycleTime" SG_ 561 FR_FreespaceSectorConRidence328 60;
BA_ "GenSigCycleTime" SG_ 561 FR_FreespaceSectorDistance328 60;
BA_ "GenSigCycleTime" SG_ 561 FR_FreespaceSectorKinestate327 60;
BA_ "GenSigCycleTime" SG_ 561 FR_FreespaceSectorConRidence327 60;
BA_ "GenSigCycleTime" SG_ 561 FR_FreespaceSectorDistance327 60;
BA_ "GenSigCycleTime" SG_ 561 FR_FreespaceSectorKinestate326 60;
BA_ "GenSigCycleTime" SG_ 561 FR_FreespaceSectorConRidence326 60;
BA_ "GenSigCycleTime" SG_ 561 FR_FreespaceSectorDistance326 60;
BA_ "GenSigCycleTime" SG_ 561 FR_FreespaceSectorKinestate325 60;
BA_ "GenSigCycleTime" SG_ 561 FR_FreespaceSectorConRidence325 60;
BA_ "GenSigCycleTime" SG_ 561 FR_FreespaceSectorDistance325 60;
BA_ "GenSigCycleTime" SG_ 561 FR_FreespaceSectorKinestate324 60;
BA_ "GenSigCycleTime" SG_ 561 FR_FreespaceSectorConRidence324 60;
BA_ "GenSigCycleTime" SG_ 561 FR_FreespaceSectorDistance324 60;
BA_ "GenSigCycleTime" SG_ 561 FR_FreespaceSectorKinestate323 60;
BA_ "GenSigCycleTime" SG_ 561 FR_FreespaceSectorConRidence323 60;
BA_ "GenSigCycleTime" SG_ 561 FR_FreespaceSectorDistance323 60;
BA_ "GenSigCycleTime" SG_ 561 FR_FreespaceSectorKinestate322 60;
BA_ "GenSigCycleTime" SG_ 561 FR_FreespaceSectorConRidence322 60;
BA_ "GenSigCycleTime" SG_ 561 FR_FreespaceSectorDistance322 60;
BA_ "GenSigCycleTime" SG_ 561 FR_FreespaceSectorKinestate321 60;
BA_ "GenSigCycleTime" SG_ 561 FR_FreespaceSectorConRidence321 60;
BA_ "GenSigCycleTime" SG_ 561 FR_FreespaceSectorDistance321 60;
BA_ "GenSigCycleTime" SG_ 561 FR_FreespaceSectorKinestate320 60;
BA_ "GenSigCycleTime" SG_ 561 FR_FreespaceSectorConRidence320 60;
BA_ "GenSigCycleTime" SG_ 561 FR_FreespaceSectorDistance320 60;
BA_ "GenSigCycleTime" SG_ 561 FR_FreespaceSectorKinestate319 60;
BA_ "GenSigCycleTime" SG_ 561 FR_FreespaceSectorConRidence319 60;
BA_ "GenSigCycleTime" SG_ 561 FR_FreespaceSectorDistance319 60;
BA_ "GenSigCycleTime" SG_ 561 FR_FreespaceSectorKinestate318 60;
BA_ "GenSigCycleTime" SG_ 561 FR_FreespaceSectorConRidence318 60;
BA_ "GenSigCycleTime" SG_ 561 FR_FreespaceSectorDistance318 60;
BA_ "GenSigCycleTime" SG_ 561 FR_FreespaceSectorKinestate317 60;
BA_ "GenSigCycleTime" SG_ 561 FR_FreespaceSectorConRidence317 60;
BA_ "GenSigCycleTime" SG_ 561 FR_FreespaceSectorDistance317 60;
BA_ "GenSigCycleTime" SG_ 561 FR_FreespaceSectorKinestate316 60;
BA_ "GenSigCycleTime" SG_ 561 FR_FreespaceSectorConRidence316 60;
BA_ "GenSigCycleTime" SG_ 561 FR_FreespaceSectorDistance316 60;
BA_ "GenSigCycleTime" SG_ 561 FR_FreespaceSectorKinestate315 60;
BA_ "GenSigCycleTime" SG_ 561 FR_FreespaceSectorConRidence315 60;
BA_ "GenSigCycleTime" SG_ 561 FR_FreespaceSectorDistance315 60;
BA_ "GenSigCycleTime" SG_ 561 FR_FreespaceSectorKinestate314 60;
BA_ "GenSigCycleTime" SG_ 561 FR_FreespaceSectorConRidence314 60;
BA_ "GenSigCycleTime" SG_ 561 FR_FreespaceSectorDistance314 60;
BA_ "GenSigCycleTime" SG_ 561 FR_FreespaceSectorKinestate313 60;
BA_ "GenSigCycleTime" SG_ 561 FR_FreespaceSectorConRidence313 60;
BA_ "GenSigCycleTime" SG_ 561 FR_FreespaceSectorDistance313 60;
BA_ "GenSigCycleTime" SG_ 561 FR_FreespaceSectorKinestate312 60;
BA_ "GenSigCycleTime" SG_ 561 FR_FreespaceSectorConRidence312 60;
BA_ "GenSigCycleTime" SG_ 561 FR_FreespaceSectorDistance312 60;
BA_ "GenSigCycleTime" SG_ 561 FR_FreespaceSectorKinestate311 60;
BA_ "GenSigCycleTime" SG_ 561 FR_FreespaceSectorConRidence311 60;
BA_ "GenSigCycleTime" SG_ 561 FR_FreespaceSectorDistance311 60;
BA_ "GenSigCycleTime" SG_ 561 FR_FreespaceSectorKinestate310 60;
BA_ "GenSigCycleTime" SG_ 561 FR_FreespaceSectorConRidence310 60;
BA_ "GenSigCycleTime" SG_ 561 FR_FreespaceSectorDistance310 60;
BA_ "GenSigCycleTime" SG_ 561 FR_FreespaceSectorKinestate309 60;
BA_ "GenSigCycleTime" SG_ 561 FR_FreespaceSectorConRidence309 60;
BA_ "GenSigCycleTime" SG_ 561 FR_FreespaceSectorDistance309 60;
BA_ "GenSigCycleTime" SG_ 561 FR_FreespaceSectorKinestate308 60;
BA_ "GenSigCycleTime" SG_ 561 FR_FreespaceSectorConRidence308 60;
BA_ "GenSigCycleTime" SG_ 561 FR_FreespaceSectorDistance308 60;
BA_ "GenSigCycleTime" SG_ 561 FR_FreespaceSectorKinestate307 60;
BA_ "GenSigCycleTime" SG_ 561 FR_FreespaceSectorConRidence307 60;
BA_ "GenSigCycleTime" SG_ 561 FR_FreespaceSectorDistance307 60;
BA_ "GenSigCycleTime" SG_ 562 FR_CRCCheck_232 60;
BA_ "GenSigCycleTime" SG_ 562 FR_RollingCounter_232 60;
BA_ "GenSigCycleTime" SG_ 562 FR_FreespaceSectorKinestate360 60;
BA_ "GenSigCycleTime" SG_ 562 FR_FreespaceSectorConRidence360 60;
BA_ "GenSigCycleTime" SG_ 562 FR_FreespaceSectorDistance360 60;
BA_ "GenSigCycleTime" SG_ 562 FR_FreespaceSectorKinestate359 60;
BA_ "GenSigCycleTime" SG_ 562 FR_FreespaceSectorConRidence359 60;
BA_ "GenSigCycleTime" SG_ 562 FR_FreespaceSectorDistance359 60;
BA_ "GenSigCycleTime" SG_ 562 FR_FreespaceSectorKinestate358 60;
BA_ "GenSigCycleTime" SG_ 562 FR_FreespaceSectorConRidence358 60;
BA_ "GenSigCycleTime" SG_ 562 FR_FreespaceSectorDistance358 60;
BA_ "GenSigCycleTime" SG_ 562 FR_FreespaceSectorKinestate357 60;
BA_ "GenSigCycleTime" SG_ 562 FR_FreespaceSectorConRidence357 60;
BA_ "GenSigCycleTime" SG_ 562 FR_FreespaceSectorDistance357 60;
BA_ "GenSigCycleTime" SG_ 562 FR_FreespaceSectorKinestate356 60;
BA_ "GenSigCycleTime" SG_ 562 FR_FreespaceSectorConRidence356 60;
BA_ "GenSigCycleTime" SG_ 562 FR_FreespaceSectorDistance356 60;
BA_ "GenSigCycleTime" SG_ 562 FR_FreespaceSectorKinestate355 60;
BA_ "GenSigCycleTime" SG_ 562 FR_FreespaceSectorConRidence355 60;
BA_ "GenSigCycleTime" SG_ 562 FR_FreespaceSectorDistance355 60;
BA_ "GenSigCycleTime" SG_ 562 FR_FreespaceSectorKinestate354 60;
BA_ "GenSigCycleTime" SG_ 562 FR_FreespaceSectorConRidence354 60;
BA_ "GenSigCycleTime" SG_ 562 FR_FreespaceSectorDistance354 60;
BA_ "GenSigCycleTime" SG_ 562 FR_FreespaceSectorKinestate353 60;
BA_ "GenSigCycleTime" SG_ 562 FR_FreespaceSectorConRidence353 60;
BA_ "GenSigCycleTime" SG_ 562 FR_FreespaceSectorDistance353 60;
BA_ "GenSigCycleTime" SG_ 562 FR_FreespaceSectorKinestate352 60;
BA_ "GenSigCycleTime" SG_ 562 FR_FreespaceSectorConRidence352 60;
BA_ "GenSigCycleTime" SG_ 562 FR_FreespaceSectorDistance352 60;
BA_ "GenSigCycleTime" SG_ 562 FR_FreespaceSectorKinestate351 60;
BA_ "GenSigCycleTime" SG_ 562 FR_FreespaceSectorConRidence351 60;
BA_ "GenSigCycleTime" SG_ 562 FR_FreespaceSectorDistance351 60;
BA_ "GenSigCycleTime" SG_ 562 FR_FreespaceSectorKinestate350 60;
BA_ "GenSigCycleTime" SG_ 562 FR_FreespaceSectorConRidence350 60;
BA_ "GenSigCycleTime" SG_ 562 FR_FreespaceSectorDistance350 60;
BA_ "GenSigCycleTime" SG_ 562 FR_FreespaceSectorKinestate349 60;
BA_ "GenSigCycleTime" SG_ 562 FR_FreespaceSectorConRidence349 60;
BA_ "GenSigCycleTime" SG_ 562 FR_FreespaceSectorDistance349 60;
BA_ "GenSigCycleTime" SG_ 562 FR_FreespaceSectorKinestate348 60;
BA_ "GenSigCycleTime" SG_ 562 FR_FreespaceSectorConRidence348 60;
BA_ "GenSigCycleTime" SG_ 562 FR_FreespaceSectorDistance348 60;
BA_ "GenSigCycleTime" SG_ 562 FR_FreespaceSectorKinestate347 60;
BA_ "GenSigCycleTime" SG_ 562 FR_FreespaceSectorConRidence347 60;
BA_ "GenSigCycleTime" SG_ 562 FR_FreespaceSectorDistance347 60;
BA_ "GenSigCycleTime" SG_ 562 FR_FreespaceSectorKinestate346 60;
BA_ "GenSigCycleTime" SG_ 562 FR_FreespaceSectorConRidence346 60;
BA_ "GenSigCycleTime" SG_ 562 FR_FreespaceSectorDistance346 60;
BA_ "GenSigCycleTime" SG_ 562 FR_FreespaceSectorKinestate345 60;
BA_ "GenSigCycleTime" SG_ 562 FR_FreespaceSectorConRidence345 60;
BA_ "GenSigCycleTime" SG_ 562 FR_FreespaceSectorDistance345 60;
BA_ "GenSigCycleTime" SG_ 562 FR_FreespaceSectorKinestate344 60;
BA_ "GenSigCycleTime" SG_ 562 FR_FreespaceSectorConRidence344 60;
BA_ "GenSigCycleTime" SG_ 562 FR_FreespaceSectorDistance344 60;
BA_ "GenSigCycleTime" SG_ 562 FR_FreespaceSectorKinestate343 60;
BA_ "GenSigCycleTime" SG_ 562 FR_FreespaceSectorConRidence343 60;
BA_ "GenSigCycleTime" SG_ 562 FR_FreespaceSectorDistance343 60;
BA_ "GenSigCycleTime" SG_ 562 FR_FreespaceSectorKinestate342 60;
BA_ "GenSigCycleTime" SG_ 562 FR_FreespaceSectorConRidence342 60;
BA_ "GenSigCycleTime" SG_ 562 FR_FreespaceSectorDistance342 60;
BA_ "GenSigCycleTime" SG_ 562 FR_FreespaceSectorKinestate341 60;
BA_ "GenSigCycleTime" SG_ 562 FR_FreespaceSectorConRidence341 60;
BA_ "GenSigCycleTime" SG_ 562 FR_FreespaceSectorDistance341 60;
BA_ "GenSigCycleTime" SG_ 570 FR_CRCCheck_23A 60;
BA_ "GenSigCycleTime" SG_ 570 FR_RollingCounter_23A 60;
BA_ "GenSigCycleTime" SG_ 570 FR__FronRightGuardrail_Dy 60;
BA_ "GenSigCycleTime" SG_ 570 FR_FrontRightGuardrailConfidenc 60;
BA_ "GenSigCycleTime" SG_ 570 FR__FronRightGuardrail_End 60;
BA_ "GenSigCycleTime" SG_ 570 FR__FronRightGuardrail_Start 60;
BA_ "GenSigStartValue" SG_ 570 FR_FrontRightGuardrailC3 2047;
BA_ "GenSigCycleTime" SG_ 570 FR_FrontRightGuardrailC3 60;
BA_ "GenSigStartValue" SG_ 570 FR_FrontRightGuardrailC2 2047;
BA_ "GenSigCycleTime" SG_ 570 FR_FrontRightGuardrailC2 60;
BA_ "GenSigStartValue" SG_ 570 FR_FrontRightGuardrailC1 2047;
BA_ "GenSigCycleTime" SG_ 570 FR_FrontRightGuardrailC1 60;
BA_ "GenSigCycleTime" SG_ 570 FR_FrontRightGuardrailC0 60;
BA_ "GenSigCycleTime" SG_ 570 FR_FrontLeftGuardrailConfidence 60;
BA_ "GenSigCycleTime" SG_ 570 FR__FrontLeftGuardrail_Dy 60;
BA_ "GenSigCycleTime" SG_ 570 FR__FrontLeftGuardrail_End 60;
BA_ "GenSigCycleTime" SG_ 570 FR__FrontLeftGuardrail_Start 60;
BA_ "GenSigStartValue" SG_ 570 FR_FrontLeftGuardrailC3 2047;
BA_ "GenSigCycleTime" SG_ 570 FR_FrontLeftGuardrailC3 60;
BA_ "GenSigStartValue" SG_ 570 FR_FrontLeftGuardrailC2 2047;
BA_ "GenSigCycleTime" SG_ 570 FR_FrontLeftGuardrailC2 60;
BA_ "GenSigStartValue" SG_ 570 FR_FrontLeftGuardrailC1 2047;
BA_ "GenSigCycleTime" SG_ 570 FR_FrontLeftGuardrailC1 60;
BA_ "GenSigCycleTime" SG_ 570 FR_FrontLeftGuardrailC0 60;
BA_ "GenSigCycleTime" SG_ 571 FR_H_FR_Hametime 60;
BA_ "GenSigCycleTime" SG_ 571 FR_H_ObjCount 60;
BA_ "GenSigCycleTime" SG_ 571 FR_H_FR_HameCount 60;
BA_ "GenSigCycleTime" SG_ 571 FR_WorkSenceMode 60;
BA_ "GenSigCycleTime" SG_ 571 FR_CRCCheck_23B 60;
BA_ "GenSigCycleTime" SG_ 571 FR_RollingCounter_23B 60;
BA_ "GenSigCycleTime" SG_ 571 FR_SenceMode 60;
BA_ "GenSigCycleTime" SG_ 571 FR_MisAlignment 60;
BA_ "GenSigCycleTime" SG_ 571 FR_WorkMode 60;
BA_ "GenSigInvalidValue" SG_ 571 FR_RadarFailureStatus "7";
BA_ "GenSigCycleTime" SG_ 571 FR_RadarFailureStatus 60;
BA_ "GenSigInvalidValue" SG_ 571 FR_FRadarCalibrationStatus "3";
BA_ "GenSigCycleTime" SG_ 571 FR_FRadarCalibrationStatus 60;
BA_ "GenSigInvalidValue" SG_ 572 FR_Offset_invalid_reason "NA";
BA_ "GenSigCycleTime" SG_ 572 FR_Offset_invalid_reason 60;
BA_ "GenSigCycleTime" SG_ 572 FR_MCUTiStamp 60;
BA_ "GenSigCycleTime" SG_ 572 FR_SyncTiStamp 60;
BA_ "GenSigCycleTime" SG_ 572 FR_H_CRCCheck_23C 60;
BA_ "GenSigCycleTime" SG_ 572 FR_H_RollingCounter_23C 60;
BA_ "GenSigCycleTime" SG_ 572 FR_Obj_TFLTiOut 60;
BA_ "GenSigCycleTime" SG_ 572 FR_Obj_TFLTiLeap 60;
BA_ "GenSigCycleTime" SG_ 572 FR_Obj_TFLTiBas 60;
BA_ "GenSigCycleTime" SG_ 572 FR_Obj_TFLTiStamp 60;
BA_ "GenSigCycleTime" SG_ 573 FR_H_CRCCheck_23D 60;
BA_ "GenSigCycleTime" SG_ 573 FR_H_RollingCounter_23D 60;
BA_ "GenSigCycleTime" SG_ 573 FR_FS_TFLTiOut 60;
BA_ "GenSigCycleTime" SG_ 573 FR_FS_TFLTiLeap 60;
BA_ "GenSigCycleTime" SG_ 573 FR_FS_TFLTiBas 60;
BA_ "GenSigCycleTime" SG_ 573 FR_FS_TFLTiStamp 60;
BA_ "GenSigCycleTime" SG_ 574 FR_TimeMonit_64 60;
BA_ "GenSigCycleTime" SG_ 574 FR_TimeMonit_63 60;
BA_ "GenSigCycleTime" SG_ 574 FR_TimeMonit_62 60;
BA_ "GenSigCycleTime" SG_ 574 FR_TimeMonit_61 60;
BA_ "GenSigCycleTime" SG_ 574 FR_TimeMonit_60 60;
BA_ "GenSigCycleTime" SG_ 574 FR_TimeMonit_59 60;
BA_ "GenSigCycleTime" SG_ 574 FR_TimeMonit_58 60;
BA_ "GenSigCycleTime" SG_ 574 FR_TimeMonit_57 60;
BA_ "GenSigCycleTime" SG_ 574 FR_TimeMonit_56 60;
BA_ "GenSigCycleTime" SG_ 574 FR_TimeMonit_55 60;
BA_ "GenSigCycleTime" SG_ 574 FR_TimeMonit_54 60;
BA_ "GenSigCycleTime" SG_ 574 FR_TimeMonit_53 60;
BA_ "GenSigCycleTime" SG_ 574 FR_TimeMonit_52 60;
BA_ "GenSigCycleTime" SG_ 574 FR_TimeMonit_51 60;
BA_ "GenSigCycleTime" SG_ 574 FR_TimeMonit_50 60;
BA_ "GenSigCycleTime" SG_ 574 FR_TimeMonit_49 60;
BA_ "GenSigCycleTime" SG_ 574 FR_TimeMonit_48 60;
BA_ "GenSigCycleTime" SG_ 574 FR_TimeMonit_47 60;
BA_ "GenSigCycleTime" SG_ 574 FR_TimeMonit_46 60;
BA_ "GenSigCycleTime" SG_ 574 FR_TimeMonit_45 60;
BA_ "GenSigCycleTime" SG_ 574 FR_TimeMonit_44 60;
BA_ "GenSigCycleTime" SG_ 574 FR_TimeMonit_43 60;
BA_ "GenSigCycleTime" SG_ 574 FR_TimeMonit_42 60;
BA_ "GenSigCycleTime" SG_ 574 FR_TimeMonit_41 60;
BA_ "GenSigCycleTime" SG_ 574 FR_TimeMonit_40 60;
BA_ "GenSigCycleTime" SG_ 574 FR_TimeMonit_39 60;
BA_ "GenSigCycleTime" SG_ 574 FR_TimeMonit_38 60;
BA_ "GenSigCycleTime" SG_ 574 FR_TimeMonit_37 60;
BA_ "GenSigCycleTime" SG_ 574 FR_TimeMonit_36 60;
BA_ "GenSigCycleTime" SG_ 574 FR_TimeMonit_35 60;
BA_ "GenSigCycleTime" SG_ 574 FR_TimeMonit_34 60;
BA_ "GenSigCycleTime" SG_ 574 FR_TimeMonit_33 60;
BA_ "GenSigCycleTime" SG_ 574 FR_TimeMonit_32 60;
BA_ "GenSigCycleTime" SG_ 574 FR_TimeMonit_31 60;
BA_ "GenSigCycleTime" SG_ 574 FR_TimeMonit_30 60;
BA_ "GenSigCycleTime" SG_ 574 FR_TimeMonit_29 60;
BA_ "GenSigCycleTime" SG_ 574 FR_TimeMonit_28 60;
BA_ "GenSigCycleTime" SG_ 574 FR_TimeMonit_27 60;
BA_ "GenSigCycleTime" SG_ 574 FR_TimeMonit_26 60;
BA_ "GenSigCycleTime" SG_ 574 FR_TimeMonit_25 60;
BA_ "GenSigCycleTime" SG_ 574 FR_TimeMonit_24 60;
BA_ "GenSigCycleTime" SG_ 574 FR_TimeMonit_23 60;
BA_ "GenSigCycleTime" SG_ 574 FR_TimeMonit_22 60;
BA_ "GenSigCycleTime" SG_ 574 FR_TimeMonit_21 60;
BA_ "GenSigCycleTime" SG_ 574 FR_TimeMonit_20 60;
BA_ "GenSigCycleTime" SG_ 574 FR_TimeMonit_19 60;
BA_ "GenSigCycleTime" SG_ 574 FR_TimeMonit_18 60;
BA_ "GenSigCycleTime" SG_ 574 FR_TimeMonit_17 60;
BA_ "GenSigCycleTime" SG_ 574 FR_TimeMonit_16 60;
BA_ "GenSigCycleTime" SG_ 574 FR_TimeMonit_15 60;
BA_ "GenSigCycleTime" SG_ 574 FR_TimeMonit_14 60;
BA_ "GenSigCycleTime" SG_ 574 FR_TimeMonit_13 60;
BA_ "GenSigCycleTime" SG_ 574 FR_TimeMonit_12 60;
BA_ "GenSigCycleTime" SG_ 574 FR_TimeMonit_11 60;
BA_ "GenSigCycleTime" SG_ 574 FR_TimeMonit_10 60;
BA_ "GenSigCycleTime" SG_ 574 FR_TimeMonit_9 60;
BA_ "GenSigCycleTime" SG_ 574 FR_TimeMonit_8 60;
BA_ "GenSigCycleTime" SG_ 574 FR_TimeMonit_7 60;
BA_ "GenSigCycleTime" SG_ 574 FR_TimeMonit_6 60;
BA_ "GenSigCycleTime" SG_ 574 FR_TimeMonit_5 60;
BA_ "GenSigCycleTime" SG_ 574 FR_TimeMonit_4 60;
BA_ "GenSigCycleTime" SG_ 574 FR_TimeMonit_3 60;
BA_ "GenSigCycleTime" SG_ 574 FR_TimeMonit_2 60;
BA_ "GenSigCycleTime" SG_ 574 FR_TimeMonit_1 60;
BA_ "GenSigCycleTime" SG_ 575 FR_InterState 60;
BA_ "GenSigCycleTime" SG_ 575 FR_Temperature4 60;
BA_ "GenSigCycleTime" SG_ 575 FR_Temperature3 60;
BA_ "GenSigCycleTime" SG_ 575 FR_Temperature2 60;
BA_ "GenSigCycleTime" SG_ 575 FR_Temperature1 60;
BA_ "GenSigCycleTime" SG_ 575 FR_targetNum3 60;
BA_ "GenSigCycleTime" SG_ 575 FR_targetNum2 60;
BA_ "GenSigCycleTime" SG_ 575 FR_targetNum1 60;
BA_ "GenSigCycleTime" SG_ 575 FR_FR_voltage 60;
BA_ "GenSigCycleTime" SG_ 575 FR_PowerUpTime 60;
BA_ "GenSigCycleTime" SG_ 575 FR_InterVersion 60;
BA_ "GenSigCycleTime" SG_ 575 FR_Block_Frame 60;
BA_ "GenSigCycleTime" SG_ 575 FR_Block_State3 60;
BA_ "GenSigCycleTime" SG_ 575 FR_Block_State2 60;
BA_ "GenSigCycleTime" SG_ 575 FR_Block_State1 60;
BA_ "GenSigCycleTime" SG_ 575 FR_Azi_State 60;
BA_ "GenSigCycleTime" SG_ 575 FR_Pitch_State 60;
BA_ "GenSigCycleTime" SG_ 575 FR_Pitch_Angle_Comp2 60;
BA_ "GenSigCycleTime" SG_ 575 FR_Pitch_Angle_Comp1 60;
BA_ "GenSigCycleTime" SG_ 575 FR_Pitch_Angle_Accu 60;
BA_ "GenSigCycleTime" SG_ 575 FR_Azi_Angle_Comp2 60;
BA_ "GenSigCycleTime" SG_ 575 FR_Azi_Angle_Comp1 60;
BA_ "GenSigCycleTime" SG_ 575 FR_Azi_Angle_Accu 60;
BA_ "GenSigCycleTime" SG_ 575 FR_Calibration_State 60;
BA_ "GenSigCycleTime" SG_ 575 FR_Pitch_Angle_Store 60;
BA_ "GenSigCycleTime" SG_ 575 FR_Azi_Angle_Store 60;
BA_ "GenSigInvalidValue" SG_ 648 VIU_FL_CRCCheck_288 "NA";
BA_ "GenSigCycleTime" SG_ 648 VIU_FL_CRCCheck_288 40;
BA_ "GenSigInvalidValue" SG_ 648 VIU_FL_RollingCounter_288 "NA";
BA_ "GenSigCycleTime" SG_ 648 VIU_FL_RollingCounter_288 40;
BA_ "GenSigCycleTime" SG_ 648 BcmPwrStsFb 40;
BA_ "GenSigInvalidValue" SG_ 722 CdcTotMilg "16777215";
BA_ "GenSigCycleTime" SG_ 722 CdcTotMilg 100;
BA_ "GenSigInvalidValue" SG_ 759 TboxLocalTiVld "NA";
BA_ "GenSigCycleTime" SG_ 759 TboxLocalTiVld 1000;
BA_ "GenSigInvalidValue" SG_ 759 TboxLocalTiSec "NA";
BA_ "GenSigCycleTime" SG_ 759 TboxLocalTiSec 1000;
BA_ "GenSigInvalidValue" SG_ 759 TboxLocalTiMins "NA";
BA_ "GenSigCycleTime" SG_ 759 TboxLocalTiMins 1000;
BA_ "GenSigInvalidValue" SG_ 759 TboxLocalTiHr "NA";
BA_ "GenSigCycleTime" SG_ 759 TboxLocalTiHr 1000;
BA_ "GenSigInvalidValue" SG_ 759 TboxLocalTiDate "NA";
BA_ "GenSigCycleTime" SG_ 759 TboxLocalTiDate 1000;
BA_ "GenSigInvalidValue" SG_ 759 TboxLocalTiMth "NA";
BA_ "GenSigCycleTime" SG_ 759 TboxLocalTiMth 1000;
BA_ "GenSigInvalidValue" SG_ 759 TboxLocalTiYear "NA";
BA_ "GenSigCycleTime" SG_ 759 TboxLocalTiYear 1000;
BA_ "GenSigInvalidValue" SG_ 802 ECAStarLvl "255";
BA_ "GenSigCycleTime" SG_ 802 ECAStarLvl 100;
BA_ "GenSigInvalidValue" SG_ 802 ECASActLvlRR "NA";
BA_ "GenSigCycleTime" SG_ 802 ECASActLvlRR 100;
BA_ "GenSigInvalidValue" SG_ 802 ECASActLvlRL "NA";
BA_ "GenSigCycleTime" SG_ 802 ECASActLvlRL 100;
BA_ "GenSigInvalidValue" SG_ 802 ECASActLvlFR "NA";
BA_ "GenSigCycleTime" SG_ 802 ECASActLvlFR 100;
BA_ "GenSigInvalidValue" SG_ 802 ECASActLvlFL "NA";
BA_ "GenSigCycleTime" SG_ 802 ECASActLvlFL 100;
BA_ "GenSigInvalidValue" SG_ 802 EcasModeFB "NA";
BA_ "GenSigCycleTime" SG_ 802 EcasModeFB 100;
BA_ "GenSigInvalidValue" SG_ 802 EcasModeCHASts "NA";
BA_ "GenSigCycleTime" SG_ 802 EcasModeCHASts 100;
BA_ "GenSigInvalidValue" SG_ 802 ECASAdjBySpd "NA";
BA_ "GenSigCycleTime" SG_ 802 ECASAdjBySpd 100;
BA_ "GenSigInvalidValue" SG_ 821 VCUGearShiftPositon "15";
BA_ "GenSigCycleTime" SG_ 821 VCUGearShiftPositon 100;
BA_ "GenSigInvalidValue" SG_ 821 VCU_CRCCheck_335 "NA";
BA_ "GenSigCycleTime" SG_ 821 VCU_CRCCheck_335 100;
BA_ "GenSigInvalidValue" SG_ 821 VCU_RollingCounter_335 "NA";
BA_ "GenSigCycleTime" SG_ 821 VCU_RollingCounter_335 100;
BA_ "GenSigInvalidValue" SG_ 821 VCUShiftPostionValid "1";
BA_ "GenSigCycleTime" SG_ 821 VCUShiftPostionValid 100;
BA_ "GenSigInvalidValue" SG_ 919 OTA_CRCCheck_397 "NA";
BA_ "GenSigCycleTime" SG_ 919 OTA_CRCCheck_397 500;
BA_ "GenSigInvalidValue" SG_ 919 OTA_RollingCounter_397 "NA";
BA_ "GenSigCycleTime" SG_ 919 OTA_RollingCounter_397 500;
BA_ "GenSigInvalidValue" SG_ 919 VIU_FL_OTAmode "NA";
BA_ "GenSigCycleTime" SG_ 919 VIU_FL_OTAmode 500;
BA_ "GenSigInvalidValue" SG_ 1002 IR_Brightness "NA";
BA_ "GenSigCycleTime" SG_ 1002 IR_Brightness 100;
BA_ "GenSigInvalidValue" SG_ 1002 FW_Brightness "NA";
BA_ "GenSigCycleTime" SG_ 1002 FW_Brightness 100;
BA_ "GenSigInvalidValue" SG_ 1002 AMB_Brightness "NA";
BA_ "GenSigCycleTime" SG_ 1002 AMB_Brightness 100;
BA_ "GenSigInvalidValue" SG_ 1002 BCM_RainfallLevel "NA";
BA_ "GenSigCycleTime" SG_ 1002 BCM_RainfallLevel 100;
BA_ "GenSigInvalidValue" SG_ 1002 BCM_FrontWiperStatus "NA";
BA_ "GenSigCycleTime" SG_ 1002 BCM_FrontWiperStatus 100;
BA_ "GenSigInvalidValue" SG_ 1429 FR_H_NotSleep_BYTE7BIT2 "0";
BA_ "GenSigCycleTime" SG_ 1429 FR_H_NotSleep_BYTE7BIT2 1000;
BA_ "GenSigInvalidValue" SG_ 1429 FR_H_NotSleep_BYTE7BIT1 "0";
BA_ "GenSigCycleTime" SG_ 1429 FR_H_NotSleep_BYTE7BIT1 1000;
BA_ "GenSigInvalidValue" SG_ 1429 FR_H_NotSleep_BYTE7BIT0 "0";
BA_ "GenSigCycleTime" SG_ 1429 FR_H_NotSleep_BYTE7BIT0 1000;
BA_ "GenSigInvalidValue" SG_ 1429 FR_H_WakeUp_BYTE3BIT1 "0";
BA_ "GenSigCycleTime" SG_ 1429 FR_H_WakeUp_BYTE3BIT1 1000;
BA_ "GenSigInvalidValue" SG_ 1429 FR_H_WakeUp_BYTE3BIT0 "0";
BA_ "GenSigCycleTime" SG_ 1429 FR_H_WakeUp_BYTE3BIT0 1000;
BA_ "GenSigCycleTime" SG_ 1692 FR_DTC2_Status 500;
BA_ "GenSigCycleTime" SG_ 1692 FR_DTC2_LowByte 500;
BA_ "GenSigCycleTime" SG_ 1692 FR_DTC2_MiddByte 500;
BA_ "GenSigCycleTime" SG_ 1692 FR_DTC2_HighByte 500;
BA_ "GenSigCycleTime" SG_ 1692 FR_DTC1_Status 500;
BA_ "GenSigCycleTime" SG_ 1692 FR_DTC1_LowByte 500;
BA_ "GenSigCycleTime" SG_ 1692 FR_DTC1_MiddByte 500;
BA_ "GenSigCycleTime" SG_ 1692 FR_DTC1_HighByte 500;
BA_ "GenSigInvalidValue" SG_ 1893 Diagnose_message_765 "NA";
BA_ "GenSigSendType" SG_ 1893 Diagnose_message_765 1;
BA_ "GenSigInvalidValue" SG_ 1901 Diagnose_message_76D "NA";
BA_ "GenSigSendType" SG_ 1901 Diagnose_message_76D 1;
BA_ "GenSigInvalidValue" SG_ 2015 Diagnose_message_7DF "NA";
BA_ "GenSigSendType" SG_ 2015 Diagnose_message_7DF 1;
VAL_ 570 FR__FronRightGuardrail_Dy 0 "-5-1" 120 "reserved" ;
VAL_ 570 FR__FrontLeftGuardrail_Dy 0 "-1-5" 121 "reserved" ;
VAL_ 571 FR_WorkSenceMode 0 "非地库模式
0x1=地库模式
0x2=切换中
0x3=Reserved" ;
VAL_ 571 FR_SenceMode 0 "unkown
0x1=地库模式
0x2=非地库模式
0x3=预留" ;
VAL_ 571 FR_MisAlignment 0 "Initial Value
0x1=未偏离
0x2=方位角偏离
0x3=俯仰角偏离
0x4=方位角和俯仰角均偏离" ;
VAL_ 571 FR_WorkMode 0 "Initial Value
0x1=行车模式
0x2=泊车模式
0x3=切换中" ;
VAL_ 571 FR_RadarFailureStatus 0 " no failure" 1 "fullBlind" 2 "" 3 "reversible failure" 4 " irrversible failure" 5 "vehicle information failure
0x6-0x7=Reserevd" ;
VAL_ 571 FR_FRadarCalibrationStatus 0 " Calibration is ok" 1 " Calibration In Process" 2 " Calibration never done" 3 "  Calibration Failed" ;
VAL_ 572 FR_Offset_invalid_reason 0 " valid " 1 "ptp loss" 2 "ptp error" 3 " Reserved" ;
VAL_ 572 FR_Obj_TFLTiOut 0 "no timeout" 1 "timeout" ;
VAL_ 573 FR_FS_TFLTiOut 0 "no timeout" 1 "timeout" ;
VAL_ 648 BcmPwrStsFb 0 "Off" 1 "Reserve" 2 "ON" 3 "Reserve" ;
VAL_ 759 TboxLocalTiVld 0 "Valid" 1 "Invalid" ;
VAL_ 802 EcasModeFB 0 "Normal;
0x1=sport;
0x2=off road;
0x3=comfort;
0x4=auto;
0x5=Access;
0x6=Loading mode;
0x7=Level;
0x8=Trailer mode;
0x9=maintenance mode
0xA=10%" 11 "20%" 12 "30%" 13 "40%" 14 "50%" 15 "60%" 16 "70%" 17 "80%" 18 "90%" 19 "100%" ;
VAL_ 802 EcasModeCHASts 0 "Idle" 1 "up" 2 "down" 3 "Switch fail" 4 "ready to Switch  " ;
VAL_ 802 ECASAdjBySpd 0 "Inactive" 1 "Active " ;
VAL_ 821 VCUGearShiftPositon 0 "Parking" 1 "Reverse" 2 "Neutral" 3 "D" 14 "Unreliable" 15 "Invalid" 4 "Reserved" ;
VAL_ 821 VCUShiftPostionValid 0 "Valid" 1 "Invalid " ;
VAL_ 919 VIU_FL_OTAmode 0 " OTAinactive " 1 "OTAmode" 2 " Reserved" ;
VAL_ 1002 IR_Brightness 0 "有效值" 254 "默认值" 255 "故障值" ;
VAL_ 1002 FW_Brightness 0 "有效值" 1022 "默认值" 1023 "故障值" ;
VAL_ 1002 AMB_Brightness 0 "有效值" 1022 "默认值" 1023 "故障值" ;
VAL_ 1002 BCM_RainfallLevel 0 "No rain" 1 "Level 1" 2 "Level 2" 3 "Level 3" 4 "Level 4" 5 "Level 5?" 6 "Level 6" 7 "Level 7" 8 "Level 8" 9 "Level 9" 10 "Level 10" 11 "Level 11" 12 "Level 12" 13 "level 13" 14 "init value" 15 "Invalid value" ;
VAL_ 1002 BCM_FrontWiperStatus 0 "OFF" 1 "雨刮最低速" 2 "雨刮低速" 3 "雨刮较高速" 4 "雨刮高速" 5 "Reserve" 15 "Invaild" ;
VAL_ 1429 FR_H_NotSleep_BYTE7BIT2 0 "Inactive" 1 "其他条件（包含外部/远程/本地功能请求及诊断模式）" ;
VAL_ 1429 FR_H_NotSleep_BYTE7BIT1 0 "Inactive" 1 "电源档位为ON档" ;
VAL_ 1429 FR_H_NotSleep_BYTE7BIT0 0 "Inactive" 1 "网络上其他节点NM报文不允许休眠" ;
VAL_ 1429 FR_H_WakeUp_BYTE3BIT1 0 "Inactive" 1 "电源档位为ON档" ;
VAL_ 1429 FR_H_WakeUp_BYTE3BIT0 0 "Inactive" 1 "NM报文唤醒" ;
